VERSION ""

NS_ :

BS_:

BU_: Vector__XXX

BA_DEF_ "BusType" STRING ;
BA_DEF_ BO_ "VFrameFormat" ENUM "StandardCAN","ExtendedCAN","reserved","J1939PG";
BA_DEF_DEF_ "BusType" "CAN";
BA_DEF_DEF_ "VFrameFormat" 0;

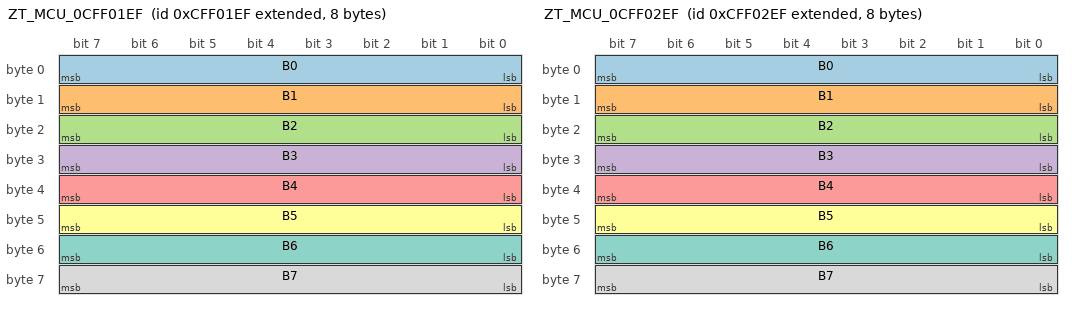
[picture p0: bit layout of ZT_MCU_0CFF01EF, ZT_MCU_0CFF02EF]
BO_ 2365522415 ZT_MCU_0CFF01EF: 8 Vector__XXX
 SG_ B0 : 0|8@1+ (1,0) [0|255] "" Vector__XXX
 SG_ B1 : 8|8@1+ (1,0) [0|255] "" Vector__XXX
 SG_ B2 : 16|8@1+ (1,0) [0|255] "" Vector__XXX
 SG_ B3 : 24|8@1+ (1,0) [0|255] "" Vector__XXX
 SG_ B4 : 32|8@1+ (1,0) [0|255] "" Vector__XXX
 SG_ B5 : 40|8@1+ (1,0) [0|255] "" Vector__XXX
 SG_ B6 : 48|8@1+ (1,0) [0|255] "" Vector__XXX
 SG_ B7 : 56|8@1+ (1,0) [0|255] "" Vector__XXX

BA_ "VFrameFormat" BO_ 2365522415 1;
CM_ BO_ 2365522415 "0x5C0002 中通新能源 > 中通物流 > 系统诊断 > 电机控制模块(MCU) | 部件: 电机控制模块(MCU)";

BO_ 2365522671 ZT_MCU_0CFF02EF: 8 Vector__XXX
 SG_ B0 : 0|8@1+ (1,0) [0|255] "" Vector__XXX
 SG_ B1 : 8|8@1+ (1,0) [0|255] "" Vector__XXX
 SG_ B2 : 16|8@1+ (1,0) [0|255] "" Vector__XXX
 SG_ B3 : 24|8@1+ (1,0) [0|255] "" Vector__XXX
 SG_ B4 : 32|8@1+ (1,0) [0|255] "" Vector__XXX
 SG_ B5 : 40|8@1+ (1,0) [0|255] "" Vector__XXX
 SG_ B6 : 48|8@1+ (1,0) [0|255] "" Vector__XXX
 SG_ B7 : 56|8@1+ (1,0) [0|255] "" Vector__XXX

BA_ "VFrameFormat" BO_ 2365522671 1;
CM_ BO_ 2365522671 "0x5C0002 中通新能源 > 中通物流 > 系统诊断 > 电机控制模块(MCU) | 部件: 电机控制模块(MCU)";

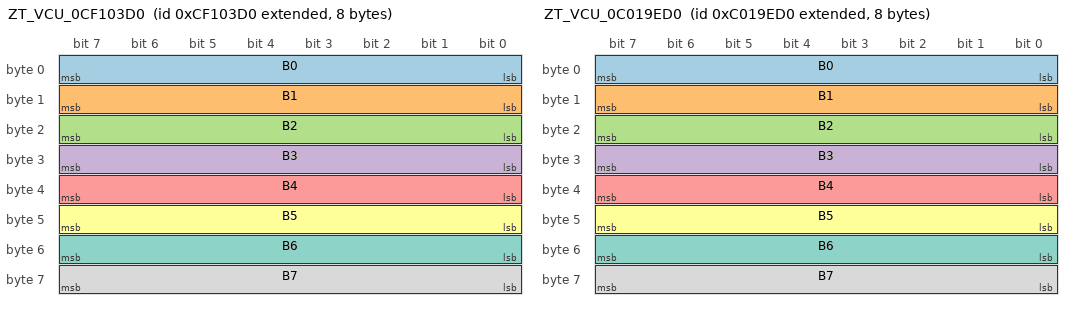
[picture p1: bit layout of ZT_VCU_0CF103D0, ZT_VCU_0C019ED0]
BO_ 2364605392 ZT_VCU_0CF103D0: 8 Vector__XXX
 SG_ B0 : 0|8@1+ (1,0) [0|255] "" Vector__XXX
 SG_ B1 : 8|8@1+ (1,0) [0|255] "" Vector__XXX
 SG_ B2 : 16|8@1+ (1,0) [0|255] "" Vector__XXX
 SG_ B3 : 24|8@1+ (1,0) [0|255] "" Vector__XXX
 SG_ B4 : 32|8@1+ (1,0) [0|255] "" Vector__XXX
 SG_ B5 : 40|8@1+ (1,0) [0|255] "" Vector__XXX
 SG_ B6 : 48|8@1+ (1,0) [0|255] "" Vector__XXX
 SG_ B7 : 56|8@1+ (1,0) [0|255] "" Vector__XXX

BA_ "VFrameFormat" BO_ 2364605392 1;
CM_ BO_ 2364605392 "0x5C0003 中通新能源 > 中通物流 > 系统诊断 > 整车控制模块(VCU) | 部件: 整车控制模块(VCU)";

BO_ 2348916432 ZT_VCU_0C019ED0: 8 Vector__XXX
 SG_ B0 : 0|8@1+ (1,0) [0|255] "" Vector__XXX
 SG_ B1 : 8|8@1+ (1,0) [0|255] "" Vector__XXX
 SG_ B2 : 16|8@1+ (1,0) [0|255] "" Vector__XXX
 SG_ B3 : 24|8@1+ (1,0) [0|255] "" Vector__XXX
 SG_ B4 : 32|8@1+ (1,0) [0|255] "" Vector__XXX
 SG_ B5 : 40|8@1+ (1,0) [0|255] "" Vector__XXX
 SG_ B6 : 48|8@1+ (1,0) [0|255] "" Vector__XXX
 SG_ B7 : 56|8@1+ (1,0) [0|255] "" Vector__XXX

BA_ "VFrameFormat" BO_ 2348916432 1;
CM_ BO_ 2348916432 "0x5C0003 中通新能源 > 中通物流 > 系统诊断 > 整车控制模块(VCU) | 部件: 整车控制模块(VCU)";

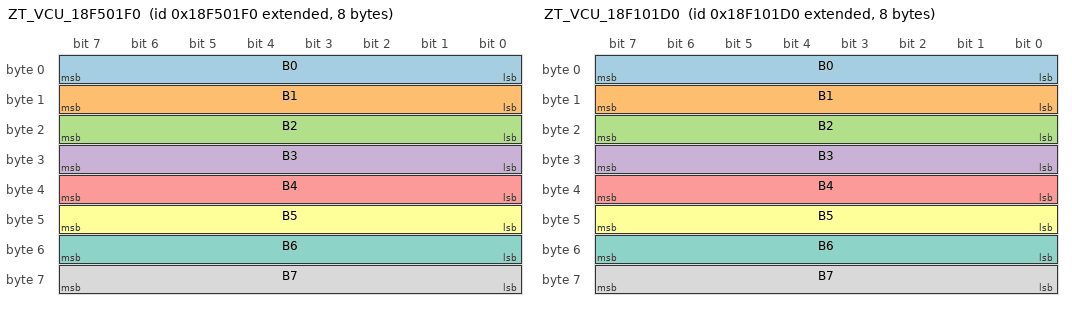
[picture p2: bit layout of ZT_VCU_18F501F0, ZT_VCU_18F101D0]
BO_ 2566193648 ZT_VCU_18F501F0: 8 Vector__XXX
 SG_ B0 : 0|8@1+ (1,0) [0|255] "" Vector__XXX
 SG_ B1 : 8|8@1+ (1,0) [0|255] "" Vector__XXX
 SG_ B2 : 16|8@1+ (1,0) [0|255] "" Vector__XXX
 SG_ B3 : 24|8@1+ (1,0) [0|255] "" Vector__XXX
 SG_ B4 : 32|8@1+ (1,0) [0|255] "" Vector__XXX
 SG_ B5 : 40|8@1+ (1,0) [0|255] "" Vector__XXX
 SG_ B6 : 48|8@1+ (1,0) [0|255] "" Vector__XXX
 SG_ B7 : 56|8@1+ (1,0) [0|255] "" Vector__XXX

BA_ "VFrameFormat" BO_ 2566193648 1;
CM_ BO_ 2566193648 "0x5C0003 中通新能源 > 中通物流 > 系统诊断 > 整车控制模块(VCU) | 部件: 整车控制模块(VCU)";

BO_ 2565931472 ZT_VCU_18F101D0: 8 Vector__XXX
 SG_ B0 : 0|8@1+ (1,0) [0|255] "" Vector__XXX
 SG_ B1 : 8|8@1+ (1,0) [0|255] "" Vector__XXX
 SG_ B2 : 16|8@1+ (1,0) [0|255] "" Vector__XXX
 SG_ B3 : 24|8@1+ (1,0) [0|255] "" Vector__XXX
 SG_ B4 : 32|8@1+ (1,0) [0|255] "" Vector__XXX
 SG_ B5 : 40|8@1+ (1,0) [0|255] "" Vector__XXX
 SG_ B6 : 48|8@1+ (1,0) [0|255] "" Vector__XXX
 SG_ B7 : 56|8@1+ (1,0) [0|255] "" Vector__XXX

BA_ "VFrameFormat" BO_ 2565931472 1;
CM_ BO_ 2565931472 "0x5C0003 中通新能源 > 中通物流 > 系统诊断 > 整车控制模块(VCU) | 部件: 整车控制模块(VCU)";

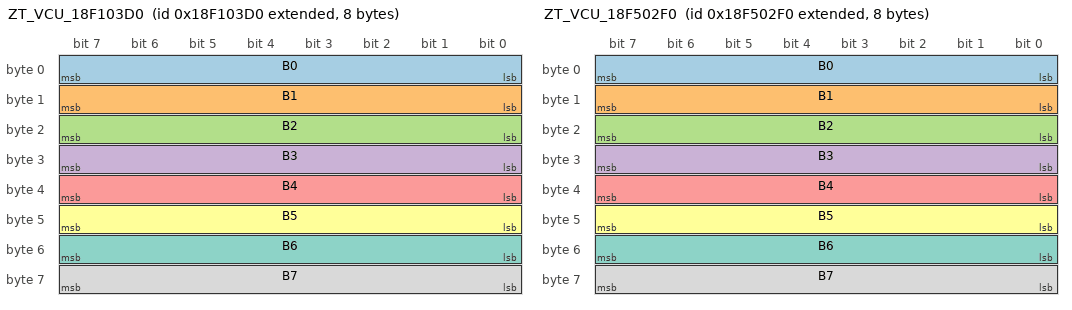
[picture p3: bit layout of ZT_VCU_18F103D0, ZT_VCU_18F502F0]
BO_ 2565931984 ZT_VCU_18F103D0: 8 Vector__XXX
 SG_ B0 : 0|8@1+ (1,0) [0|255] "" Vector__XXX
 SG_ B1 : 8|8@1+ (1,0) [0|255] "" Vector__XXX
 SG_ B2 : 16|8@1+ (1,0) [0|255] "" Vector__XXX
 SG_ B3 : 24|8@1+ (1,0) [0|255] "" Vector__XXX
 SG_ B4 : 32|8@1+ (1,0) [0|255] "" Vector__XXX
 SG_ B5 : 40|8@1+ (1,0) [0|255] "" Vector__XXX
 SG_ B6 : 48|8@1+ (1,0) [0|255] "" Vector__XXX
 SG_ B7 : 56|8@1+ (1,0) [0|255] "" Vector__XXX

BA_ "VFrameFormat" BO_ 2565931984 1;
CM_ BO_ 2565931984 "0x5C0003 中通新能源 > 中通物流 > 系统诊断 > 整车控制模块(VCU) | 部件: 整车控制模块(VCU)";

BO_ 2566193904 ZT_VCU_18F502F0: 8 Vector__XXX
 SG_ B0 : 0|8@1+ (1,0) [0|255] "" Vector__XXX
 SG_ B1 : 8|8@1+ (1,0) [0|255] "" Vector__XXX
 SG_ B2 : 16|8@1+ (1,0) [0|255] "" Vector__XXX
 SG_ B3 : 24|8@1+ (1,0) [0|255] "" Vector__XXX
 SG_ B4 : 32|8@1+ (1,0) [0|255] "" Vector__XXX
 SG_ B5 : 40|8@1+ (1,0) [0|255] "" Vector__XXX
 SG_ B6 : 48|8@1+ (1,0) [0|255] "" Vector__XXX
 SG_ B7 : 56|8@1+ (1,0) [0|255] "" Vector__XXX

BA_ "VFrameFormat" BO_ 2566193904 1;
CM_ BO_ 2566193904 "0x5C0003 中通新能源 > 中通物流 > 系统诊断 > 整车控制模块(VCU) | 部件: 整车控制模块(VCU)";

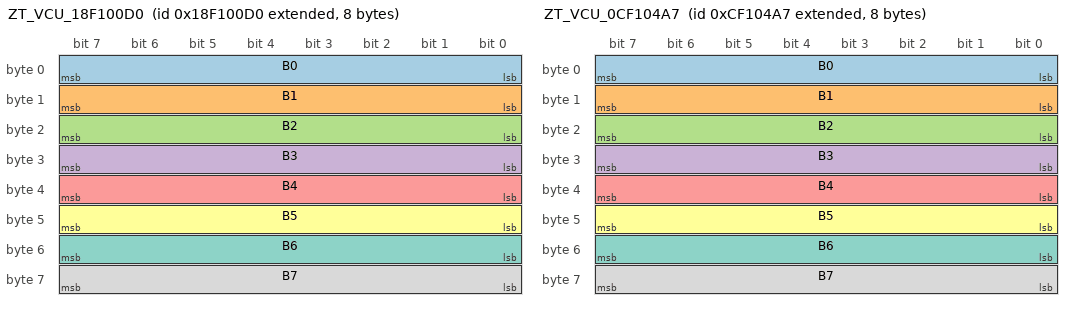
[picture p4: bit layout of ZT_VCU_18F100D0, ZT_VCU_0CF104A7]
BO_ 2565931216 ZT_VCU_18F100D0: 8 Vector__XXX
 SG_ B0 : 0|8@1+ (1,0) [0|255] "" Vector__XXX
 SG_ B1 : 8|8@1+ (1,0) [0|255] "" Vector__XXX
 SG_ B2 : 16|8@1+ (1,0) [0|255] "" Vector__XXX
 SG_ B3 : 24|8@1+ (1,0) [0|255] "" Vector__XXX
 SG_ B4 : 32|8@1+ (1,0) [0|255] "" Vector__XXX
 SG_ B5 : 40|8@1+ (1,0) [0|255] "" Vector__XXX
 SG_ B6 : 48|8@1+ (1,0) [0|255] "" Vector__XXX
 SG_ B7 : 56|8@1+ (1,0) [0|255] "" Vector__XXX

BA_ "VFrameFormat" BO_ 2565931216 1;
CM_ BO_ 2565931216 "0x5C0003 中通新能源 > 中通物流 > 系统诊断 > 整车控制模块(VCU) | 部件: 整车控制模块(VCU)";

BO_ 2364605607 ZT_VCU_0CF104A7: 8 Vector__XXX
 SG_ B0 : 0|8@1+ (1,0) [0|255] "" Vector__XXX
 SG_ B1 : 8|8@1+ (1,0) [0|255] "" Vector__XXX
 SG_ B2 : 16|8@1+ (1,0) [0|255] "" Vector__XXX
 SG_ B3 : 24|8@1+ (1,0) [0|255] "" Vector__XXX
 SG_ B4 : 32|8@1+ (1,0) [0|255] "" Vector__XXX
 SG_ B5 : 40|8@1+ (1,0) [0|255] "" Vector__XXX
 SG_ B6 : 48|8@1+ (1,0) [0|255] "" Vector__XXX
 SG_ B7 : 56|8@1+ (1,0) [0|255] "" Vector__XXX

BA_ "VFrameFormat" BO_ 2364605607 1;
CM_ BO_ 2364605607 "0x5C0003 中通新能源 > 中通物流 > 系统诊断 > 整车控制模块(VCU) | 部件: 整车控制模块(VCU)";

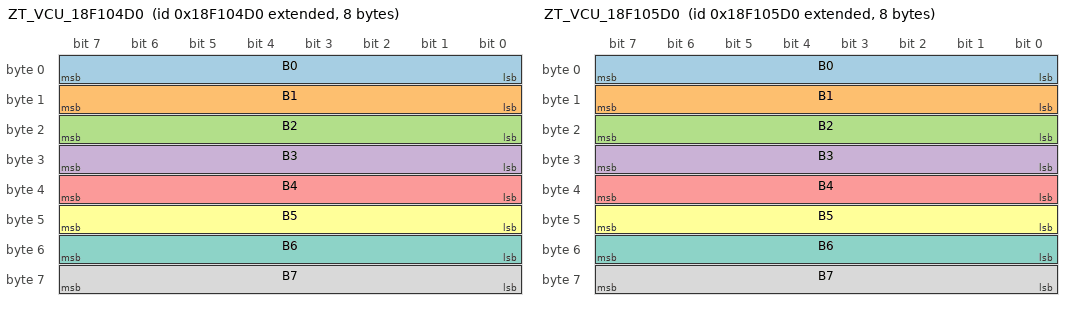
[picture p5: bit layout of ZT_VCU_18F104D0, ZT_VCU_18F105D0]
BO_ 2565932240 ZT_VCU_18F104D0: 8 Vector__XXX
 SG_ B0 : 0|8@1+ (1,0) [0|255] "" Vector__XXX
 SG_ B1 : 8|8@1+ (1,0) [0|255] "" Vector__XXX
 SG_ B2 : 16|8@1+ (1,0) [0|255] "" Vector__XXX
 SG_ B3 : 24|8@1+ (1,0) [0|255] "" Vector__XXX
 SG_ B4 : 32|8@1+ (1,0) [0|255] "" Vector__XXX
 SG_ B5 : 40|8@1+ (1,0) [0|255] "" Vector__XXX
 SG_ B6 : 48|8@1+ (1,0) [0|255] "" Vector__XXX
 SG_ B7 : 56|8@1+ (1,0) [0|255] "" Vector__XXX

BA_ "VFrameFormat" BO_ 2565932240 1;
CM_ BO_ 2565932240 "0x5C0003 中通新能源 > 中通物流 > 系统诊断 > 整车控制模块(VCU) | 部件: 整车控制模块(VCU)";

BO_ 2565932496 ZT_VCU_18F105D0: 8 Vector__XXX
 SG_ B0 : 0|8@1+ (1,0) [0|255] "" Vector__XXX
 SG_ B1 : 8|8@1+ (1,0) [0|255] "" Vector__XXX
 SG_ B2 : 16|8@1+ (1,0) [0|255] "" Vector__XXX
 SG_ B3 : 24|8@1+ (1,0) [0|255] "" Vector__XXX
 SG_ B4 : 32|8@1+ (1,0) [0|255] "" Vector__XXX
 SG_ B5 : 40|8@1+ (1,0) [0|255] "" Vector__XXX
 SG_ B6 : 48|8@1+ (1,0) [0|255] "" Vector__XXX
 SG_ B7 : 56|8@1+ (1,0) [0|255] "" Vector__XXX

BA_ "VFrameFormat" BO_ 2565932496 1;
CM_ BO_ 2565932496 "0x5C0003 中通新能源 > 中通物流 > 系统诊断 > 整车控制模块(VCU) | 部件: 整车控制模块(VCU)";

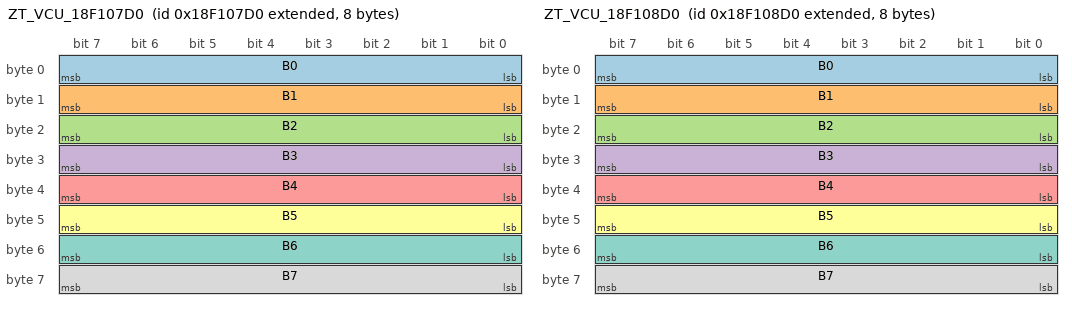
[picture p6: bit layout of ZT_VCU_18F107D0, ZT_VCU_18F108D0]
BO_ 2565933008 ZT_VCU_18F107D0: 8 Vector__XXX
 SG_ B0 : 0|8@1+ (1,0) [0|255] "" Vector__XXX
 SG_ B1 : 8|8@1+ (1,0) [0|255] "" Vector__XXX
 SG_ B2 : 16|8@1+ (1,0) [0|255] "" Vector__XXX
 SG_ B3 : 24|8@1+ (1,0) [0|255] "" Vector__XXX
 SG_ B4 : 32|8@1+ (1,0) [0|255] "" Vector__XXX
 SG_ B5 : 40|8@1+ (1,0) [0|255] "" Vector__XXX
 SG_ B6 : 48|8@1+ (1,0) [0|255] "" Vector__XXX
 SG_ B7 : 56|8@1+ (1,0) [0|255] "" Vector__XXX

BA_ "VFrameFormat" BO_ 2565933008 1;
CM_ BO_ 2565933008 "0x5C0003 中通新能源 > 中通物流 > 系统诊断 > 整车控制模块(VCU) | 部件: 整车控制模块(VCU)";

BO_ 2565933264 ZT_VCU_18F108D0: 8 Vector__XXX
 SG_ B0 : 0|8@1+ (1,0) [0|255] "" Vector__XXX
 SG_ B1 : 8|8@1+ (1,0) [0|255] "" Vector__XXX
 SG_ B2 : 16|8@1+ (1,0) [0|255] "" Vector__XXX
 SG_ B3 : 24|8@1+ (1,0) [0|255] "" Vector__XXX
 SG_ B4 : 32|8@1+ (1,0) [0|255] "" Vector__XXX
 SG_ B5 : 40|8@1+ (1,0) [0|255] "" Vector__XXX
 SG_ B6 : 48|8@1+ (1,0) [0|255] "" Vector__XXX
 SG_ B7 : 56|8@1+ (1,0) [0|255] "" Vector__XXX

BA_ "VFrameFormat" BO_ 2565933264 1;
CM_ BO_ 2565933264 "0x5C0003 中通新能源 > 中通物流 > 系统诊断 > 整车控制模块(VCU) | 部件: 整车控制模块(VCU)";

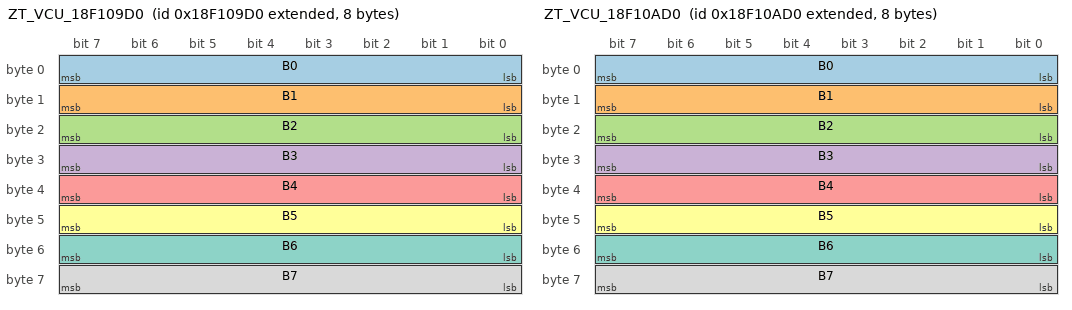
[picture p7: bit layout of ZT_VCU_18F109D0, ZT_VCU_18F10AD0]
BO_ 2565933520 ZT_VCU_18F109D0: 8 Vector__XXX
 SG_ B0 : 0|8@1+ (1,0) [0|255] "" Vector__XXX
 SG_ B1 : 8|8@1+ (1,0) [0|255] "" Vector__XXX
 SG_ B2 : 16|8@1+ (1,0) [0|255] "" Vector__XXX
 SG_ B3 : 24|8@1+ (1,0) [0|255] "" Vector__XXX
 SG_ B4 : 32|8@1+ (1,0) [0|255] "" Vector__XXX
 SG_ B5 : 40|8@1+ (1,0) [0|255] "" Vector__XXX
 SG_ B6 : 48|8@1+ (1,0) [0|255] "" Vector__XXX
 SG_ B7 : 56|8@1+ (1,0) [0|255] "" Vector__XXX

BA_ "VFrameFormat" BO_ 2565933520 1;
CM_ BO_ 2565933520 "0x5C0003 中通新能源 > 中通物流 > 系统诊断 > 整车控制模块(VCU) | 部件: 整车控制模块(VCU)";

BO_ 2565933776 ZT_VCU_18F10AD0: 8 Vector__XXX
 SG_ B0 : 0|8@1+ (1,0) [0|255] "" Vector__XXX
 SG_ B1 : 8|8@1+ (1,0) [0|255] "" Vector__XXX
 SG_ B2 : 16|8@1+ (1,0) [0|255] "" Vector__XXX
 SG_ B3 : 24|8@1+ (1,0) [0|255] "" Vector__XXX
 SG_ B4 : 32|8@1+ (1,0) [0|255] "" Vector__XXX
 SG_ B5 : 40|8@1+ (1,0) [0|255] "" Vector__XXX
 SG_ B6 : 48|8@1+ (1,0) [0|255] "" Vector__XXX
 SG_ B7 : 56|8@1+ (1,0) [0|255] "" Vector__XXX

BA_ "VFrameFormat" BO_ 2565933776 1;
CM_ BO_ 2565933776 "0x5C0003 中通新能源 > 中通物流 > 系统诊断 > 整车控制模块(VCU) | 部件: 整车控制模块(VCU)";

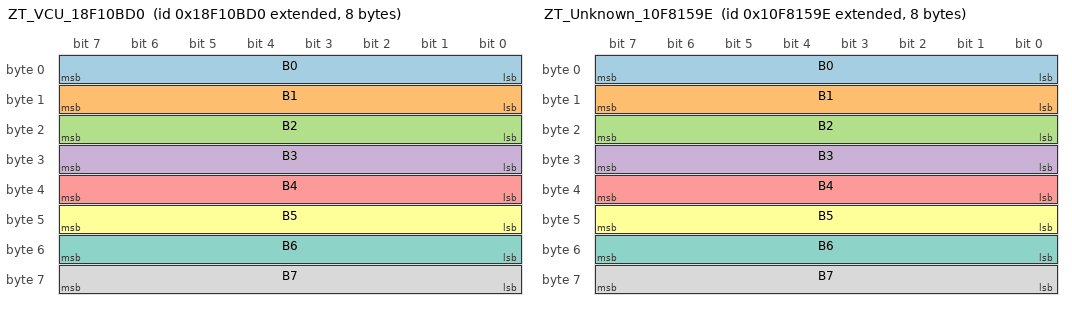
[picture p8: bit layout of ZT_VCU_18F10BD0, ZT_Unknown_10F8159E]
BO_ 2565934032 ZT_VCU_18F10BD0: 8 Vector__XXX
 SG_ B0 : 0|8@1+ (1,0) [0|255] "" Vector__XXX
 SG_ B1 : 8|8@1+ (1,0) [0|255] "" Vector__XXX
 SG_ B2 : 16|8@1+ (1,0) [0|255] "" Vector__XXX
 SG_ B3 : 24|8@1+ (1,0) [0|255] "" Vector__XXX
 SG_ B4 : 32|8@1+ (1,0) [0|255] "" Vector__XXX
 SG_ B5 : 40|8@1+ (1,0) [0|255] "" Vector__XXX
 SG_ B6 : 48|8@1+ (1,0) [0|255] "" Vector__XXX
 SG_ B7 : 56|8@1+ (1,0) [0|255] "" Vector__XXX

BA_ "VFrameFormat" BO_ 2565934032 1;
CM_ BO_ 2565934032 "0x5C0003 中通新能源 > 中通物流 > 系统诊断 > 整车控制模块(VCU) | 部件: 整车控制模块(VCU)";

BO_ 2432177566 ZT_Unknown_10F8159E: 8 Vector__XXX
 SG_ B0 : 0|8@1+ (1,0) [0|255] "" Vector__XXX
 SG_ B1 : 8|8@1+ (1,0) [0|255] "" Vector__XXX
 SG_ B2 : 16|8@1+ (1,0) [0|255] "" Vector__XXX
 SG_ B3 : 24|8@1+ (1,0) [0|255] "" Vector__XXX
 SG_ B4 : 32|8@1+ (1,0) [0|255] "" Vector__XXX
 SG_ B5 : 40|8@1+ (1,0) [0|255] "" Vector__XXX
 SG_ B6 : 48|8@1+ (1,0) [0|255] "" Vector__XXX
 SG_ B7 : 56|8@1+ (1,0) [0|255] "" Vector__XXX

BA_ "VFrameFormat" BO_ 2432177566 1;
CM_ BO_ 2432177566 "0x5C0004 NO_CN_ROOT_ID | 部件: NO_CN_ROOT_ID";

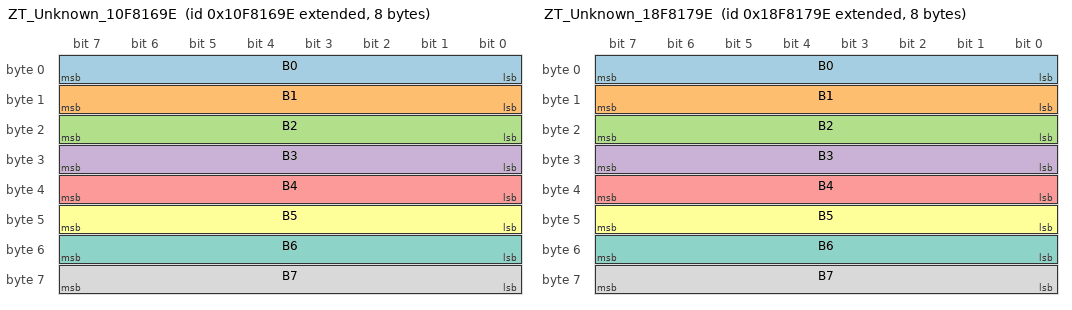
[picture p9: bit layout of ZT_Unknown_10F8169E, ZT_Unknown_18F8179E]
BO_ 2432177822 ZT_Unknown_10F8169E: 8 Vector__XXX
 SG_ B0 : 0|8@1+ (1,0) [0|255] "" Vector__XXX
 SG_ B1 : 8|8@1+ (1,0) [0|255] "" Vector__XXX
 SG_ B2 : 16|8@1+ (1,0) [0|255] "" Vector__XXX
 SG_ B3 : 24|8@1+ (1,0) [0|255] "" Vector__XXX
 SG_ B4 : 32|8@1+ (1,0) [0|255] "" Vector__XXX
 SG_ B5 : 40|8@1+ (1,0) [0|255] "" Vector__XXX
 SG_ B6 : 48|8@1+ (1,0) [0|255] "" Vector__XXX
 SG_ B7 : 56|8@1+ (1,0) [0|255] "" Vector__XXX

BA_ "VFrameFormat" BO_ 2432177822 1;
CM_ BO_ 2432177822 "0x5C0004 NO_CN_ROOT_ID | 部件: NO_CN_ROOT_ID";

BO_ 2566395806 ZT_Unknown_18F8179E: 8 Vector__XXX
 SG_ B0 : 0|8@1+ (1,0) [0|255] "" Vector__XXX
 SG_ B1 : 8|8@1+ (1,0) [0|255] "" Vector__XXX
 SG_ B2 : 16|8@1+ (1,0) [0|255] "" Vector__XXX
 SG_ B3 : 24|8@1+ (1,0) [0|255] "" Vector__XXX
 SG_ B4 : 32|8@1+ (1,0) [0|255] "" Vector__XXX
 SG_ B5 : 40|8@1+ (1,0) [0|255] "" Vector__XXX
 SG_ B6 : 48|8@1+ (1,0) [0|255] "" Vector__XXX
 SG_ B7 : 56|8@1+ (1,0) [0|255] "" Vector__XXX

BA_ "VFrameFormat" BO_ 2566395806 1;
CM_ BO_ 2566395806 "0x5C0004 NO_CN_ROOT_ID | 部件: NO_CN_ROOT_ID";

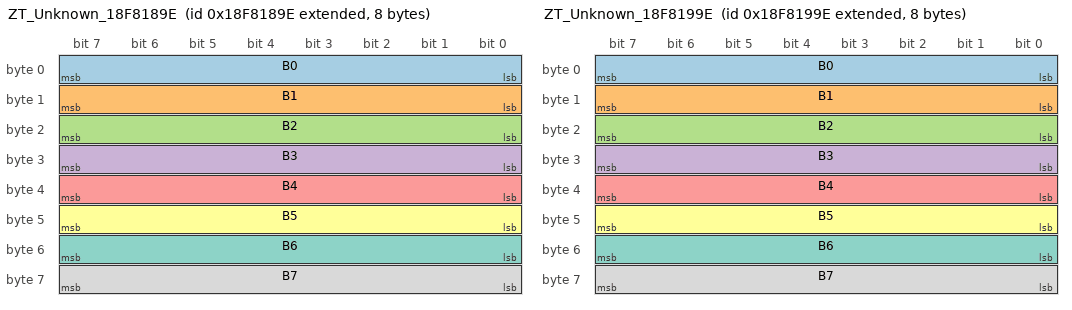
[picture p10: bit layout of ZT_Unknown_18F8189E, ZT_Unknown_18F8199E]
BO_ 2566396062 ZT_Unknown_18F8189E: 8 Vector__XXX
 SG_ B0 : 0|8@1+ (1,0) [0|255] "" Vector__XXX
 SG_ B1 : 8|8@1+ (1,0) [0|255] "" Vector__XXX
 SG_ B2 : 16|8@1+ (1,0) [0|255] "" Vector__XXX
 SG_ B3 : 24|8@1+ (1,0) [0|255] "" Vector__XXX
 SG_ B4 : 32|8@1+ (1,0) [0|255] "" Vector__XXX
 SG_ B5 : 40|8@1+ (1,0) [0|255] "" Vector__XXX
 SG_ B6 : 48|8@1+ (1,0) [0|255] "" Vector__XXX
 SG_ B7 : 56|8@1+ (1,0) [0|255] "" Vector__XXX

BA_ "VFrameFormat" BO_ 2566396062 1;
CM_ BO_ 2566396062 "0x5C0004 NO_CN_ROOT_ID | 部件: NO_CN_ROOT_ID";

BO_ 2566396318 ZT_Unknown_18F8199E: 8 Vector__XXX
 SG_ B0 : 0|8@1+ (1,0) [0|255] "" Vector__XXX
 SG_ B1 : 8|8@1+ (1,0) [0|255] "" Vector__XXX
 SG_ B2 : 16|8@1+ (1,0) [0|255] "" Vector__XXX
 SG_ B3 : 24|8@1+ (1,0) [0|255] "" Vector__XXX
 SG_ B4 : 32|8@1+ (1,0) [0|255] "" Vector__XXX
 SG_ B5 : 40|8@1+ (1,0) [0|255] "" Vector__XXX
 SG_ B6 : 48|8@1+ (1,0) [0|255] "" Vector__XXX
 SG_ B7 : 56|8@1+ (1,0) [0|255] "" Vector__XXX

BA_ "VFrameFormat" BO_ 2566396318 1;
CM_ BO_ 2566396318 "0x5C0004 NO_CN_ROOT_ID | 部件: NO_CN_ROOT_ID";

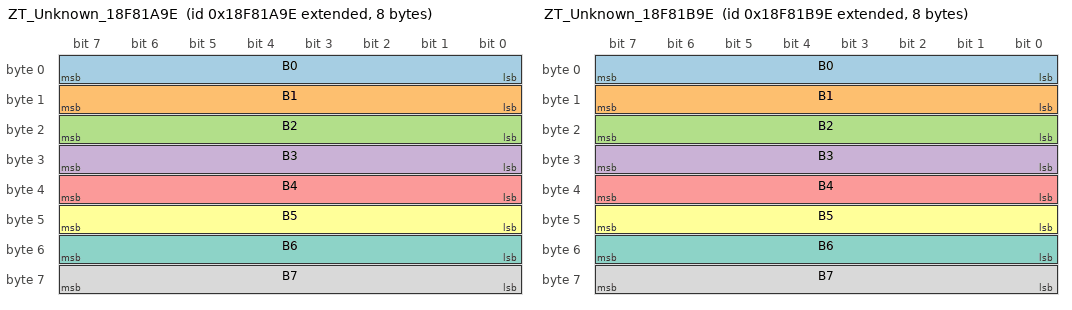
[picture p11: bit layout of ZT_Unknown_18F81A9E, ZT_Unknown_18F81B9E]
BO_ 2566396574 ZT_Unknown_18F81A9E: 8 Vector__XXX
 SG_ B0 : 0|8@1+ (1,0) [0|255] "" Vector__XXX
 SG_ B1 : 8|8@1+ (1,0) [0|255] "" Vector__XXX
 SG_ B2 : 16|8@1+ (1,0) [0|255] "" Vector__XXX
 SG_ B3 : 24|8@1+ (1,0) [0|255] "" Vector__XXX
 SG_ B4 : 32|8@1+ (1,0) [0|255] "" Vector__XXX
 SG_ B5 : 40|8@1+ (1,0) [0|255] "" Vector__XXX
 SG_ B6 : 48|8@1+ (1,0) [0|255] "" Vector__XXX
 SG_ B7 : 56|8@1+ (1,0) [0|255] "" Vector__XXX

BA_ "VFrameFormat" BO_ 2566396574 1;
CM_ BO_ 2566396574 "0x5C0004 NO_CN_ROOT_ID | 部件: NO_CN_ROOT_ID";

BO_ 2566396830 ZT_Unknown_18F81B9E: 8 Vector__XXX
 SG_ B0 : 0|8@1+ (1,0) [0|255] "" Vector__XXX
 SG_ B1 : 8|8@1+ (1,0) [0|255] "" Vector__XXX
 SG_ B2 : 16|8@1+ (1,0) [0|255] "" Vector__XXX
 SG_ B3 : 24|8@1+ (1,0) [0|255] "" Vector__XXX
 SG_ B4 : 32|8@1+ (1,0) [0|255] "" Vector__XXX
 SG_ B5 : 40|8@1+ (1,0) [0|255] "" Vector__XXX
 SG_ B6 : 48|8@1+ (1,0) [0|255] "" Vector__XXX
 SG_ B7 : 56|8@1+ (1,0) [0|255] "" Vector__XXX

BA_ "VFrameFormat" BO_ 2566396830 1;
CM_ BO_ 2566396830 "0x5C0004 NO_CN_ROOT_ID | 部件: NO_CN_ROOT_ID";

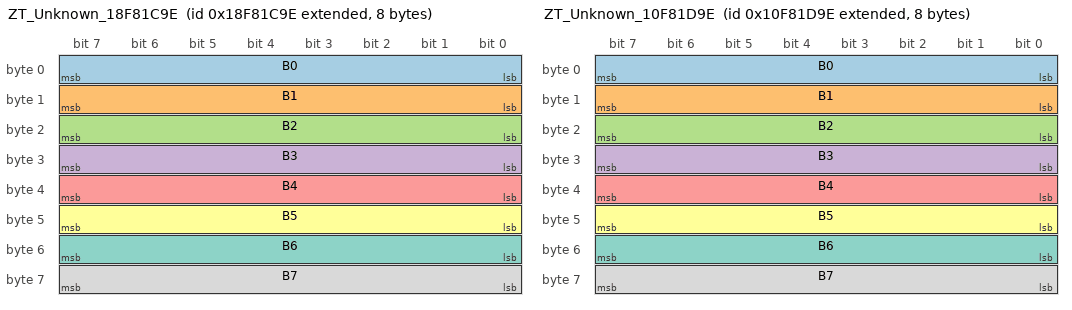
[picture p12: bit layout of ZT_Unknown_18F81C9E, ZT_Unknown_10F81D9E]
BO_ 2566397086 ZT_Unknown_18F81C9E: 8 Vector__XXX
 SG_ B0 : 0|8@1+ (1,0) [0|255] "" Vector__XXX
 SG_ B1 : 8|8@1+ (1,0) [0|255] "" Vector__XXX
 SG_ B2 : 16|8@1+ (1,0) [0|255] "" Vector__XXX
 SG_ B3 : 24|8@1+ (1,0) [0|255] "" Vector__XXX
 SG_ B4 : 32|8@1+ (1,0) [0|255] "" Vector__XXX
 SG_ B5 : 40|8@1+ (1,0) [0|255] "" Vector__XXX
 SG_ B6 : 48|8@1+ (1,0) [0|255] "" Vector__XXX
 SG_ B7 : 56|8@1+ (1,0) [0|255] "" Vector__XXX

BA_ "VFrameFormat" BO_ 2566397086 1;
CM_ BO_ 2566397086 "0x5C0004 NO_CN_ROOT_ID | 部件: NO_CN_ROOT_ID";

BO_ 2432179614 ZT_Unknown_10F81D9E: 8 Vector__XXX
 SG_ B0 : 0|8@1+ (1,0) [0|255] "" Vector__XXX
 SG_ B1 : 8|8@1+ (1,0) [0|255] "" Vector__XXX
 SG_ B2 : 16|8@1+ (1,0) [0|255] "" Vector__XXX
 SG_ B3 : 24|8@1+ (1,0) [0|255] "" Vector__XXX
 SG_ B4 : 32|8@1+ (1,0) [0|255] "" Vector__XXX
 SG_ B5 : 40|8@1+ (1,0) [0|255] "" Vector__XXX
 SG_ B6 : 48|8@1+ (1,0) [0|255] "" Vector__XXX
 SG_ B7 : 56|8@1+ (1,0) [0|255] "" Vector__XXX

BA_ "VFrameFormat" BO_ 2432179614 1;
CM_ BO_ 2432179614 "0x5C0004 NO_CN_ROOT_ID | 部件: NO_CN_ROOT_ID";

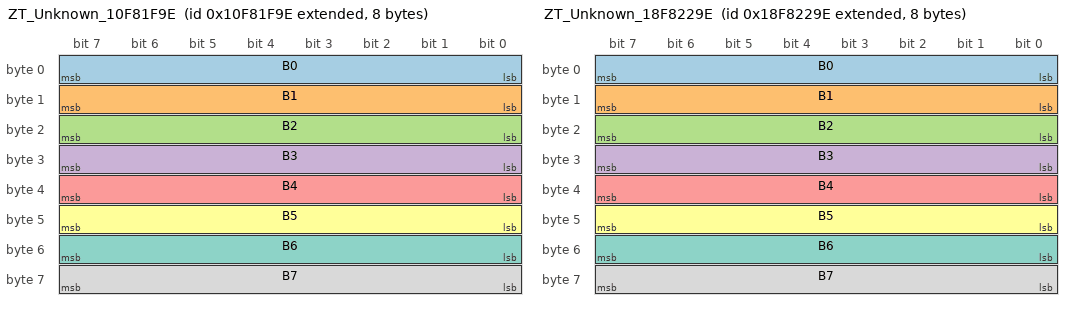
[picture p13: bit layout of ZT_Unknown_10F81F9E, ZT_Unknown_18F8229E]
BO_ 2432180126 ZT_Unknown_10F81F9E: 8 Vector__XXX
 SG_ B0 : 0|8@1+ (1,0) [0|255] "" Vector__XXX
 SG_ B1 : 8|8@1+ (1,0) [0|255] "" Vector__XXX
 SG_ B2 : 16|8@1+ (1,0) [0|255] "" Vector__XXX
 SG_ B3 : 24|8@1+ (1,0) [0|255] "" Vector__XXX
 SG_ B4 : 32|8@1+ (1,0) [0|255] "" Vector__XXX
 SG_ B5 : 40|8@1+ (1,0) [0|255] "" Vector__XXX
 SG_ B6 : 48|8@1+ (1,0) [0|255] "" Vector__XXX
 SG_ B7 : 56|8@1+ (1,0) [0|255] "" Vector__XXX

BA_ "VFrameFormat" BO_ 2432180126 1;
CM_ BO_ 2432180126 "0x5C0004 NO_CN_ROOT_ID | 部件: NO_CN_ROOT_ID";

BO_ 2566398622 ZT_Unknown_18F8229E: 8 Vector__XXX
 SG_ B0 : 0|8@1+ (1,0) [0|255] "" Vector__XXX
 SG_ B1 : 8|8@1+ (1,0) [0|255] "" Vector__XXX
 SG_ B2 : 16|8@1+ (1,0) [0|255] "" Vector__XXX
 SG_ B3 : 24|8@1+ (1,0) [0|255] "" Vector__XXX
 SG_ B4 : 32|8@1+ (1,0) [0|255] "" Vector__XXX
 SG_ B5 : 40|8@1+ (1,0) [0|255] "" Vector__XXX
 SG_ B6 : 48|8@1+ (1,0) [0|255] "" Vector__XXX
 SG_ B7 : 56|8@1+ (1,0) [0|255] "" Vector__XXX

BA_ "VFrameFormat" BO_ 2566398622 1;
CM_ BO_ 2566398622 "0x5C0004 NO_CN_ROOT_ID | 部件: NO_CN_ROOT_ID";

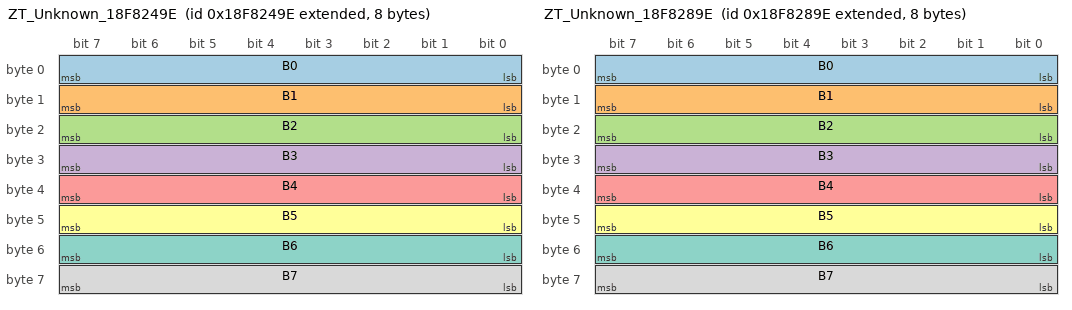
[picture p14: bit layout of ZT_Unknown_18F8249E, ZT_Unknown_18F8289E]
BO_ 2566399134 ZT_Unknown_18F8249E: 8 Vector__XXX
 SG_ B0 : 0|8@1+ (1,0) [0|255] "" Vector__XXX
 SG_ B1 : 8|8@1+ (1,0) [0|255] "" Vector__XXX
 SG_ B2 : 16|8@1+ (1,0) [0|255] "" Vector__XXX
 SG_ B3 : 24|8@1+ (1,0) [0|255] "" Vector__XXX
 SG_ B4 : 32|8@1+ (1,0) [0|255] "" Vector__XXX
 SG_ B5 : 40|8@1+ (1,0) [0|255] "" Vector__XXX
 SG_ B6 : 48|8@1+ (1,0) [0|255] "" Vector__XXX
 SG_ B7 : 56|8@1+ (1,0) [0|255] "" Vector__XXX

BA_ "VFrameFormat" BO_ 2566399134 1;
CM_ BO_ 2566399134 "0x5C0004 NO_CN_ROOT_ID | 部件: NO_CN_ROOT_ID";

BO_ 2566400158 ZT_Unknown_18F8289E: 8 Vector__XXX
 SG_ B0 : 0|8@1+ (1,0) [0|255] "" Vector__XXX
 SG_ B1 : 8|8@1+ (1,0) [0|255] "" Vector__XXX
 SG_ B2 : 16|8@1+ (1,0) [0|255] "" Vector__XXX
 SG_ B3 : 24|8@1+ (1,0) [0|255] "" Vector__XXX
 SG_ B4 : 32|8@1+ (1,0) [0|255] "" Vector__XXX
 SG_ B5 : 40|8@1+ (1,0) [0|255] "" Vector__XXX
 SG_ B6 : 48|8@1+ (1,0) [0|255] "" Vector__XXX
 SG_ B7 : 56|8@1+ (1,0) [0|255] "" Vector__XXX

BA_ "VFrameFormat" BO_ 2566400158 1;
CM_ BO_ 2566400158 "0x5C0004 NO_CN_ROOT_ID | 部件: NO_CN_ROOT_ID";

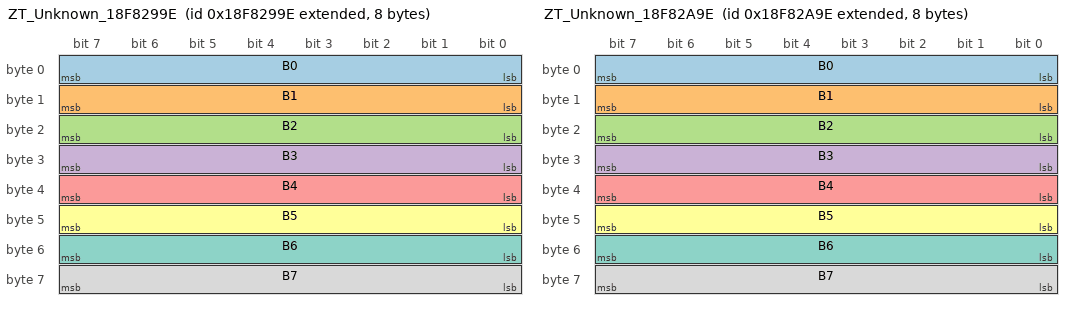
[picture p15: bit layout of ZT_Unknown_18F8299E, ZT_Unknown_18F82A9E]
BO_ 2566400414 ZT_Unknown_18F8299E: 8 Vector__XXX
 SG_ B0 : 0|8@1+ (1,0) [0|255] "" Vector__XXX
 SG_ B1 : 8|8@1+ (1,0) [0|255] "" Vector__XXX
 SG_ B2 : 16|8@1+ (1,0) [0|255] "" Vector__XXX
 SG_ B3 : 24|8@1+ (1,0) [0|255] "" Vector__XXX
 SG_ B4 : 32|8@1+ (1,0) [0|255] "" Vector__XXX
 SG_ B5 : 40|8@1+ (1,0) [0|255] "" Vector__XXX
 SG_ B6 : 48|8@1+ (1,0) [0|255] "" Vector__XXX
 SG_ B7 : 56|8@1+ (1,0) [0|255] "" Vector__XXX

BA_ "VFrameFormat" BO_ 2566400414 1;
CM_ BO_ 2566400414 "0x5C0004 NO_CN_ROOT_ID | 部件: NO_CN_ROOT_ID";

BO_ 2566400670 ZT_Unknown_18F82A9E: 8 Vector__XXX
 SG_ B0 : 0|8@1+ (1,0) [0|255] "" Vector__XXX
 SG_ B1 : 8|8@1+ (1,0) [0|255] "" Vector__XXX
 SG_ B2 : 16|8@1+ (1,0) [0|255] "" Vector__XXX
 SG_ B3 : 24|8@1+ (1,0) [0|255] "" Vector__XXX
 SG_ B4 : 32|8@1+ (1,0) [0|255] "" Vector__XXX
 SG_ B5 : 40|8@1+ (1,0) [0|255] "" Vector__XXX
 SG_ B6 : 48|8@1+ (1,0) [0|255] "" Vector__XXX
 SG_ B7 : 56|8@1+ (1,0) [0|255] "" Vector__XXX

BA_ "VFrameFormat" BO_ 2566400670 1;
CM_ BO_ 2566400670 "0x5C0004 NO_CN_ROOT_ID | 部件: NO_CN_ROOT_ID";

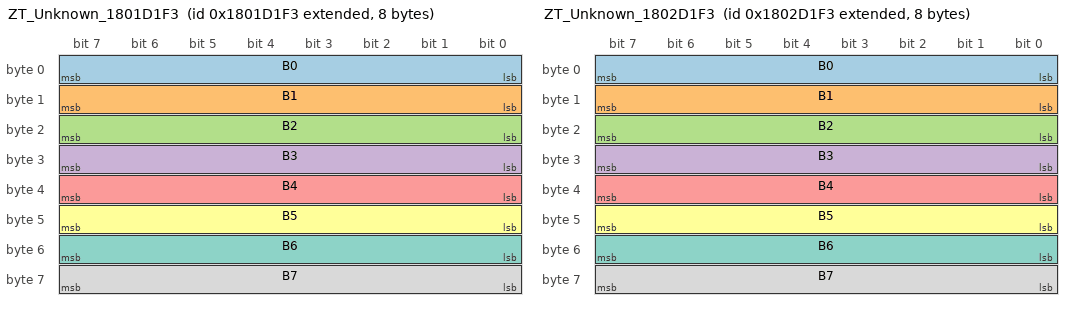
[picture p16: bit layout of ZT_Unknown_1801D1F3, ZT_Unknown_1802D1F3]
BO_ 2550256115 ZT_Unknown_1801D1F3: 8 Vector__XXX
 SG_ B0 : 0|8@1+ (1,0) [0|255] "" Vector__XXX
 SG_ B1 : 8|8@1+ (1,0) [0|255] "" Vector__XXX
 SG_ B2 : 16|8@1+ (1,0) [0|255] "" Vector__XXX
 SG_ B3 : 24|8@1+ (1,0) [0|255] "" Vector__XXX
 SG_ B4 : 32|8@1+ (1,0) [0|255] "" Vector__XXX
 SG_ B5 : 40|8@1+ (1,0) [0|255] "" Vector__XXX
 SG_ B6 : 48|8@1+ (1,0) [0|255] "" Vector__XXX
 SG_ B7 : 56|8@1+ (1,0) [0|255] "" Vector__XXX

BA_ "VFrameFormat" BO_ 2550256115 1;
CM_ BO_ 2550256115 "0x5C0004 NO_CN_ROOT_ID | 部件: NO_CN_ROOT_ID";

BO_ 2550321651 ZT_Unknown_1802D1F3: 8 Vector__XXX
 SG_ B0 : 0|8@1+ (1,0) [0|255] "" Vector__XXX
 SG_ B1 : 8|8@1+ (1,0) [0|255] "" Vector__XXX
 SG_ B2 : 16|8@1+ (1,0) [0|255] "" Vector__XXX
 SG_ B3 : 24|8@1+ (1,0) [0|255] "" Vector__XXX
 SG_ B4 : 32|8@1+ (1,0) [0|255] "" Vector__XXX
 SG_ B5 : 40|8@1+ (1,0) [0|255] "" Vector__XXX
 SG_ B6 : 48|8@1+ (1,0) [0|255] "" Vector__XXX
 SG_ B7 : 56|8@1+ (1,0) [0|255] "" Vector__XXX

BA_ "VFrameFormat" BO_ 2550321651 1;
CM_ BO_ 2550321651 "0x5C0004 NO_CN_ROOT_ID | 部件: NO_CN_ROOT_ID";

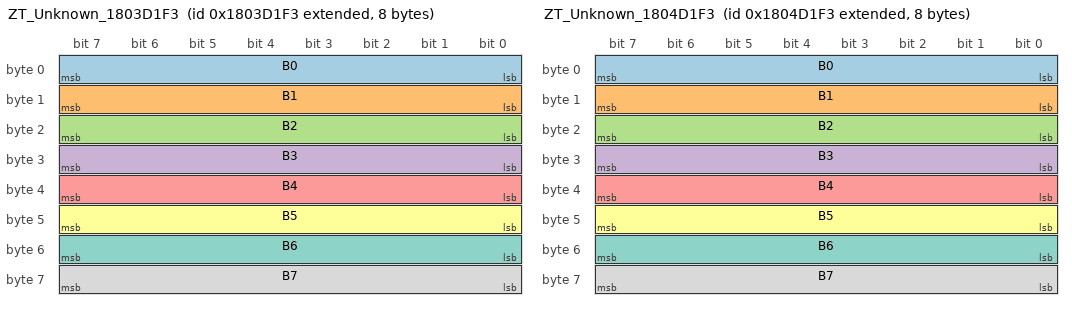
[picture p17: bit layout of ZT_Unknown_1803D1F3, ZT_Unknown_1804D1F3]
BO_ 2550387187 ZT_Unknown_1803D1F3: 8 Vector__XXX
 SG_ B0 : 0|8@1+ (1,0) [0|255] "" Vector__XXX
 SG_ B1 : 8|8@1+ (1,0) [0|255] "" Vector__XXX
 SG_ B2 : 16|8@1+ (1,0) [0|255] "" Vector__XXX
 SG_ B3 : 24|8@1+ (1,0) [0|255] "" Vector__XXX
 SG_ B4 : 32|8@1+ (1,0) [0|255] "" Vector__XXX
 SG_ B5 : 40|8@1+ (1,0) [0|255] "" Vector__XXX
 SG_ B6 : 48|8@1+ (1,0) [0|255] "" Vector__XXX
 SG_ B7 : 56|8@1+ (1,0) [0|255] "" Vector__XXX

BA_ "VFrameFormat" BO_ 2550387187 1;
CM_ BO_ 2550387187 "0x5C0004 NO_CN_ROOT_ID | 部件: NO_CN_ROOT_ID";

BO_ 2550452723 ZT_Unknown_1804D1F3: 8 Vector__XXX
 SG_ B0 : 0|8@1+ (1,0) [0|255] "" Vector__XXX
 SG_ B1 : 8|8@1+ (1,0) [0|255] "" Vector__XXX
 SG_ B2 : 16|8@1+ (1,0) [0|255] "" Vector__XXX
 SG_ B3 : 24|8@1+ (1,0) [0|255] "" Vector__XXX
 SG_ B4 : 32|8@1+ (1,0) [0|255] "" Vector__XXX
 SG_ B5 : 40|8@1+ (1,0) [0|255] "" Vector__XXX
 SG_ B6 : 48|8@1+ (1,0) [0|255] "" Vector__XXX
 SG_ B7 : 56|8@1+ (1,0) [0|255] "" Vector__XXX

BA_ "VFrameFormat" BO_ 2550452723 1;
CM_ BO_ 2550452723 "0x5C0004 NO_CN_ROOT_ID | 部件: NO_CN_ROOT_ID";

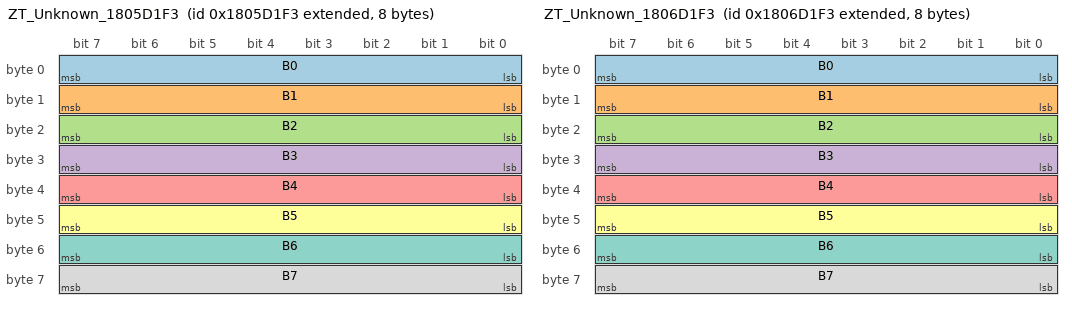
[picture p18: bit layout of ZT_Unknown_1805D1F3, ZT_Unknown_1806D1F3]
BO_ 2550518259 ZT_Unknown_1805D1F3: 8 Vector__XXX
 SG_ B0 : 0|8@1+ (1,0) [0|255] "" Vector__XXX
 SG_ B1 : 8|8@1+ (1,0) [0|255] "" Vector__XXX
 SG_ B2 : 16|8@1+ (1,0) [0|255] "" Vector__XXX
 SG_ B3 : 24|8@1+ (1,0) [0|255] "" Vector__XXX
 SG_ B4 : 32|8@1+ (1,0) [0|255] "" Vector__XXX
 SG_ B5 : 40|8@1+ (1,0) [0|255] "" Vector__XXX
 SG_ B6 : 48|8@1+ (1,0) [0|255] "" Vector__XXX
 SG_ B7 : 56|8@1+ (1,0) [0|255] "" Vector__XXX

BA_ "VFrameFormat" BO_ 2550518259 1;
CM_ BO_ 2550518259 "0x5C0004 NO_CN_ROOT_ID | 部件: NO_CN_ROOT_ID";

BO_ 2550583795 ZT_Unknown_1806D1F3: 8 Vector__XXX
 SG_ B0 : 0|8@1+ (1,0) [0|255] "" Vector__XXX
 SG_ B1 : 8|8@1+ (1,0) [0|255] "" Vector__XXX
 SG_ B2 : 16|8@1+ (1,0) [0|255] "" Vector__XXX
 SG_ B3 : 24|8@1+ (1,0) [0|255] "" Vector__XXX
 SG_ B4 : 32|8@1+ (1,0) [0|255] "" Vector__XXX
 SG_ B5 : 40|8@1+ (1,0) [0|255] "" Vector__XXX
 SG_ B6 : 48|8@1+ (1,0) [0|255] "" Vector__XXX
 SG_ B7 : 56|8@1+ (1,0) [0|255] "" Vector__XXX

BA_ "VFrameFormat" BO_ 2550583795 1;
CM_ BO_ 2550583795 "0x5C0004 NO_CN_ROOT_ID | 部件: NO_CN_ROOT_ID";

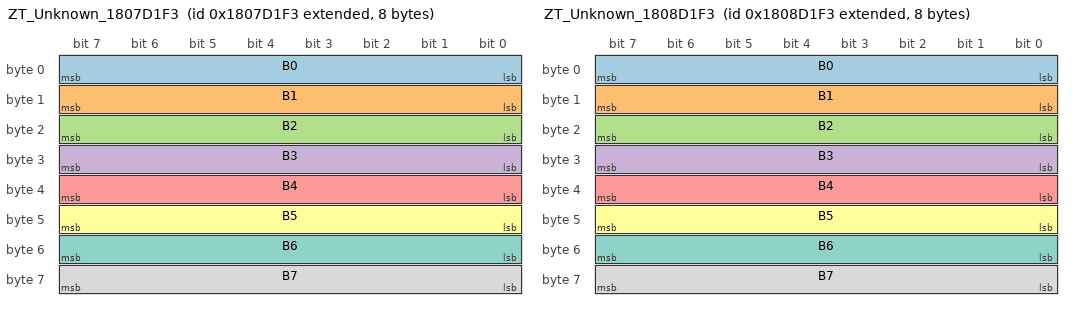
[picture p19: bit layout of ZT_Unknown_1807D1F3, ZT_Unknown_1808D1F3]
BO_ 2550649331 ZT_Unknown_1807D1F3: 8 Vector__XXX
 SG_ B0 : 0|8@1+ (1,0) [0|255] "" Vector__XXX
 SG_ B1 : 8|8@1+ (1,0) [0|255] "" Vector__XXX
 SG_ B2 : 16|8@1+ (1,0) [0|255] "" Vector__XXX
 SG_ B3 : 24|8@1+ (1,0) [0|255] "" Vector__XXX
 SG_ B4 : 32|8@1+ (1,0) [0|255] "" Vector__XXX
 SG_ B5 : 40|8@1+ (1,0) [0|255] "" Vector__XXX
 SG_ B6 : 48|8@1+ (1,0) [0|255] "" Vector__XXX
 SG_ B7 : 56|8@1+ (1,0) [0|255] "" Vector__XXX

BA_ "VFrameFormat" BO_ 2550649331 1;
CM_ BO_ 2550649331 "0x5C0004 NO_CN_ROOT_ID | 部件: NO_CN_ROOT_ID";

BO_ 2550714867 ZT_Unknown_1808D1F3: 8 Vector__XXX
 SG_ B0 : 0|8@1+ (1,0) [0|255] "" Vector__XXX
 SG_ B1 : 8|8@1+ (1,0) [0|255] "" Vector__XXX
 SG_ B2 : 16|8@1+ (1,0) [0|255] "" Vector__XXX
 SG_ B3 : 24|8@1+ (1,0) [0|255] "" Vector__XXX
 SG_ B4 : 32|8@1+ (1,0) [0|255] "" Vector__XXX
 SG_ B5 : 40|8@1+ (1,0) [0|255] "" Vector__XXX
 SG_ B6 : 48|8@1+ (1,0) [0|255] "" Vector__XXX
 SG_ B7 : 56|8@1+ (1,0) [0|255] "" Vector__XXX

BA_ "VFrameFormat" BO_ 2550714867 1;
CM_ BO_ 2550714867 "0x5C0004 NO_CN_ROOT_ID | 部件: NO_CN_ROOT_ID";

BO_ 2550780403 ZT_Unknown_1809D1F3: 8 Vector__XXX
 SG_ B0 : 0|8@1+ (1,0) [0|255] "" Vector__XXX
 SG_ B1 : 8|8@1+ (1,0) [0|255] "" Vector__XXX
 SG_ B2 : 16|8@1+ (1,0) [0|255] "" Vector__XXX
 SG_ B3 : 24|8@1+ (1,0) [0|255] "" Vector__XXX
 SG_ B4 : 32|8@1+ (1,0) [0|255] "" Vector__XXX
 SG_ B5 : 40|8@1+ (1,0) [0|255] "" Vector__XXX
 SG_ B6 : 48|8@1+ (1,0) [0|255] "" Vector__XXX
 SG_ B7 : 56|8@1+ (1,0) [0|255] "" Vector__XXX

BA_ "VFrameFormat" BO_ 2550780403 1;
CM_ BO_ 2550780403 "0x5C0004 NO_CN_ROOT_ID | 部件: NO_CN_ROOT_ID";

BO_ 2550845939 ZT_Unknown_180AD1F3: 8 Vector__XXX
 SG_ B0 : 0|8@1+ (1,0) [0|255] "" Vector__XXX
 SG_ B1 : 8|8@1+ (1,0) [0|255] "" Vector__XXX
 SG_ B2 : 16|8@1+ (1,0) [0|255] "" Vector__XXX
 SG_ B3 : 24|8@1+ (1,0) [0|255] "" Vector__XXX
 SG_ B4 : 32|8@1+ (1,0) [0|255] "" Vector__XXX
 SG_ B5 : 40|8@1+ (1,0) [0|255] "" Vector__XXX
 SG_ B6 : 48|8@1+ (1,0) [0|255] "" Vector__XXX
 SG_ B7 : 56|8@1+ (1,0) [0|255] "" Vector__XXX

BA_ "VFrameFormat" BO_ 2550845939 1;
CM_ BO_ 2550845939 "0x5C0004 NO_CN_ROOT_ID | 部件: NO_CN_ROOT_ID";

BO_ 2550911475 ZT_Unknown_180BD1F3: 8 Vector__XXX
 SG_ B0 : 0|8@1+ (1,0) [0|255] "" Vector__XXX
 SG_ B1 : 8|8@1+ (1,0) [0|255] "" Vector__XXX
 SG_ B2 : 16|8@1+ (1,0) [0|255] "" Vector__XXX
 SG_ B3 : 24|8@1+ (1,0) [0|255] "" Vector__XXX
 SG_ B4 : 32|8@1+ (1,0) [0|255] "" Vector__XXX
 SG_ B5 : 40|8@1+ (1,0) [0|255] "" Vector__XXX
 SG_ B6 : 48|8@1+ (1,0) [0|255] "" Vector__XXX
 SG_ B7 : 56|8@1+ (1,0) [0|255] "" Vector__XXX

BA_ "VFrameFormat" BO_ 2550911475 1;
CM_ BO_ 2550911475 "0x5C0004 NO_CN_ROOT_ID | 部件: NO_CN_ROOT_ID";

BO_ 2550977011 ZT_Unknown_180CD1F3: 8 Vector__XXX
 SG_ B0 : 0|8@1+ (1,0) [0|255] "" Vector__XXX
 SG_ B1 : 8|8@1+ (1,0) [0|255] "" Vector__XXX
 SG_ B2 : 16|8@1+ (1,0) [0|255] "" Vector__XXX
 SG_ B3 : 24|8@1+ (1,0) [0|255] "" Vector__XXX
 SG_ B4 : 32|8@1+ (1,0) [0|255] "" Vector__XXX
 SG_ B5 : 40|8@1+ (1,0) [0|255] "" Vector__XXX
 SG_ B6 : 48|8@1+ (1,0) [0|255] "" Vector__XXX
 SG_ B7 : 56|8@1+ (1,0) [0|255] "" Vector__XXX

BA_ "VFrameFormat" BO_ 2550977011 1;
CM_ BO_ 2550977011 "0x5C0004 NO_CN_ROOT_ID | 部件: NO_CN_ROOT_ID";

BO_ 2551042547 ZT_Unknown_180DD1F3: 8 Vector__XXX
 SG_ B0 : 0|8@1+ (1,0) [0|255] "" Vector__XXX
 SG_ B1 : 8|8@1+ (1,0) [0|255] "" Vector__XXX
 SG_ B2 : 16|8@1+ (1,0) [0|255] "" Vector__XXX
 SG_ B3 : 24|8@1+ (1,0) [0|255] "" Vector__XXX
 SG_ B4 : 32|8@1+ (1,0) [0|255] "" Vector__XXX
 SG_ B5 : 40|8@1+ (1,0) [0|255] "" Vector__XXX
 SG_ B6 : 48|8@1+ (1,0) [0|255] "" Vector__XXX
 SG_ B7 : 56|8@1+ (1,0) [0|255] "" Vector__XXX

BA_ "VFrameFormat" BO_ 2551042547 1;
CM_ BO_ 2551042547 "0x5C0004 NO_CN_ROOT_ID | 部件: NO_CN_ROOT_ID";

BO_ 2551108083 ZT_Unknown_180ED1F3: 8 Vector__XXX
 SG_ B0 : 0|8@1+ (1,0) [0|255] "" Vector__XXX
 SG_ B1 : 8|8@1+ (1,0) [0|255] "" Vector__XXX
 SG_ B2 : 16|8@1+ (1,0) [0|255] "" Vector__XXX
 SG_ B3 : 24|8@1+ (1,0) [0|255] "" Vector__XXX
 SG_ B4 : 32|8@1+ (1,0) [0|255] "" Vector__XXX
 SG_ B5 : 40|8@1+ (1,0) [0|255] "" Vector__XXX
 SG_ B6 : 48|8@1+ (1,0) [0|255] "" Vector__XXX
 SG_ B7 : 56|8@1+ (1,0) [0|255] "" Vector__XXX

BA_ "VFrameFormat" BO_ 2551108083 1;
CM_ BO_ 2551108083 "0x5C0004 NO_CN_ROOT_ID | 部件: NO_CN_ROOT_ID";

BO_ 2551173619 ZT_Unknown_180FD1F3: 8 Vector__XXX
 SG_ B0 : 0|8@1+ (1,0) [0|255] "" Vector__XXX
 SG_ B1 : 8|8@1+ (1,0) [0|255] "" Vector__XXX
 SG_ B2 : 16|8@1+ (1,0) [0|255] "" Vector__XXX
 SG_ B3 : 24|8@1+ (1,0) [0|255] "" Vector__XXX
 SG_ B4 : 32|8@1+ (1,0) [0|255] "" Vector__XXX
 SG_ B5 : 40|8@1+ (1,0) [0|255] "" Vector__XXX
 SG_ B6 : 48|8@1+ (1,0) [0|255] "" Vector__XXX
 SG_ B7 : 56|8@1+ (1,0) [0|255] "" Vector__XXX

BA_ "VFrameFormat" BO_ 2551173619 1;
CM_ BO_ 2551173619 "0x5C0004 NO_CN_ROOT_ID | 部件: NO_CN_ROOT_ID";

BO_ 2551239155 ZT_Unknown_1810D1F3: 8 Vector__XXX
 SG_ B0 : 0|8@1+ (1,0) [0|255] "" Vector__XXX
 SG_ B1 : 8|8@1+ (1,0) [0|255] "" Vector__XXX
 SG_ B2 : 16|8@1+ (1,0) [0|255] "" Vector__XXX
 SG_ B3 : 24|8@1+ (1,0) [0|255] "" Vector__XXX
 SG_ B4 : 32|8@1+ (1,0) [0|255] "" Vector__XXX
 SG_ B5 : 40|8@1+ (1,0) [0|255] "" Vector__XXX
 SG_ B6 : 48|8@1+ (1,0) [0|255] "" Vector__XXX
 SG_ B7 : 56|8@1+ (1,0) [0|255] "" Vector__XXX

BA_ "VFrameFormat" BO_ 2551239155 1;
CM_ BO_ 2551239155 "0x5C0004 NO_CN_ROOT_ID | 部件: NO_CN_ROOT_ID";

BO_ 2551304691 ZT_Unknown_1811D1F3: 8 Vector__XXX
 SG_ B0 : 0|8@1+ (1,0) [0|255] "" Vector__XXX
 SG_ B1 : 8|8@1+ (1,0) [0|255] "" Vector__XXX
 SG_ B2 : 16|8@1+ (1,0) [0|255] "" Vector__XXX
 SG_ B3 : 24|8@1+ (1,0) [0|255] "" Vector__XXX
 SG_ B4 : 32|8@1+ (1,0) [0|255] "" Vector__XXX
 SG_ B5 : 40|8@1+ (1,0) [0|255] "" Vector__XXX
 SG_ B6 : 48|8@1+ (1,0) [0|255] "" Vector__XXX
 SG_ B7 : 56|8@1+ (1,0) [0|255] "" Vector__XXX

BA_ "VFrameFormat" BO_ 2551304691 1;
CM_ BO_ 2551304691 "0x5C0004 NO_CN_ROOT_ID | 部件: NO_CN_ROOT_ID";

BO_ 2551370227 ZT_Unknown_1812D1F3: 8 Vector__XXX
 SG_ B0 : 0|8@1+ (1,0) [0|255] "" Vector__XXX
 SG_ B1 : 8|8@1+ (1,0) [0|255] "" Vector__XXX
 SG_ B2 : 16|8@1+ (1,0) [0|255] "" Vector__XXX
 SG_ B3 : 24|8@1+ (1,0) [0|255] "" Vector__XXX
 SG_ B4 : 32|8@1+ (1,0) [0|255] "" Vector__XXX
 SG_ B5 : 40|8@1+ (1,0) [0|255] "" Vector__XXX
 SG_ B6 : 48|8@1+ (1,0) [0|255] "" Vector__XXX
 SG_ B7 : 56|8@1+ (1,0) [0|255] "" Vector__XXX

BA_ "VFrameFormat" BO_ 2551370227 1;
CM_ BO_ 2551370227 "0x5C0004 NO_CN_ROOT_ID | 部件: NO_CN_ROOT_ID";

BO_ 2551435763 ZT_Unknown_1813D1F3: 8 Vector__XXX
 SG_ B0 : 0|8@1+ (1,0) [0|255] "" Vector__XXX
 SG_ B1 : 8|8@1+ (1,0) [0|255] "" Vector__XXX
 SG_ B2 : 16|8@1+ (1,0) [0|255] "" Vector__XXX
 SG_ B3 : 24|8@1+ (1,0) [0|255] "" Vector__XXX
 SG_ B4 : 32|8@1+ (1,0) [0|255] "" Vector__XXX
 SG_ B5 : 40|8@1+ (1,0) [0|255] "" Vector__XXX
 SG_ B6 : 48|8@1+ (1,0) [0|255] "" Vector__XXX
 SG_ B7 : 56|8@1+ (1,0) [0|255] "" Vector__XXX

BA_ "VFrameFormat" BO_ 2551435763 1;
CM_ BO_ 2551435763 "0x5C0004 NO_CN_ROOT_ID | 部件: NO_CN_ROOT_ID";

BO_ 2551501299 ZT_Unknown_1814D1F3: 8 Vector__XXX
 SG_ B0 : 0|8@1+ (1,0) [0|255] "" Vector__XXX
 SG_ B1 : 8|8@1+ (1,0) [0|255] "" Vector__XXX
 SG_ B2 : 16|8@1+ (1,0) [0|255] "" Vector__XXX
 SG_ B3 : 24|8@1+ (1,0) [0|255] "" Vector__XXX
 SG_ B4 : 32|8@1+ (1,0) [0|255] "" Vector__XXX
 SG_ B5 : 40|8@1+ (1,0) [0|255] "" Vector__XXX
 SG_ B6 : 48|8@1+ (1,0) [0|255] "" Vector__XXX
 SG_ B7 : 56|8@1+ (1,0) [0|255] "" Vector__XXX

BA_ "VFrameFormat" BO_ 2551501299 1;
CM_ BO_ 2551501299 "0x5C0004 NO_CN_ROOT_ID | 部件: NO_CN_ROOT_ID";

BO_ 2551566835 ZT_Unknown_1815D1F3: 8 Vector__XXX
 SG_ B0 : 0|8@1+ (1,0) [0|255] "" Vector__XXX
 SG_ B1 : 8|8@1+ (1,0) [0|255] "" Vector__XXX
 SG_ B2 : 16|8@1+ (1,0) [0|255] "" Vector__XXX
 SG_ B3 : 24|8@1+ (1,0) [0|255] "" Vector__XXX
 SG_ B4 : 32|8@1+ (1,0) [0|255] "" Vector__XXX
 SG_ B5 : 40|8@1+ (1,0) [0|255] "" Vector__XXX
 SG_ B6 : 48|8@1+ (1,0) [0|255] "" Vector__XXX
 SG_ B7 : 56|8@1+ (1,0) [0|255] "" Vector__XXX

BA_ "VFrameFormat" BO_ 2551566835 1;
CM_ BO_ 2551566835 "0x5C0004 NO_CN_ROOT_ID | 部件: NO_CN_ROOT_ID";

BO_ 2551632371 ZT_Unknown_1816D1F3: 8 Vector__XXX
 SG_ B0 : 0|8@1+ (1,0) [0|255] "" Vector__XXX
 SG_ B1 : 8|8@1+ (1,0) [0|255] "" Vector__XXX
 SG_ B2 : 16|8@1+ (1,0) [0|255] "" Vector__XXX
 SG_ B3 : 24|8@1+ (1,0) [0|255] "" Vector__XXX
 SG_ B4 : 32|8@1+ (1,0) [0|255] "" Vector__XXX
 SG_ B5 : 40|8@1+ (1,0) [0|255] "" Vector__XXX
 SG_ B6 : 48|8@1+ (1,0) [0|255] "" Vector__XXX
 SG_ B7 : 56|8@1+ (1,0) [0|255] "" Vector__XXX

BA_ "VFrameFormat" BO_ 2551632371 1;
CM_ BO_ 2551632371 "0x5C0004 NO_CN_ROOT_ID | 部件: NO_CN_ROOT_ID";

BO_ 2551697907 ZT_Unknown_1817D1F3: 8 Vector__XXX
 SG_ B0 : 0|8@1+ (1,0) [0|255] "" Vector__XXX
 SG_ B1 : 8|8@1+ (1,0) [0|255] "" Vector__XXX
 SG_ B2 : 16|8@1+ (1,0) [0|255] "" Vector__XXX
 SG_ B3 : 24|8@1+ (1,0) [0|255] "" Vector__XXX
 SG_ B4 : 32|8@1+ (1,0) [0|255] "" Vector__XXX
 SG_ B5 : 40|8@1+ (1,0) [0|255] "" Vector__XXX
 SG_ B6 : 48|8@1+ (1,0) [0|255] "" Vector__XXX
 SG_ B7 : 56|8@1+ (1,0) [0|255] "" Vector__XXX

BA_ "VFrameFormat" BO_ 2551697907 1;
CM_ BO_ 2551697907 "0x5C0004 NO_CN_ROOT_ID | 部件: NO_CN_ROOT_ID";

BO_ 2551763443 ZT_Unknown_1818D1F3: 8 Vector__XXX
 SG_ B0 : 0|8@1+ (1,0) [0|255] "" Vector__XXX
 SG_ B1 : 8|8@1+ (1,0) [0|255] "" Vector__XXX
 SG_ B2 : 16|8@1+ (1,0) [0|255] "" Vector__XXX
 SG_ B3 : 24|8@1+ (1,0) [0|255] "" Vector__XXX
 SG_ B4 : 32|8@1+ (1,0) [0|255] "" Vector__XXX
 SG_ B5 : 40|8@1+ (1,0) [0|255] "" Vector__XXX
 SG_ B6 : 48|8@1+ (1,0) [0|255] "" Vector__XXX
 SG_ B7 : 56|8@1+ (1,0) [0|255] "" Vector__XXX

BA_ "VFrameFormat" BO_ 2551763443 1;
CM_ BO_ 2551763443 "0x5C0004 NO_CN_ROOT_ID | 部件: NO_CN_ROOT_ID";

BO_ 2551828979 ZT_Unknown_1819D1F3: 8 Vector__XXX
 SG_ B0 : 0|8@1+ (1,0) [0|255] "" Vector__XXX
 SG_ B1 : 8|8@1+ (1,0) [0|255] "" Vector__XXX
 SG_ B2 : 16|8@1+ (1,0) [0|255] "" Vector__XXX
 SG_ B3 : 24|8@1+ (1,0) [0|255] "" Vector__XXX
 SG_ B4 : 32|8@1+ (1,0) [0|255] "" Vector__XXX
 SG_ B5 : 40|8@1+ (1,0) [0|255] "" Vector__XXX
 SG_ B6 : 48|8@1+ (1,0) [0|255] "" Vector__XXX
 SG_ B7 : 56|8@1+ (1,0) [0|255] "" Vector__XXX

BA_ "VFrameFormat" BO_ 2551828979 1;
CM_ BO_ 2551828979 "0x5C0004 NO_CN_ROOT_ID | 部件: NO_CN_ROOT_ID";

BO_ 2551894515 ZT_Unknown_181AD1F3: 8 Vector__XXX
 SG_ B0 : 0|8@1+ (1,0) [0|255] "" Vector__XXX
 SG_ B1 : 8|8@1+ (1,0) [0|255] "" Vector__XXX
 SG_ B2 : 16|8@1+ (1,0) [0|255] "" Vector__XXX
 SG_ B3 : 24|8@1+ (1,0) [0|255] "" Vector__XXX
 SG_ B4 : 32|8@1+ (1,0) [0|255] "" Vector__XXX
 SG_ B5 : 40|8@1+ (1,0) [0|255] "" Vector__XXX
 SG_ B6 : 48|8@1+ (1,0) [0|255] "" Vector__XXX
 SG_ B7 : 56|8@1+ (1,0) [0|255] "" Vector__XXX

BA_ "VFrameFormat" BO_ 2551894515 1;
CM_ BO_ 2551894515 "0x5C0004 NO_CN_ROOT_ID | 部件: NO_CN_ROOT_ID";

BO_ 2551960051 ZT_Unknown_181BD1F3: 8 Vector__XXX
 SG_ B0 : 0|8@1+ (1,0) [0|255] "" Vector__XXX
 SG_ B1 : 8|8@1+ (1,0) [0|255] "" Vector__XXX
 SG_ B2 : 16|8@1+ (1,0) [0|255] "" Vector__XXX
 SG_ B3 : 24|8@1+ (1,0) [0|255] "" Vector__XXX
 SG_ B4 : 32|8@1+ (1,0) [0|255] "" Vector__XXX
 SG_ B5 : 40|8@1+ (1,0) [0|255] "" Vector__XXX
 SG_ B6 : 48|8@1+ (1,0) [0|255] "" Vector__XXX
 SG_ B7 : 56|8@1+ (1,0) [0|255] "" Vector__XXX

BA_ "VFrameFormat" BO_ 2551960051 1;
CM_ BO_ 2551960051 "0x5C0004 NO_CN_ROOT_ID | 部件: NO_CN_ROOT_ID";

BO_ 2552025587 ZT_Unknown_181CD1F3: 8 Vector__XXX
 SG_ B0 : 0|8@1+ (1,0) [0|255] "" Vector__XXX
 SG_ B1 : 8|8@1+ (1,0) [0|255] "" Vector__XXX
 SG_ B2 : 16|8@1+ (1,0) [0|255] "" Vector__XXX
 SG_ B3 : 24|8@1+ (1,0) [0|255] "" Vector__XXX
 SG_ B4 : 32|8@1+ (1,0) [0|255] "" Vector__XXX
 SG_ B5 : 40|8@1+ (1,0) [0|255] "" Vector__XXX
 SG_ B6 : 48|8@1+ (1,0) [0|255] "" Vector__XXX
 SG_ B7 : 56|8@1+ (1,0) [0|255] "" Vector__XXX

BA_ "VFrameFormat" BO_ 2552025587 1;
CM_ BO_ 2552025587 "0x5C0004 NO_CN_ROOT_ID | 部件: NO_CN_ROOT_ID";

BO_ 2552091123 ZT_Unknown_181DD1F3: 8 Vector__XXX
 SG_ B0 : 0|8@1+ (1,0) [0|255] "" Vector__XXX
 SG_ B1 : 8|8@1+ (1,0) [0|255] "" Vector__XXX
 SG_ B2 : 16|8@1+ (1,0) [0|255] "" Vector__XXX
 SG_ B3 : 24|8@1+ (1,0) [0|255] "" Vector__XXX
 SG_ B4 : 32|8@1+ (1,0) [0|255] "" Vector__XXX
 SG_ B5 : 40|8@1+ (1,0) [0|255] "" Vector__XXX
 SG_ B6 : 48|8@1+ (1,0) [0|255] "" Vector__XXX
 SG_ B7 : 56|8@1+ (1,0) [0|255] "" Vector__XXX

BA_ "VFrameFormat" BO_ 2552091123 1;
CM_ BO_ 2552091123 "0x5C0004 NO_CN_ROOT_ID | 部件: NO_CN_ROOT_ID";

BO_ 2552156659 ZT_Unknown_181ED1F3: 8 Vector__XXX
 SG_ B0 : 0|8@1+ (1,0) [0|255] "" Vector__XXX
 SG_ B1 : 8|8@1+ (1,0) [0|255] "" Vector__XXX
 SG_ B2 : 16|8@1+ (1,0) [0|255] "" Vector__XXX
 SG_ B3 : 24|8@1+ (1,0) [0|255] "" Vector__XXX
 SG_ B4 : 32|8@1+ (1,0) [0|255] "" Vector__XXX
 SG_ B5 : 40|8@1+ (1,0) [0|255] "" Vector__XXX
 SG_ B6 : 48|8@1+ (1,0) [0|255] "" Vector__XXX
 SG_ B7 : 56|8@1+ (1,0) [0|255] "" Vector__XXX

BA_ "VFrameFormat" BO_ 2552156659 1;
CM_ BO_ 2552156659 "0x5C0004 NO_CN_ROOT_ID | 部件: NO_CN_ROOT_ID";

BO_ 2552222195 ZT_Unknown_181FD1F3: 8 Vector__XXX
 SG_ B0 : 0|8@1+ (1,0) [0|255] "" Vector__XXX
 SG_ B1 : 8|8@1+ (1,0) [0|255] "" Vector__XXX
 SG_ B2 : 16|8@1+ (1,0) [0|255] "" Vector__XXX
 SG_ B3 : 24|8@1+ (1,0) [0|255] "" Vector__XXX
 SG_ B4 : 32|8@1+ (1,0) [0|255] "" Vector__XXX
 SG_ B5 : 40|8@1+ (1,0) [0|255] "" Vector__XXX
 SG_ B6 : 48|8@1+ (1,0) [0|255] "" Vector__XXX
 SG_ B7 : 56|8@1+ (1,0) [0|255] "" Vector__XXX

BA_ "VFrameFormat" BO_ 2552222195 1;
CM_ BO_ 2552222195 "0x5C0004 NO_CN_ROOT_ID | 部件: NO_CN_ROOT_ID";

BO_ 2552287731 ZT_Unknown_1820D1F3: 8 Vector__XXX
 SG_ B0 : 0|8@1+ (1,0) [0|255] "" Vector__XXX
 SG_ B1 : 8|8@1+ (1,0) [0|255] "" Vector__XXX
 SG_ B2 : 16|8@1+ (1,0) [0|255] "" Vector__XXX
 SG_ B3 : 24|8@1+ (1,0) [0|255] "" Vector__XXX
 SG_ B4 : 32|8@1+ (1,0) [0|255] "" Vector__XXX
 SG_ B5 : 40|8@1+ (1,0) [0|255] "" Vector__XXX
 SG_ B6 : 48|8@1+ (1,0) [0|255] "" Vector__XXX
 SG_ B7 : 56|8@1+ (1,0) [0|255] "" Vector__XXX

BA_ "VFrameFormat" BO_ 2552287731 1;
CM_ BO_ 2552287731 "0x5C0004 NO_CN_ROOT_ID | 部件: NO_CN_ROOT_ID";

BO_ 2552353267 ZT_Unknown_1821D1F3: 8 Vector__XXX
 SG_ B0 : 0|8@1+ (1,0) [0|255] "" Vector__XXX
 SG_ B1 : 8|8@1+ (1,0) [0|255] "" Vector__XXX
 SG_ B2 : 16|8@1+ (1,0) [0|255] "" Vector__XXX
 SG_ B3 : 24|8@1+ (1,0) [0|255] "" Vector__XXX
 SG_ B4 : 32|8@1+ (1,0) [0|255] "" Vector__XXX
 SG_ B5 : 40|8@1+ (1,0) [0|255] "" Vector__XXX
 SG_ B6 : 48|8@1+ (1,0) [0|255] "" Vector__XXX
 SG_ B7 : 56|8@1+ (1,0) [0|255] "" Vector__XXX

BA_ "VFrameFormat" BO_ 2552353267 1;
CM_ BO_ 2552353267 "0x5C0004 NO_CN_ROOT_ID | 部件: NO_CN_ROOT_ID";

BO_ 2552418803 ZT_Unknown_1822D1F3: 8 Vector__XXX
 SG_ B0 : 0|8@1+ (1,0) [0|255] "" Vector__XXX
 SG_ B1 : 8|8@1+ (1,0) [0|255] "" Vector__XXX
 SG_ B2 : 16|8@1+ (1,0) [0|255] "" Vector__XXX
 SG_ B3 : 24|8@1+ (1,0) [0|255] "" Vector__XXX
 SG_ B4 : 32|8@1+ (1,0) [0|255] "" Vector__XXX
 SG_ B5 : 40|8@1+ (1,0) [0|255] "" Vector__XXX
 SG_ B6 : 48|8@1+ (1,0) [0|255] "" Vector__XXX
 SG_ B7 : 56|8@1+ (1,0) [0|255] "" Vector__XXX

BA_ "VFrameFormat" BO_ 2552418803 1;
CM_ BO_ 2552418803 "0x5C0004 NO_CN_ROOT_ID | 部件: NO_CN_ROOT_ID";

BO_ 2552484339 ZT_Unknown_1823D1F3: 8 Vector__XXX
 SG_ B0 : 0|8@1+ (1,0) [0|255] "" Vector__XXX
 SG_ B1 : 8|8@1+ (1,0) [0|255] "" Vector__XXX
 SG_ B2 : 16|8@1+ (1,0) [0|255] "" Vector__XXX
 SG_ B3 : 24|8@1+ (1,0) [0|255] "" Vector__XXX
 SG_ B4 : 32|8@1+ (1,0) [0|255] "" Vector__XXX
 SG_ B5 : 40|8@1+ (1,0) [0|255] "" Vector__XXX
 SG_ B6 : 48|8@1+ (1,0) [0|255] "" Vector__XXX
 SG_ B7 : 56|8@1+ (1,0) [0|255] "" Vector__XXX

BA_ "VFrameFormat" BO_ 2552484339 1;
CM_ BO_ 2552484339 "0x5C0004 NO_CN_ROOT_ID | 部件: NO_CN_ROOT_ID";

BO_ 2552549875 ZT_Unknown_1824D1F3: 8 Vector__XXX
 SG_ B0 : 0|8@1+ (1,0) [0|255] "" Vector__XXX
 SG_ B1 : 8|8@1+ (1,0) [0|255] "" Vector__XXX
 SG_ B2 : 16|8@1+ (1,0) [0|255] "" Vector__XXX
 SG_ B3 : 24|8@1+ (1,0) [0|255] "" Vector__XXX
 SG_ B4 : 32|8@1+ (1,0) [0|255] "" Vector__XXX
 SG_ B5 : 40|8@1+ (1,0) [0|255] "" Vector__XXX
 SG_ B6 : 48|8@1+ (1,0) [0|255] "" Vector__XXX
 SG_ B7 : 56|8@1+ (1,0) [0|255] "" Vector__XXX

BA_ "VFrameFormat" BO_ 2552549875 1;
CM_ BO_ 2552549875 "0x5C0004 NO_CN_ROOT_ID | 部件: NO_CN_ROOT_ID";

BO_ 2552615411 ZT_Unknown_1825D1F3: 8 Vector__XXX
 SG_ B0 : 0|8@1+ (1,0) [0|255] "" Vector__XXX
 SG_ B1 : 8|8@1+ (1,0) [0|255] "" Vector__XXX
 SG_ B2 : 16|8@1+ (1,0) [0|255] "" Vector__XXX
 SG_ B3 : 24|8@1+ (1,0) [0|255] "" Vector__XXX
 SG_ B4 : 32|8@1+ (1,0) [0|255] "" Vector__XXX
 SG_ B5 : 40|8@1+ (1,0) [0|255] "" Vector__XXX
 SG_ B6 : 48|8@1+ (1,0) [0|255] "" Vector__XXX
 SG_ B7 : 56|8@1+ (1,0) [0|255] "" Vector__XXX

BA_ "VFrameFormat" BO_ 2552615411 1;
CM_ BO_ 2552615411 "0x5C0004 NO_CN_ROOT_ID | 部件: NO_CN_ROOT_ID";

BO_ 2552680947 ZT_Unknown_1826D1F3: 8 Vector__XXX
 SG_ B0 : 0|8@1+ (1,0) [0|255] "" Vector__XXX
 SG_ B1 : 8|8@1+ (1,0) [0|255] "" Vector__XXX
 SG_ B2 : 16|8@1+ (1,0) [0|255] "" Vector__XXX
 SG_ B3 : 24|8@1+ (1,0) [0|255] "" Vector__XXX
 SG_ B4 : 32|8@1+ (1,0) [0|255] "" Vector__XXX
 SG_ B5 : 40|8@1+ (1,0) [0|255] "" Vector__XXX
 SG_ B6 : 48|8@1+ (1,0) [0|255] "" Vector__XXX
 SG_ B7 : 56|8@1+ (1,0) [0|255] "" Vector__XXX

BA_ "VFrameFormat" BO_ 2552680947 1;
CM_ BO_ 2552680947 "0x5C0004 NO_CN_ROOT_ID | 部件: NO_CN_ROOT_ID";

BO_ 2552746483 ZT_Unknown_1827D1F3: 8 Vector__XXX
 SG_ B0 : 0|8@1+ (1,0) [0|255] "" Vector__XXX
 SG_ B1 : 8|8@1+ (1,0) [0|255] "" Vector__XXX
 SG_ B2 : 16|8@1+ (1,0) [0|255] "" Vector__XXX
 SG_ B3 : 24|8@1+ (1,0) [0|255] "" Vector__XXX
 SG_ B4 : 32|8@1+ (1,0) [0|255] "" Vector__XXX
 SG_ B5 : 40|8@1+ (1,0) [0|255] "" Vector__XXX
 SG_ B6 : 48|8@1+ (1,0) [0|255] "" Vector__XXX
 SG_ B7 : 56|8@1+ (1,0) [0|255] "" Vector__XXX

BA_ "VFrameFormat" BO_ 2552746483 1;
CM_ BO_ 2552746483 "0x5C0004 NO_CN_ROOT_ID | 部件: NO_CN_ROOT_ID";

BO_ 2552812019 ZT_Unknown_1828D1F3: 8 Vector__XXX
 SG_ B0 : 0|8@1+ (1,0) [0|255] "" Vector__XXX
 SG_ B1 : 8|8@1+ (1,0) [0|255] "" Vector__XXX
 SG_ B2 : 16|8@1+ (1,0) [0|255] "" Vector__XXX
 SG_ B3 : 24|8@1+ (1,0) [0|255] "" Vector__XXX
 SG_ B4 : 32|8@1+ (1,0) [0|255] "" Vector__XXX
 SG_ B5 : 40|8@1+ (1,0) [0|255] "" Vector__XXX
 SG_ B6 : 48|8@1+ (1,0) [0|255] "" Vector__XXX
 SG_ B7 : 56|8@1+ (1,0) [0|255] "" Vector__XXX

BA_ "VFrameFormat" BO_ 2552812019 1;
CM_ BO_ 2552812019 "0x5C0004 NO_CN_ROOT_ID | 部件: NO_CN_ROOT_ID";

BO_ 2552877555 ZT_Unknown_1829D1F3: 8 Vector__XXX
 SG_ B0 : 0|8@1+ (1,0) [0|255] "" Vector__XXX
 SG_ B1 : 8|8@1+ (1,0) [0|255] "" Vector__XXX
 SG_ B2 : 16|8@1+ (1,0) [0|255] "" Vector__XXX
 SG_ B3 : 24|8@1+ (1,0) [0|255] "" Vector__XXX
 SG_ B4 : 32|8@1+ (1,0) [0|255] "" Vector__XXX
 SG_ B5 : 40|8@1+ (1,0) [0|255] "" Vector__XXX
 SG_ B6 : 48|8@1+ (1,0) [0|255] "" Vector__XXX
 SG_ B7 : 56|8@1+ (1,0) [0|255] "" Vector__XXX

BA_ "VFrameFormat" BO_ 2552877555 1;
CM_ BO_ 2552877555 "0x5C0004 NO_CN_ROOT_ID | 部件: NO_CN_ROOT_ID";

BO_ 2552943091 ZT_Unknown_182AD1F3: 8 Vector__XXX
 SG_ B0 : 0|8@1+ (1,0) [0|255] "" Vector__XXX
 SG_ B1 : 8|8@1+ (1,0) [0|255] "" Vector__XXX
 SG_ B2 : 16|8@1+ (1,0) [0|255] "" Vector__XXX
 SG_ B3 : 24|8@1+ (1,0) [0|255] "" Vector__XXX
 SG_ B4 : 32|8@1+ (1,0) [0|255] "" Vector__XXX
 SG_ B5 : 40|8@1+ (1,0) [0|255] "" Vector__XXX
 SG_ B6 : 48|8@1+ (1,0) [0|255] "" Vector__XXX
 SG_ B7 : 56|8@1+ (1,0) [0|255] "" Vector__XXX

BA_ "VFrameFormat" BO_ 2552943091 1;
CM_ BO_ 2552943091 "0x5C0004 NO_CN_ROOT_ID | 部件: NO_CN_ROOT_ID";

BO_ 2554188275 ZT_Unknown_183DD1F3: 8 Vector__XXX
 SG_ B0 : 0|8@1+ (1,0) [0|255] "" Vector__XXX
 SG_ B1 : 8|8@1+ (1,0) [0|255] "" Vector__XXX
 SG_ B2 : 16|8@1+ (1,0) [0|255] "" Vector__XXX
 SG_ B3 : 24|8@1+ (1,0) [0|255] "" Vector__XXX
 SG_ B4 : 32|8@1+ (1,0) [0|255] "" Vector__XXX
 SG_ B5 : 40|8@1+ (1,0) [0|255] "" Vector__XXX
 SG_ B6 : 48|8@1+ (1,0) [0|255] "" Vector__XXX
 SG_ B7 : 56|8@1+ (1,0) [0|255] "" Vector__XXX

BA_ "VFrameFormat" BO_ 2554188275 1;
CM_ BO_ 2554188275 "0x5C0004 NO_CN_ROOT_ID | 部件: NO_CN_ROOT_ID";

BO_ 2554253811 ZT_Unknown_183ED1F3: 8 Vector__XXX
 SG_ B0 : 0|8@1+ (1,0) [0|255] "" Vector__XXX
 SG_ B1 : 8|8@1+ (1,0) [0|255] "" Vector__XXX
 SG_ B2 : 16|8@1+ (1,0) [0|255] "" Vector__XXX
 SG_ B3 : 24|8@1+ (1,0) [0|255] "" Vector__XXX
 SG_ B4 : 32|8@1+ (1,0) [0|255] "" Vector__XXX
 SG_ B5 : 40|8@1+ (1,0) [0|255] "" Vector__XXX
 SG_ B6 : 48|8@1+ (1,0) [0|255] "" Vector__XXX
 SG_ B7 : 56|8@1+ (1,0) [0|255] "" Vector__XXX

BA_ "VFrameFormat" BO_ 2554253811 1;
CM_ BO_ 2554253811 "0x5C0004 NO_CN_ROOT_ID | 部件: NO_CN_ROOT_ID";

BO_ 2566400926 ZT_Unknown_18F82B9E: 8 Vector__XXX
 SG_ B0 : 0|8@1+ (1,0) [0|255] "" Vector__XXX
 SG_ B1 : 8|8@1+ (1,0) [0|255] "" Vector__XXX
 SG_ B2 : 16|8@1+ (1,0) [0|255] "" Vector__XXX
 SG_ B3 : 24|8@1+ (1,0) [0|255] "" Vector__XXX
 SG_ B4 : 32|8@1+ (1,0) [0|255] "" Vector__XXX
 SG_ B5 : 40|8@1+ (1,0) [0|255] "" Vector__XXX
 SG_ B6 : 48|8@1+ (1,0) [0|255] "" Vector__XXX
 SG_ B7 : 56|8@1+ (1,0) [0|255] "" Vector__XXX

BA_ "VFrameFormat" BO_ 2566400926 1;
CM_ BO_ 2566400926 "0x5C0004 NO_CN_ROOT_ID | 部件: NO_CN_ROOT_ID";

BO_ 2566401182 ZT_Unknown_18F82C9E: 8 Vector__XXX
 SG_ B0 : 0|8@1+ (1,0) [0|255] "" Vector__XXX
 SG_ B1 : 8|8@1+ (1,0) [0|255] "" Vector__XXX
 SG_ B2 : 16|8@1+ (1,0) [0|255] "" Vector__XXX
 SG_ B3 : 24|8@1+ (1,0) [0|255] "" Vector__XXX
 SG_ B4 : 32|8@1+ (1,0) [0|255] "" Vector__XXX
 SG_ B5 : 40|8@1+ (1,0) [0|255] "" Vector__XXX
 SG_ B6 : 48|8@1+ (1,0) [0|255] "" Vector__XXX
 SG_ B7 : 56|8@1+ (1,0) [0|255] "" Vector__XXX

BA_ "VFrameFormat" BO_ 2566401182 1;
CM_ BO_ 2566401182 "0x5C0004 NO_CN_ROOT_ID | 部件: NO_CN_ROOT_ID";

BO_ 2566401438 ZT_Unknown_18F82D9E: 8 Vector__XXX
 SG_ B0 : 0|8@1+ (1,0) [0|255] "" Vector__XXX
 SG_ B1 : 8|8@1+ (1,0) [0|255] "" Vector__XXX
 SG_ B2 : 16|8@1+ (1,0) [0|255] "" Vector__XXX
 SG_ B3 : 24|8@1+ (1,0) [0|255] "" Vector__XXX
 SG_ B4 : 32|8@1+ (1,0) [0|255] "" Vector__XXX
 SG_ B5 : 40|8@1+ (1,0) [0|255] "" Vector__XXX
 SG_ B6 : 48|8@1+ (1,0) [0|255] "" Vector__XXX
 SG_ B7 : 56|8@1+ (1,0) [0|255] "" Vector__XXX

BA_ "VFrameFormat" BO_ 2566401438 1;
CM_ BO_ 2566401438 "0x5C0004 NO_CN_ROOT_ID | 部件: NO_CN_ROOT_ID";

BO_ 2566401694 ZT_Unknown_18F82E9E: 8 Vector__XXX
 SG_ B0 : 0|8@1+ (1,0) [0|255] "" Vector__XXX
 SG_ B1 : 8|8@1+ (1,0) [0|255] "" Vector__XXX
 SG_ B2 : 16|8@1+ (1,0) [0|255] "" Vector__XXX
 SG_ B3 : 24|8@1+ (1,0) [0|255] "" Vector__XXX
 SG_ B4 : 32|8@1+ (1,0) [0|255] "" Vector__XXX
 SG_ B5 : 40|8@1+ (1,0) [0|255] "" Vector__XXX
 SG_ B6 : 48|8@1+ (1,0) [0|255] "" Vector__XXX
 SG_ B7 : 56|8@1+ (1,0) [0|255] "" Vector__XXX

BA_ "VFrameFormat" BO_ 2566401694 1;
CM_ BO_ 2566401694 "0x5C0004 NO_CN_ROOT_ID | 部件: NO_CN_ROOT_ID";

BO_ 2566127895 ZT_ICM_18F40117: 8 Vector__XXX
 SG_ B0 : 0|8@1+ (1,0) [0|255] "" Vector__XXX
 SG_ B1 : 8|8@1+ (1,0) [0|255] "" Vector__XXX
 SG_ B2 : 16|8@1+ (1,0) [0|255] "" Vector__XXX
 SG_ B3 : 24|8@1+ (1,0) [0|255] "" Vector__XXX
 SG_ B4 : 32|8@1+ (1,0) [0|255] "" Vector__XXX
 SG_ B5 : 40|8@1+ (1,0) [0|255] "" Vector__XXX
 SG_ B6 : 48|8@1+ (1,0) [0|255] "" Vector__XXX
 SG_ B7 : 56|8@1+ (1,0) [0|255] "" Vector__XXX

BA_ "VFrameFormat" BO_ 2566127895 1;
CM_ BO_ 2566127895 "0x5C0005 中通新能源 > 中通物流 > 系统诊断 > 仪表系统(ICM) | 部件: 仪表系统(ICM)";

BO_ 2566128151 ZT_ICM_18F40217: 8 Vector__XXX
 SG_ B0 : 0|8@1+ (1,0) [0|255] "" Vector__XXX
 SG_ B1 : 8|8@1+ (1,0) [0|255] "" Vector__XXX
 SG_ B2 : 16|8@1+ (1,0) [0|255] "" Vector__XXX
 SG_ B3 : 24|8@1+ (1,0) [0|255] "" Vector__XXX
 SG_ B4 : 32|8@1+ (1,0) [0|255] "" Vector__XXX
 SG_ B5 : 40|8@1+ (1,0) [0|255] "" Vector__XXX
 SG_ B6 : 48|8@1+ (1,0) [0|255] "" Vector__XXX
 SG_ B7 : 56|8@1+ (1,0) [0|255] "" Vector__XXX

BA_ "VFrameFormat" BO_ 2566128151 1;
CM_ BO_ 2566128151 "0x5C0005 中通新能源 > 中通物流 > 系统诊断 > 仪表系统(ICM) | 部件: 仪表系统(ICM)";

BO_ 2486173589 ZT_EPS_142FFF95: 8 Vector__XXX
 SG_ B0 : 0|8@1+ (1,0) [0|255] "" Vector__XXX
 SG_ B1 : 8|8@1+ (1,0) [0|255] "" Vector__XXX
 SG_ B2 : 16|8@1+ (1,0) [0|255] "" Vector__XXX
 SG_ B3 : 24|8@1+ (1,0) [0|255] "" Vector__XXX
 SG_ B4 : 32|8@1+ (1,0) [0|255] "" Vector__XXX
 SG_ B5 : 40|8@1+ (1,0) [0|255] "" Vector__XXX
 SG_ B6 : 48|8@1+ (1,0) [0|255] "" Vector__XXX
 SG_ B7 : 56|8@1+ (1,0) [0|255] "" Vector__XXX

BA_ "VFrameFormat" BO_ 2486173589 1;
CM_ BO_ 2486173589 "0x5C0006 中通新能源 > 中通物流 > 系统诊断 > 电助力转向系统(EPS) | 部件: 电助力转向系统(EPS)";

BO_ 2485776789 ZT_EPS_1429F195: 8 Vector__XXX
 SG_ B0 : 0|8@1+ (1,0) [0|255] "" Vector__XXX
 SG_ B1 : 8|8@1+ (1,0) [0|255] "" Vector__XXX
 SG_ B2 : 16|8@1+ (1,0) [0|255] "" Vector__XXX
 SG_ B3 : 24|8@1+ (1,0) [0|255] "" Vector__XXX
 SG_ B4 : 32|8@1+ (1,0) [0|255] "" Vector__XXX
 SG_ B5 : 40|8@1+ (1,0) [0|255] "" Vector__XXX
 SG_ B6 : 48|8@1+ (1,0) [0|255] "" Vector__XXX
 SG_ B7 : 56|8@1+ (1,0) [0|255] "" Vector__XXX

BA_ "VFrameFormat" BO_ 2485776789 1;
CM_ BO_ 2485776789 "0x5C0006 中通新能源 > 中通物流 > 系统诊断 > 电助力转向系统(EPS) | 部件: 电助力转向系统(EPS)";

BO_ 2485976984 ZT_DCDC_142CFF98: 8 Vector__XXX
 SG_ B0 : 0|8@1+ (1,0) [0|255] "" Vector__XXX
 SG_ B1 : 8|8@1+ (1,0) [0|255] "" Vector__XXX
 SG_ B2 : 16|8@1+ (1,0) [0|255] "" Vector__XXX
 SG_ B3 : 24|8@1+ (1,0) [0|255] "" Vector__XXX
 SG_ B4 : 32|8@1+ (1,0) [0|255] "" Vector__XXX
 SG_ B5 : 40|8@1+ (1,0) [0|255] "" Vector__XXX
 SG_ B6 : 48|8@1+ (1,0) [0|255] "" Vector__XXX
 SG_ B7 : 56|8@1+ (1,0) [0|255] "" Vector__XXX

BA_ "VFrameFormat" BO_ 2485976984 1;
CM_ BO_ 2485976984 "0x5C0007 中通新能源 > 中通物流 > 系统诊断 > 直流变压器(DCDC) | 部件: 直流变压器(DCDC)";

BO_ 2485976981 ZT_DCDC_142CFF95: 8 Vector__XXX
 SG_ B0 : 0|8@1+ (1,0) [0|255] "" Vector__XXX
 SG_ B1 : 8|8@1+ (1,0) [0|255] "" Vector__XXX
 SG_ B2 : 16|8@1+ (1,0) [0|255] "" Vector__XXX
 SG_ B3 : 24|8@1+ (1,0) [0|255] "" Vector__XXX
 SG_ B4 : 32|8@1+ (1,0) [0|255] "" Vector__XXX
 SG_ B5 : 40|8@1+ (1,0) [0|255] "" Vector__XXX
 SG_ B6 : 48|8@1+ (1,0) [0|255] "" Vector__XXX
 SG_ B7 : 56|8@1+ (1,0) [0|255] "" Vector__XXX

BA_ "VFrameFormat" BO_ 2485976981 1;
CM_ BO_ 2485976981 "0x5C0007 中通新能源 > 中通物流 > 系统诊断 > 直流变压器(DCDC) | 部件: 直流变压器(DCDC)";

BO_ 2565931515 ZT_DVR_18F101FB: 8 Vector__XXX
 SG_ B0 : 0|8@1+ (1,0) [0|255] "" Vector__XXX
 SG_ B1 : 8|8@1+ (1,0) [0|255] "" Vector__XXX
 SG_ B2 : 16|8@1+ (1,0) [0|255] "" Vector__XXX
 SG_ B3 : 24|8@1+ (1,0) [0|255] "" Vector__XXX
 SG_ B4 : 32|8@1+ (1,0) [0|255] "" Vector__XXX
 SG_ B5 : 40|8@1+ (1,0) [0|255] "" Vector__XXX
 SG_ B6 : 48|8@1+ (1,0) [0|255] "" Vector__XXX
 SG_ B7 : 56|8@1+ (1,0) [0|255] "" Vector__XXX

BA_ "VFrameFormat" BO_ 2565931515 1;
CM_ BO_ 2565931515 "0x5C0008 中通新能源 > 中通物流 > 系统诊断 > 车载数据记录仪(DVR) | 部件: 车载数据记录仪(DVR)";

BO_ 2565931771 ZT_DVR_18F102FB: 8 Vector__XXX
 SG_ B0 : 0|8@1+ (1,0) [0|255] "" Vector__XXX
 SG_ B1 : 8|8@1+ (1,0) [0|255] "" Vector__XXX
 SG_ B2 : 16|8@1+ (1,0) [0|255] "" Vector__XXX
 SG_ B3 : 24|8@1+ (1,0) [0|255] "" Vector__XXX
 SG_ B4 : 32|8@1+ (1,0) [0|255] "" Vector__XXX
 SG_ B5 : 40|8@1+ (1,0) [0|255] "" Vector__XXX
 SG_ B6 : 48|8@1+ (1,0) [0|255] "" Vector__XXX
 SG_ B7 : 56|8@1+ (1,0) [0|255] "" Vector__XXX

BA_ "VFrameFormat" BO_ 2565931771 1;
CM_ BO_ 2565931771 "0x5C0008 中通新能源 > 中通物流 > 系统诊断 > 车载数据记录仪(DVR) | 部件: 车载数据记录仪(DVR)";

BO_ 2550255831 ZT_IMD_1801D0D7: 8 Vector__XXX
 SG_ B0 : 0|8@1+ (1,0) [0|255] "" Vector__XXX
 SG_ B1 : 8|8@1+ (1,0) [0|255] "" Vector__XXX
 SG_ B2 : 16|8@1+ (1,0) [0|255] "" Vector__XXX
 SG_ B3 : 24|8@1+ (1,0) [0|255] "" Vector__XXX
 SG_ B4 : 32|8@1+ (1,0) [0|255] "" Vector__XXX
 SG_ B5 : 40|8@1+ (1,0) [0|255] "" Vector__XXX
 SG_ B6 : 48|8@1+ (1,0) [0|255] "" Vector__XXX
 SG_ B7 : 56|8@1+ (1,0) [0|255] "" Vector__XXX

BA_ "VFrameFormat" BO_ 2550255831 1;
CM_ BO_ 2550255831 "0x5C0009 中通新能源 > 中通物流 > 系统诊断 > 绝缘检测仪(IMD) | 部件: 绝缘检测仪(IMD)";

BO_ 2349500655 ZT_VCU_0C0A88EF: 8 Vector__XXX
 SG_ B0 : 0|8@1+ (1,0) [0|255] "" Vector__XXX
 SG_ B1 : 8|8@1+ (1,0) [0|255] "" Vector__XXX
 SG_ B2 : 16|8@1+ (1,0) [0|255] "" Vector__XXX
 SG_ B3 : 24|8@1+ (1,0) [0|255] "" Vector__XXX
 SG_ B4 : 32|8@1+ (1,0) [0|255] "" Vector__XXX
 SG_ B5 : 40|8@1+ (1,0) [0|255] "" Vector__XXX
 SG_ B6 : 48|8@1+ (1,0) [0|255] "" Vector__XXX
 SG_ B7 : 56|8@1+ (1,0) [0|255] "" Vector__XXX

BA_ "VFrameFormat" BO_ 2349500655 1;
CM_ BO_ 2349500655 "0xB3000002 中通新能源 > 纯电动客车 > 10-12米纯电公交客车 > VCU 整车控制器 | 0xB300001F 中通新能源 > 纯电动客车 > 6米微巴客车 > VCU 整车控制器 | 0xB300003A 中通新能源 > 纯电动客车 > 8米纯电公交客车 > VCU 整车控制器 | 0xB3000067 中通新能源 > 纯电动客车 > 电动新大巴客车 > VCU 整车控制器 | 0xB3000083 中通新能源 > 燃料电池客车 > VCU 整车控制器 | 0xB30000A6 中通新能源 > 澳巴混合动力 > 7米澳巴混合动力客车 > VCU 整车控制器 | 0xB30000C7 中通新能源 > 澳巴混合动力 > 9米11米澳巴混合动力客车 > VCU 整车控制器 | 部件: VCU 整车控制器";

BO_ 2551185647 ZT_VCU_181000EF: 8 Vector__XXX
 SG_ B0 : 0|8@1+ (1,0) [0|255] "" Vector__XXX
 SG_ B1 : 8|8@1+ (1,0) [0|255] "" Vector__XXX
 SG_ B2 : 16|8@1+ (1,0) [0|255] "" Vector__XXX
 SG_ B3 : 24|8@1+ (1,0) [0|255] "" Vector__XXX
 SG_ B4 : 32|8@1+ (1,0) [0|255] "" Vector__XXX
 SG_ B5 : 40|8@1+ (1,0) [0|255] "" Vector__XXX
 SG_ B6 : 48|8@1+ (1,0) [0|255] "" Vector__XXX
 SG_ B7 : 56|8@1+ (1,0) [0|255] "" Vector__XXX

BA_ "VFrameFormat" BO_ 2551185647 1;
CM_ BO_ 2551185647 "0xB3000002 中通新能源 > 纯电动客车 > 10-12米纯电公交客车 > VCU 整车控制器 | 0xB300001F 中通新能源 > 纯电动客车 > 6米微巴客车 > VCU 整车控制器 | 0xB300003A 中通新能源 > 纯电动客车 > 8米纯电公交客车 > VCU 整车控制器 | 0xB3000067 中通新能源 > 纯电动客车 > 电动新大巴客车 > VCU 整车控制器 | 0xB3000083 中通新能源 > 燃料电池客车 > VCU 整车控制器 | 0xB30000A6 中通新能源 > 澳巴混合动力 > 7米澳巴混合动力客车 > VCU 整车控制器 | 0xB30000C7 中通新能源 > 澳巴混合动力 > 9米11米澳巴混合动力客车 > VCU 整车控制器 | 部件: VCU 整车控制器";

BO_ 2551251183 ZT_VCU_181100EF: 8 Vector__XXX
 SG_ B0 : 0|8@1+ (1,0) [0|255] "" Vector__XXX
 SG_ B1 : 8|8@1+ (1,0) [0|255] "" Vector__XXX
 SG_ B2 : 16|8@1+ (1,0) [0|255] "" Vector__XXX
 SG_ B3 : 24|8@1+ (1,0) [0|255] "" Vector__XXX
 SG_ B4 : 32|8@1+ (1,0) [0|255] "" Vector__XXX
 SG_ B5 : 40|8@1+ (1,0) [0|255] "" Vector__XXX
 SG_ B6 : 48|8@1+ (1,0) [0|255] "" Vector__XXX
 SG_ B7 : 56|8@1+ (1,0) [0|255] "" Vector__XXX

BA_ "VFrameFormat" BO_ 2551251183 1;
CM_ BO_ 2551251183 "0xB3000002 中通新能源 > 纯电动客车 > 10-12米纯电公交客车 > VCU 整车控制器 | 0xB300001F 中通新能源 > 纯电动客车 > 6米微巴客车 > VCU 整车控制器 | 0xB300003A 中通新能源 > 纯电动客车 > 8米纯电公交客车 > VCU 整车控制器 | 0xB3000067 中通新能源 > 纯电动客车 > 电动新大巴客车 > VCU 整车控制器 | 0xB3000083 中通新能源 > 燃料电池客车 > VCU 整车控制器 | 0xB30000A6 中通新能源 > 澳巴混合动力 > 7米澳巴混合动力客车 > VCU 整车控制器 | 0xB30000C7 中通新能源 > 澳巴混合动力 > 9米11米澳巴混合动力客车 > VCU 整车控制器 | 部件: VCU 整车控制器";

BO_ 2551382255 ZT_VCU_181300EF: 8 Vector__XXX
 SG_ B0 : 0|8@1+ (1,0) [0|255] "" Vector__XXX
 SG_ B1 : 8|8@1+ (1,0) [0|255] "" Vector__XXX
 SG_ B2 : 16|8@1+ (1,0) [0|255] "" Vector__XXX
 SG_ B3 : 24|8@1+ (1,0) [0|255] "" Vector__XXX
 SG_ B4 : 32|8@1+ (1,0) [0|255] "" Vector__XXX
 SG_ B5 : 40|8@1+ (1,0) [0|255] "" Vector__XXX
 SG_ B6 : 48|8@1+ (1,0) [0|255] "" Vector__XXX
 SG_ B7 : 56|8@1+ (1,0) [0|255] "" Vector__XXX

BA_ "VFrameFormat" BO_ 2551382255 1;
CM_ BO_ 2551382255 "0xB3000002 中通新能源 > 纯电动客车 > 10-12米纯电公交客车 > VCU 整车控制器 | 0xB300001F 中通新能源 > 纯电动客车 > 6米微巴客车 > VCU 整车控制器 | 0xB300003A 中通新能源 > 纯电动客车 > 8米纯电公交客车 > VCU 整车控制器 | 0xB3000067 中通新能源 > 纯电动客车 > 电动新大巴客车 > VCU 整车控制器 | 0xB3000083 中通新能源 > 燃料电池客车 > VCU 整车控制器 | 0xB30000A6 中通新能源 > 澳巴混合动力 > 7米澳巴混合动力客车 > VCU 整车控制器 | 0xB30000C7 中通新能源 > 澳巴混合动力 > 9米11米澳巴混合动力客车 > VCU 整车控制器 | 部件: VCU 整车控制器";

BO_ 2559645423 ZT_VCU_189116EF: 8 Vector__XXX
 SG_ B0 : 0|8@1+ (1,0) [0|255] "" Vector__XXX
 SG_ B1 : 8|8@1+ (1,0) [0|255] "" Vector__XXX
 SG_ B2 : 16|8@1+ (1,0) [0|255] "" Vector__XXX
 SG_ B3 : 24|8@1+ (1,0) [0|255] "" Vector__XXX
 SG_ B4 : 32|8@1+ (1,0) [0|255] "" Vector__XXX
 SG_ B5 : 40|8@1+ (1,0) [0|255] "" Vector__XXX
 SG_ B6 : 48|8@1+ (1,0) [0|255] "" Vector__XXX
 SG_ B7 : 56|8@1+ (1,0) [0|255] "" Vector__XXX

BA_ "VFrameFormat" BO_ 2559645423 1;
CM_ BO_ 2559645423 "0xB3000002 中通新能源 > 纯电动客车 > 10-12米纯电公交客车 > VCU 整车控制器 | 0xB300001F 中通新能源 > 纯电动客车 > 6米微巴客车 > VCU 整车控制器 | 0xB300003A 中通新能源 > 纯电动客车 > 8米纯电公交客车 > VCU 整车控制器 | 0xB3000067 中通新能源 > 纯电动客车 > 电动新大巴客车 > VCU 整车控制器 | 0xB3000083 中通新能源 > 燃料电池客车 > VCU 整车控制器 | 0xB30000A6 中通新能源 > 澳巴混合动力 > 7米澳巴混合动力客车 > VCU 整车控制器 | 0xB30000C7 中通新能源 > 澳巴混合动力 > 9米11米澳巴混合动力客车 > VCU 整车控制器 | 部件: VCU 整车控制器";

BO_ 2566658031 ZT_VCU_18FC17EF: 8 Vector__XXX
 SG_ B0 : 0|8@1+ (1,0) [0|255] "" Vector__XXX
 SG_ B1 : 8|8@1+ (1,0) [0|255] "" Vector__XXX
 SG_ B2 : 16|8@1+ (1,0) [0|255] "" Vector__XXX
 SG_ B3 : 24|8@1+ (1,0) [0|255] "" Vector__XXX
 SG_ B4 : 32|8@1+ (1,0) [0|255] "" Vector__XXX
 SG_ B5 : 40|8@1+ (1,0) [0|255] "" Vector__XXX
 SG_ B6 : 48|8@1+ (1,0) [0|255] "" Vector__XXX
 SG_ B7 : 56|8@1+ (1,0) [0|255] "" Vector__XXX

BA_ "VFrameFormat" BO_ 2566658031 1;
CM_ BO_ 2566658031 "0xB3000002 中通新能源 > 纯电动客车 > 10-12米纯电公交客车 > VCU 整车控制器 | 0xB300001F 中通新能源 > 纯电动客车 > 6米微巴客车 > VCU 整车控制器 | 0xB300003A 中通新能源 > 纯电动客车 > 8米纯电公交客车 > VCU 整车控制器 | 0xB3000067 中通新能源 > 纯电动客车 > 电动新大巴客车 > VCU 整车控制器 | 0xB3000083 中通新能源 > 燃料电池客车 > VCU 整车控制器 | 0xB30000A6 中通新能源 > 澳巴混合动力 > 7米澳巴混合动力客车 > VCU 整车控制器 | 0xB30000C7 中通新能源 > 澳巴混合动力 > 9米11米澳巴混合动力客车 > VCU 整车控制器 | 部件: VCU 整车控制器";

BO_ 2566723567 ZT_VCU_18FD17EF: 8 Vector__XXX
 SG_ B0 : 0|8@1+ (1,0) [0|255] "" Vector__XXX
 SG_ B1 : 8|8@1+ (1,0) [0|255] "" Vector__XXX
 SG_ B2 : 16|8@1+ (1,0) [0|255] "" Vector__XXX
 SG_ B3 : 24|8@1+ (1,0) [0|255] "" Vector__XXX
 SG_ B4 : 32|8@1+ (1,0) [0|255] "" Vector__XXX
 SG_ B5 : 40|8@1+ (1,0) [0|255] "" Vector__XXX
 SG_ B6 : 48|8@1+ (1,0) [0|255] "" Vector__XXX
 SG_ B7 : 56|8@1+ (1,0) [0|255] "" Vector__XXX

BA_ "VFrameFormat" BO_ 2566723567 1;
CM_ BO_ 2566723567 "0xB3000002 中通新能源 > 纯电动客车 > 10-12米纯电公交客车 > VCU 整车控制器 | 0xB300001F 中通新能源 > 纯电动客车 > 6米微巴客车 > VCU 整车控制器 | 0xB300003A 中通新能源 > 纯电动客车 > 8米纯电公交客车 > VCU 整车控制器 | 0xB3000067 中通新能源 > 纯电动客车 > 电动新大巴客车 > VCU 整车控制器 | 0xB3000083 中通新能源 > 燃料电池客车 > VCU 整车控制器 | 0xB30000A6 中通新能源 > 澳巴混合动力 > 7米澳巴混合动力客车 > VCU 整车控制器 | 0xB30000C7 中通新能源 > 澳巴混合动力 > 9米11米澳巴混合动力客车 > VCU 整车控制器 | 部件: VCU 整车控制器";

BO_ 2566789103 ZT_VCU_18FE17EF: 8 Vector__XXX
 SG_ B0 : 0|8@1+ (1,0) [0|255] "" Vector__XXX
 SG_ B1 : 8|8@1+ (1,0) [0|255] "" Vector__XXX
 SG_ B2 : 16|8@1+ (1,0) [0|255] "" Vector__XXX
 SG_ B3 : 24|8@1+ (1,0) [0|255] "" Vector__XXX
 SG_ B4 : 32|8@1+ (1,0) [0|255] "" Vector__XXX
 SG_ B5 : 40|8@1+ (1,0) [0|255] "" Vector__XXX
 SG_ B6 : 48|8@1+ (1,0) [0|255] "" Vector__XXX
 SG_ B7 : 56|8@1+ (1,0) [0|255] "" Vector__XXX

BA_ "VFrameFormat" BO_ 2566789103 1;
CM_ BO_ 2566789103 "0xB3000002 中通新能源 > 纯电动客车 > 10-12米纯电公交客车 > VCU 整车控制器 | 0xB300001F 中通新能源 > 纯电动客车 > 6米微巴客车 > VCU 整车控制器 | 0xB300003A 中通新能源 > 纯电动客车 > 8米纯电公交客车 > VCU 整车控制器 | 0xB3000067 中通新能源 > 纯电动客车 > 电动新大巴客车 > VCU 整车控制器 | 0xB3000083 中通新能源 > 燃料电池客车 > VCU 整车控制器 | 0xB30000A6 中通新能源 > 澳巴混合动力 > 7米澳巴混合动力客车 > VCU 整车控制器 | 0xB30000C7 中通新能源 > 澳巴混合动力 > 9米11米澳巴混合动力客车 > VCU 整车控制器 | 部件: VCU 整车控制器";

BO_ 2566849519 ZT_VCU_18FF03EF: 8 Vector__XXX
 SG_ B0 : 0|8@1+ (1,0) [0|255] "" Vector__XXX
 SG_ B1 : 8|8@1+ (1,0) [0|255] "" Vector__XXX
 SG_ B2 : 16|8@1+ (1,0) [0|255] "" Vector__XXX
 SG_ B3 : 24|8@1+ (1,0) [0|255] "" Vector__XXX
 SG_ B4 : 32|8@1+ (1,0) [0|255] "" Vector__XXX
 SG_ B5 : 40|8@1+ (1,0) [0|255] "" Vector__XXX
 SG_ B6 : 48|8@1+ (1,0) [0|255] "" Vector__XXX
 SG_ B7 : 56|8@1+ (1,0) [0|255] "" Vector__XXX

BA_ "VFrameFormat" BO_ 2566849519 1;
CM_ BO_ 2566849519 "0xB3000002 中通新能源 > 纯电动客车 > 10-12米纯电公交客车 > VCU 整车控制器 | 0xB300001F 中通新能源 > 纯电动客车 > 6米微巴客车 > VCU 整车控制器 | 0xB300003A 中通新能源 > 纯电动客车 > 8米纯电公交客车 > VCU 整车控制器 | 0xB3000067 中通新能源 > 纯电动客车 > 电动新大巴客车 > VCU 整车控制器 | 0xB3000083 中通新能源 > 燃料电池客车 > VCU 整车控制器 | 0xB30000A6 中通新能源 > 澳巴混合动力 > 7米澳巴混合动力客车 > VCU 整车控制器 | 0xB30000C7 中通新能源 > 澳巴混合动力 > 9米11米澳巴混合动力客车 > VCU 整车控制器 | 部件: VCU 整车控制器";

BO_ 2566854639 ZT_VCU_18FF17EF: 8 Vector__XXX
 SG_ B0 : 0|8@1+ (1,0) [0|255] "" Vector__XXX
 SG_ B1 : 8|8@1+ (1,0) [0|255] "" Vector__XXX
 SG_ B2 : 16|8@1+ (1,0) [0|255] "" Vector__XXX
 SG_ B3 : 24|8@1+ (1,0) [0|255] "" Vector__XXX
 SG_ B4 : 32|8@1+ (1,0) [0|255] "" Vector__XXX
 SG_ B5 : 40|8@1+ (1,0) [0|255] "" Vector__XXX
 SG_ B6 : 48|8@1+ (1,0) [0|255] "" Vector__XXX
 SG_ B7 : 56|8@1+ (1,0) [0|255] "" Vector__XXX

BA_ "VFrameFormat" BO_ 2566854639 1;
CM_ BO_ 2566854639 "0xB3000002 中通新能源 > 纯电动客车 > 10-12米纯电公交客车 > VCU 整车控制器 | 0xB300001F 中通新能源 > 纯电动客车 > 6米微巴客车 > VCU 整车控制器 | 0xB300003A 中通新能源 > 纯电动客车 > 8米纯电公交客车 > VCU 整车控制器 | 0xB3000067 中通新能源 > 纯电动客车 > 电动新大巴客车 > VCU 整车控制器 | 0xB3000083 中通新能源 > 燃料电池客车 > VCU 整车控制器 | 0xB30000A6 中通新能源 > 澳巴混合动力 > 7米澳巴混合动力客车 > VCU 整车控制器 | 0xB30000C7 中通新能源 > 澳巴混合动力 > 9米11米澳巴混合动力客车 > VCU 整车控制器 | 部件: VCU 整车控制器";

BO_ 2566855407 ZT_VCU_18FF1AEF: 8 Vector__XXX
 SG_ B0 : 0|8@1+ (1,0) [0|255] "" Vector__XXX
 SG_ B1 : 8|8@1+ (1,0) [0|255] "" Vector__XXX
 SG_ B2 : 16|8@1+ (1,0) [0|255] "" Vector__XXX
 SG_ B3 : 24|8@1+ (1,0) [0|255] "" Vector__XXX
 SG_ B4 : 32|8@1+ (1,0) [0|255] "" Vector__XXX
 SG_ B5 : 40|8@1+ (1,0) [0|255] "" Vector__XXX
 SG_ B6 : 48|8@1+ (1,0) [0|255] "" Vector__XXX
 SG_ B7 : 56|8@1+ (1,0) [0|255] "" Vector__XXX

BA_ "VFrameFormat" BO_ 2566855407 1;
CM_ BO_ 2566855407 "0xB3000002 中通新能源 > 纯电动客车 > 10-12米纯电公交客车 > VCU 整车控制器 | 0xB300001F 中通新能源 > 纯电动客车 > 6米微巴客车 > VCU 整车控制器 | 0xB300003A 中通新能源 > 纯电动客车 > 8米纯电公交客车 > VCU 整车控制器 | 0xB3000067 中通新能源 > 纯电动客车 > 电动新大巴客车 > VCU 整车控制器 | 0xB3000083 中通新能源 > 燃料电池客车 > VCU 整车控制器 | 0xB30000A6 中通新能源 > 澳巴混合动力 > 7米澳巴混合动力客车 > VCU 整车控制器 | 0xB30000C7 中通新能源 > 澳巴混合动力 > 9米11米澳巴混合动力客车 > VCU 整车控制器 | 部件: VCU 整车控制器";

BO_ 2566867695 ZT_VCU_18FF4AEF: 8 Vector__XXX
 SG_ B0 : 0|8@1+ (1,0) [0|255] "" Vector__XXX
 SG_ B1 : 8|8@1+ (1,0) [0|255] "" Vector__XXX
 SG_ B2 : 16|8@1+ (1,0) [0|255] "" Vector__XXX
 SG_ B3 : 24|8@1+ (1,0) [0|255] "" Vector__XXX
 SG_ B4 : 32|8@1+ (1,0) [0|255] "" Vector__XXX
 SG_ B5 : 40|8@1+ (1,0) [0|255] "" Vector__XXX
 SG_ B6 : 48|8@1+ (1,0) [0|255] "" Vector__XXX
 SG_ B7 : 56|8@1+ (1,0) [0|255] "" Vector__XXX

BA_ "VFrameFormat" BO_ 2566867695 1;
CM_ BO_ 2566867695 "0xB3000002 中通新能源 > 纯电动客车 > 10-12米纯电公交客车 > VCU 整车控制器 | 0xB300001F 中通新能源 > 纯电动客车 > 6米微巴客车 > VCU 整车控制器 | 0xB300003A 中通新能源 > 纯电动客车 > 8米纯电公交客车 > VCU 整车控制器 | 0xB3000067 中通新能源 > 纯电动客车 > 电动新大巴客车 > VCU 整车控制器 | 0xB3000083 中通新能源 > 燃料电池客车 > VCU 整车控制器 | 0xB30000A6 中通新能源 > 澳巴混合动力 > 7米澳巴混合动力客车 > VCU 整车控制器 | 0xB30000C7 中通新能源 > 澳巴混合动力 > 9米11米澳巴混合动力客车 > VCU 整车控制器 | 部件: VCU 整车控制器";

BO_ 2365524207 ZT_VCU_0CFF08EF: 8 Vector__XXX
 SG_ B0 : 0|8@1+ (1,0) [0|255] "" Vector__XXX
 SG_ B1 : 8|8@1+ (1,0) [0|255] "" Vector__XXX
 SG_ B2 : 16|8@1+ (1,0) [0|255] "" Vector__XXX
 SG_ B3 : 24|8@1+ (1,0) [0|255] "" Vector__XXX
 SG_ B4 : 32|8@1+ (1,0) [0|255] "" Vector__XXX
 SG_ B5 : 40|8@1+ (1,0) [0|255] "" Vector__XXX
 SG_ B6 : 48|8@1+ (1,0) [0|255] "" Vector__XXX
 SG_ B7 : 56|8@1+ (1,0) [0|255] "" Vector__XXX

BA_ "VFrameFormat" BO_ 2365524207 1;
CM_ BO_ 2365524207 "0xB3000002 中通新能源 > 纯电动客车 > 10-12米纯电公交客车 > VCU 整车控制器 | 0xB3000083 中通新能源 > 燃料电池客车 > VCU 整车控制器 | 0xB30000A6 中通新能源 > 澳巴混合动力 > 7米澳巴混合动力客车 > VCU 整车控制器 | 0xB30000C7 中通新能源 > 澳巴混合动力 > 9米11米澳巴混合动力客车 > VCU 整车控制器 | 部件: VCU 整车控制器";

BO_ 2365521928 ZT_MCU_0CFF0008: 8 Vector__XXX
 SG_ B0 : 0|8@1+ (1,0) [0|255] "" Vector__XXX
 SG_ B1 : 8|8@1+ (1,0) [0|255] "" Vector__XXX
 SG_ B2 : 16|8@1+ (1,0) [0|255] "" Vector__XXX
 SG_ B3 : 24|8@1+ (1,0) [0|255] "" Vector__XXX
 SG_ B4 : 32|8@1+ (1,0) [0|255] "" Vector__XXX
 SG_ B5 : 40|8@1+ (1,0) [0|255] "" Vector__XXX
 SG_ B6 : 48|8@1+ (1,0) [0|255] "" Vector__XXX
 SG_ B7 : 56|8@1+ (1,0) [0|255] "" Vector__XXX

BA_ "VFrameFormat" BO_ 2365521928 1;
CM_ BO_ 2365521928 "0xB3000003 中通新能源 > 纯电动客车 > 10-12米纯电公交客车 > MCU 主驱电机控制器 | 0xB3000084 中通新能源 > 燃料电池客车 > MCU 主驱电机控制器 | 0xB30000A7 中通新能源 > 澳巴混合动力 > 7米澳巴混合动力客车 > MCU 主驱电机控制器 | 0xB30000C8 中通新能源 > 澳巴混合动力 > 9米11米澳巴混合动力客车 > MCU 主驱电机控制器 | 部件: MCU 主驱电机控制器";

BO_ 2365522184 ZT_MCU_0CFF0108: 8 Vector__XXX
 SG_ B0 : 0|8@1+ (1,0) [0|255] "" Vector__XXX
 SG_ B1 : 8|8@1+ (1,0) [0|255] "" Vector__XXX
 SG_ B2 : 16|8@1+ (1,0) [0|255] "" Vector__XXX
 SG_ B3 : 24|8@1+ (1,0) [0|255] "" Vector__XXX
 SG_ B4 : 32|8@1+ (1,0) [0|255] "" Vector__XXX
 SG_ B5 : 40|8@1+ (1,0) [0|255] "" Vector__XXX
 SG_ B6 : 48|8@1+ (1,0) [0|255] "" Vector__XXX
 SG_ B7 : 56|8@1+ (1,0) [0|255] "" Vector__XXX

BA_ "VFrameFormat" BO_ 2365522184 1;
CM_ BO_ 2365522184 "0xB3000003 中通新能源 > 纯电动客车 > 10-12米纯电公交客车 > MCU 主驱电机控制器 | 0xB3000084 中通新能源 > 燃料电池客车 > MCU 主驱电机控制器 | 0xB30000A7 中通新能源 > 澳巴混合动力 > 7米澳巴混合动力客车 > MCU 主驱电机控制器 | 0xB30000C8 中通新能源 > 澳巴混合动力 > 9米11米澳巴混合动力客车 > MCU 主驱电机控制器 | 部件: MCU 主驱电机控制器";

BO_ 2365522440 ZT_MCU_0CFF0208: 8 Vector__XXX
 SG_ B0 : 0|8@1+ (1,0) [0|255] "" Vector__XXX
 SG_ B1 : 8|8@1+ (1,0) [0|255] "" Vector__XXX
 SG_ B2 : 16|8@1+ (1,0) [0|255] "" Vector__XXX
 SG_ B3 : 24|8@1+ (1,0) [0|255] "" Vector__XXX
 SG_ B4 : 32|8@1+ (1,0) [0|255] "" Vector__XXX
 SG_ B5 : 40|8@1+ (1,0) [0|255] "" Vector__XXX
 SG_ B6 : 48|8@1+ (1,0) [0|255] "" Vector__XXX
 SG_ B7 : 56|8@1+ (1,0) [0|255] "" Vector__XXX

BA_ "VFrameFormat" BO_ 2365522440 1;
CM_ BO_ 2365522440 "0xB3000003 中通新能源 > 纯电动客车 > 10-12米纯电公交客车 > MCU 主驱电机控制器 | 0xB3000084 中通新能源 > 燃料电池客车 > MCU 主驱电机控制器 | 0xB30000A7 中通新能源 > 澳巴混合动力 > 7米澳巴混合动力客车 > MCU 主驱电机控制器 | 0xB30000C8 中通新能源 > 澳巴混合动力 > 9米11米澳巴混合动力客车 > MCU 主驱电机控制器 | 部件: MCU 主驱电机控制器";

BO_ 2365522696 ZT_MCU_0CFF0308: 8 Vector__XXX
 SG_ B0 : 0|8@1+ (1,0) [0|255] "" Vector__XXX
 SG_ B1 : 8|8@1+ (1,0) [0|255] "" Vector__XXX
 SG_ B2 : 16|8@1+ (1,0) [0|255] "" Vector__XXX
 SG_ B3 : 24|8@1+ (1,0) [0|255] "" Vector__XXX
 SG_ B4 : 32|8@1+ (1,0) [0|255] "" Vector__XXX
 SG_ B5 : 40|8@1+ (1,0) [0|255] "" Vector__XXX
 SG_ B6 : 48|8@1+ (1,0) [0|255] "" Vector__XXX
 SG_ B7 : 56|8@1+ (1,0) [0|255] "" Vector__XXX

BA_ "VFrameFormat" BO_ 2365522696 1;
CM_ BO_ 2365522696 "0xB3000003 中通新能源 > 纯电动客车 > 10-12米纯电公交客车 > MCU 主驱电机控制器 | 0xB3000084 中通新能源 > 燃料电池客车 > MCU 主驱电机控制器 | 0xB30000A7 中通新能源 > 澳巴混合动力 > 7米澳巴混合动力客车 > MCU 主驱电机控制器 | 0xB30000C8 中通新能源 > 澳巴混合动力 > 9米11米澳巴混合动力客车 > MCU 主驱电机控制器 | 部件: MCU 主驱电机控制器";

BO_ 2365522952 ZT_MCU_0CFF0408: 8 Vector__XXX
 SG_ B0 : 0|8@1+ (1,0) [0|255] "" Vector__XXX
 SG_ B1 : 8|8@1+ (1,0) [0|255] "" Vector__XXX
 SG_ B2 : 16|8@1+ (1,0) [0|255] "" Vector__XXX
 SG_ B3 : 24|8@1+ (1,0) [0|255] "" Vector__XXX
 SG_ B4 : 32|8@1+ (1,0) [0|255] "" Vector__XXX
 SG_ B5 : 40|8@1+ (1,0) [0|255] "" Vector__XXX
 SG_ B6 : 48|8@1+ (1,0) [0|255] "" Vector__XXX
 SG_ B7 : 56|8@1+ (1,0) [0|255] "" Vector__XXX

BA_ "VFrameFormat" BO_ 2365522952 1;
CM_ BO_ 2365522952 "0xB3000003 中通新能源 > 纯电动客车 > 10-12米纯电公交客车 > MCU 主驱电机控制器 | 0xB3000084 中通新能源 > 燃料电池客车 > MCU 主驱电机控制器 | 0xB30000A7 中通新能源 > 澳巴混合动力 > 7米澳巴混合动力客车 > MCU 主驱电机控制器 | 0xB30000C8 中通新能源 > 澳巴混合动力 > 9米11米澳巴混合动力客车 > MCU 主驱电机控制器 | 部件: MCU 主驱电机控制器";

BO_ 2565931507 ZT_BMS_18F101F3: 8 Vector__XXX
 SG_ B0 : 0|8@1+ (1,0) [0|255] "" Vector__XXX
 SG_ B1 : 8|8@1+ (1,0) [0|255] "" Vector__XXX
 SG_ B2 : 16|8@1+ (1,0) [0|255] "" Vector__XXX
 SG_ B3 : 24|8@1+ (1,0) [0|255] "" Vector__XXX
 SG_ B4 : 32|8@1+ (1,0) [0|255] "" Vector__XXX
 SG_ B5 : 40|8@1+ (1,0) [0|255] "" Vector__XXX
 SG_ B6 : 48|8@1+ (1,0) [0|255] "" Vector__XXX
 SG_ B7 : 56|8@1+ (1,0) [0|255] "" Vector__XXX

BA_ "VFrameFormat" BO_ 2565931507 1;
CM_ BO_ 2565931507 "0xB3000005 中通新能源 > 纯电动客车 > 10-12米纯电公交客车 > 电池管理系统 | 0xB3000022 中通新能源 > 纯电动客车 > 6米微巴客车 > 电池管理系统 | 0xB300003D 中通新能源 > 纯电动客车 > 8米纯电公交客车 > 电池管理系统 | 0xB300006A 中通新能源 > 纯电动客车 > 电动新大巴客车 > 电池管理系统 | 0xB3000086 中通新能源 > 燃料电池客车 > 电池管理系统 | 0xB30000A8 中通新能源 > 澳巴混合动力 > 7米澳巴混合动力客车 > 电池管理系统 | 0xB30000C9 中通新能源 > 澳巴混合动力 > 9米11米澳巴混合动力客车 > 电池管理系统 | 部件: 电池管理系统";

BO_ 2565931763 ZT_BMS_18F102F3: 8 Vector__XXX
 SG_ B0 : 0|8@1+ (1,0) [0|255] "" Vector__XXX
 SG_ B1 : 8|8@1+ (1,0) [0|255] "" Vector__XXX
 SG_ B2 : 16|8@1+ (1,0) [0|255] "" Vector__XXX
 SG_ B3 : 24|8@1+ (1,0) [0|255] "" Vector__XXX
 SG_ B4 : 32|8@1+ (1,0) [0|255] "" Vector__XXX
 SG_ B5 : 40|8@1+ (1,0) [0|255] "" Vector__XXX
 SG_ B6 : 48|8@1+ (1,0) [0|255] "" Vector__XXX
 SG_ B7 : 56|8@1+ (1,0) [0|255] "" Vector__XXX

BA_ "VFrameFormat" BO_ 2565931763 1;
CM_ BO_ 2565931763 "0xB3000005 中通新能源 > 纯电动客车 > 10-12米纯电公交客车 > 电池管理系统 | 0xB3000022 中通新能源 > 纯电动客车 > 6米微巴客车 > 电池管理系统 | 0xB300003D 中通新能源 > 纯电动客车 > 8米纯电公交客车 > 电池管理系统 | 0xB300006A 中通新能源 > 纯电动客车 > 电动新大巴客车 > 电池管理系统 | 0xB3000086 中通新能源 > 燃料电池客车 > 电池管理系统 | 0xB30000A8 中通新能源 > 澳巴混合动力 > 7米澳巴混合动力客车 > 电池管理系统 | 0xB30000C9 中通新能源 > 澳巴混合动力 > 9米11米澳巴混合动力客车 > 电池管理系统 | 部件: 电池管理系统";

BO_ 2565932019 ZT_BMS_18F103F3: 8 Vector__XXX
 SG_ B0 : 0|8@1+ (1,0) [0|255] "" Vector__XXX
 SG_ B1 : 8|8@1+ (1,0) [0|255] "" Vector__XXX
 SG_ B2 : 16|8@1+ (1,0) [0|255] "" Vector__XXX
 SG_ B3 : 24|8@1+ (1,0) [0|255] "" Vector__XXX
 SG_ B4 : 32|8@1+ (1,0) [0|255] "" Vector__XXX
 SG_ B5 : 40|8@1+ (1,0) [0|255] "" Vector__XXX
 SG_ B6 : 48|8@1+ (1,0) [0|255] "" Vector__XXX
 SG_ B7 : 56|8@1+ (1,0) [0|255] "" Vector__XXX

BA_ "VFrameFormat" BO_ 2565932019 1;
CM_ BO_ 2565932019 "0xB3000005 中通新能源 > 纯电动客车 > 10-12米纯电公交客车 > 电池管理系统 | 0xB3000022 中通新能源 > 纯电动客车 > 6米微巴客车 > 电池管理系统 | 0xB300003D 中通新能源 > 纯电动客车 > 8米纯电公交客车 > 电池管理系统 | 0xB300006A 中通新能源 > 纯电动客车 > 电动新大巴客车 > 电池管理系统 | 0xB3000086 中通新能源 > 燃料电池客车 > 电池管理系统 | 0xB30000A8 中通新能源 > 澳巴混合动力 > 7米澳巴混合动力客车 > 电池管理系统 | 0xB30000C9 中通新能源 > 澳巴混合动力 > 9米11米澳巴混合动力客车 > 电池管理系统 | 部件: 电池管理系统";

BO_ 2565932275 ZT_BMS_18F104F3: 8 Vector__XXX
 SG_ B0 : 0|8@1+ (1,0) [0|255] "" Vector__XXX
 SG_ B1 : 8|8@1+ (1,0) [0|255] "" Vector__XXX
 SG_ B2 : 16|8@1+ (1,0) [0|255] "" Vector__XXX
 SG_ B3 : 24|8@1+ (1,0) [0|255] "" Vector__XXX
 SG_ B4 : 32|8@1+ (1,0) [0|255] "" Vector__XXX
 SG_ B5 : 40|8@1+ (1,0) [0|255] "" Vector__XXX
 SG_ B6 : 48|8@1+ (1,0) [0|255] "" Vector__XXX
 SG_ B7 : 56|8@1+ (1,0) [0|255] "" Vector__XXX

BA_ "VFrameFormat" BO_ 2565932275 1;
CM_ BO_ 2565932275 "0xB3000005 中通新能源 > 纯电动客车 > 10-12米纯电公交客车 > 电池管理系统 | 0xB3000022 中通新能源 > 纯电动客车 > 6米微巴客车 > 电池管理系统 | 0xB300003D 中通新能源 > 纯电动客车 > 8米纯电公交客车 > 电池管理系统 | 0xB300006A 中通新能源 > 纯电动客车 > 电动新大巴客车 > 电池管理系统 | 0xB3000086 中通新能源 > 燃料电池客车 > 电池管理系统 | 0xB30000A8 中通新能源 > 澳巴混合动力 > 7米澳巴混合动力客车 > 电池管理系统 | 0xB30000C9 中通新能源 > 澳巴混合动力 > 9米11米澳巴混合动力客车 > 电池管理系统 | 部件: 电池管理系统";

BO_ 2565932531 ZT_BMS_18F105F3: 8 Vector__XXX
 SG_ B0 : 0|8@1+ (1,0) [0|255] "" Vector__XXX
 SG_ B1 : 8|8@1+ (1,0) [0|255] "" Vector__XXX
 SG_ B2 : 16|8@1+ (1,0) [0|255] "" Vector__XXX
 SG_ B3 : 24|8@1+ (1,0) [0|255] "" Vector__XXX
 SG_ B4 : 32|8@1+ (1,0) [0|255] "" Vector__XXX
 SG_ B5 : 40|8@1+ (1,0) [0|255] "" Vector__XXX
 SG_ B6 : 48|8@1+ (1,0) [0|255] "" Vector__XXX
 SG_ B7 : 56|8@1+ (1,0) [0|255] "" Vector__XXX

BA_ "VFrameFormat" BO_ 2565932531 1;
CM_ BO_ 2565932531 "0xB3000005 中通新能源 > 纯电动客车 > 10-12米纯电公交客车 > 电池管理系统 | 0xB3000022 中通新能源 > 纯电动客车 > 6米微巴客车 > 电池管理系统 | 0xB300003D 中通新能源 > 纯电动客车 > 8米纯电公交客车 > 电池管理系统 | 0xB300006A 中通新能源 > 纯电动客车 > 电动新大巴客车 > 电池管理系统 | 0xB3000086 中通新能源 > 燃料电池客车 > 电池管理系统 | 0xB30000A8 中通新能源 > 澳巴混合动力 > 7米澳巴混合动力客车 > 电池管理系统 | 0xB30000C9 中通新能源 > 澳巴混合动力 > 9米11米澳巴混合动力客车 > 电池管理系统 | 部件: 电池管理系统";

BO_ 2565932787 ZT_BMS_18F106F3: 8 Vector__XXX
 SG_ B0 : 0|8@1+ (1,0) [0|255] "" Vector__XXX
 SG_ B1 : 8|8@1+ (1,0) [0|255] "" Vector__XXX
 SG_ B2 : 16|8@1+ (1,0) [0|255] "" Vector__XXX
 SG_ B3 : 24|8@1+ (1,0) [0|255] "" Vector__XXX
 SG_ B4 : 32|8@1+ (1,0) [0|255] "" Vector__XXX
 SG_ B5 : 40|8@1+ (1,0) [0|255] "" Vector__XXX
 SG_ B6 : 48|8@1+ (1,0) [0|255] "" Vector__XXX
 SG_ B7 : 56|8@1+ (1,0) [0|255] "" Vector__XXX

BA_ "VFrameFormat" BO_ 2565932787 1;
CM_ BO_ 2565932787 "0xB3000005 中通新能源 > 纯电动客车 > 10-12米纯电公交客车 > 电池管理系统 | 0xB3000022 中通新能源 > 纯电动客车 > 6米微巴客车 > 电池管理系统 | 0xB300003D 中通新能源 > 纯电动客车 > 8米纯电公交客车 > 电池管理系统 | 0xB300006A 中通新能源 > 纯电动客车 > 电动新大巴客车 > 电池管理系统 | 0xB3000086 中通新能源 > 燃料电池客车 > 电池管理系统 | 0xB30000A8 中通新能源 > 澳巴混合动力 > 7米澳巴混合动力客车 > 电池管理系统 | 0xB30000C9 中通新能源 > 澳巴混合动力 > 9米11米澳巴混合动力客车 > 电池管理系统 | 部件: 电池管理系统";

BO_ 2565933043 ZT_BMS_18F107F3: 8 Vector__XXX
 SG_ B0 : 0|8@1+ (1,0) [0|255] "" Vector__XXX
 SG_ B1 : 8|8@1+ (1,0) [0|255] "" Vector__XXX
 SG_ B2 : 16|8@1+ (1,0) [0|255] "" Vector__XXX
 SG_ B3 : 24|8@1+ (1,0) [0|255] "" Vector__XXX
 SG_ B4 : 32|8@1+ (1,0) [0|255] "" Vector__XXX
 SG_ B5 : 40|8@1+ (1,0) [0|255] "" Vector__XXX
 SG_ B6 : 48|8@1+ (1,0) [0|255] "" Vector__XXX
 SG_ B7 : 56|8@1+ (1,0) [0|255] "" Vector__XXX

BA_ "VFrameFormat" BO_ 2565933043 1;
CM_ BO_ 2565933043 "0xB3000005 中通新能源 > 纯电动客车 > 10-12米纯电公交客车 > 电池管理系统 | 0xB3000022 中通新能源 > 纯电动客车 > 6米微巴客车 > 电池管理系统 | 0xB300003D 中通新能源 > 纯电动客车 > 8米纯电公交客车 > 电池管理系统 | 0xB300006A 中通新能源 > 纯电动客车 > 电动新大巴客车 > 电池管理系统 | 0xB3000086 中通新能源 > 燃料电池客车 > 电池管理系统 | 0xB30000A8 中通新能源 > 澳巴混合动力 > 7米澳巴混合动力客车 > 电池管理系统 | 0xB30000C9 中通新能源 > 澳巴混合动力 > 9米11米澳巴混合动力客车 > 电池管理系统 | 部件: 电池管理系统";

BO_ 2565933299 ZT_BMS_18F108F3: 8 Vector__XXX
 SG_ B0 : 0|8@1+ (1,0) [0|255] "" Vector__XXX
 SG_ B1 : 8|8@1+ (1,0) [0|255] "" Vector__XXX
 SG_ B2 : 16|8@1+ (1,0) [0|255] "" Vector__XXX
 SG_ B3 : 24|8@1+ (1,0) [0|255] "" Vector__XXX
 SG_ B4 : 32|8@1+ (1,0) [0|255] "" Vector__XXX
 SG_ B5 : 40|8@1+ (1,0) [0|255] "" Vector__XXX
 SG_ B6 : 48|8@1+ (1,0) [0|255] "" Vector__XXX
 SG_ B7 : 56|8@1+ (1,0) [0|255] "" Vector__XXX

BA_ "VFrameFormat" BO_ 2565933299 1;
CM_ BO_ 2565933299 "0xB3000005 中通新能源 > 纯电动客车 > 10-12米纯电公交客车 > 电池管理系统 | 0xB3000022 中通新能源 > 纯电动客车 > 6米微巴客车 > 电池管理系统 | 0xB300003D 中通新能源 > 纯电动客车 > 8米纯电公交客车 > 电池管理系统 | 0xB300006A 中通新能源 > 纯电动客车 > 电动新大巴客车 > 电池管理系统 | 0xB3000086 中通新能源 > 燃料电池客车 > 电池管理系统 | 0xB30000A8 中通新能源 > 澳巴混合动力 > 7米澳巴混合动力客车 > 电池管理系统 | 0xB30000C9 中通新能源 > 澳巴混合动力 > 9米11米澳巴混合动力客车 > 电池管理系统 | 部件: 电池管理系统";

BO_ 2565933555 ZT_BMS_18F109F3: 8 Vector__XXX
 SG_ B0 : 0|8@1+ (1,0) [0|255] "" Vector__XXX
 SG_ B1 : 8|8@1+ (1,0) [0|255] "" Vector__XXX
 SG_ B2 : 16|8@1+ (1,0) [0|255] "" Vector__XXX
 SG_ B3 : 24|8@1+ (1,0) [0|255] "" Vector__XXX
 SG_ B4 : 32|8@1+ (1,0) [0|255] "" Vector__XXX
 SG_ B5 : 40|8@1+ (1,0) [0|255] "" Vector__XXX
 SG_ B6 : 48|8@1+ (1,0) [0|255] "" Vector__XXX
 SG_ B7 : 56|8@1+ (1,0) [0|255] "" Vector__XXX

BA_ "VFrameFormat" BO_ 2565933555 1;
CM_ BO_ 2565933555 "0xB3000005 中通新能源 > 纯电动客车 > 10-12米纯电公交客车 > 电池管理系统 | 0xB3000022 中通新能源 > 纯电动客车 > 6米微巴客车 > 电池管理系统 | 0xB300003D 中通新能源 > 纯电动客车 > 8米纯电公交客车 > 电池管理系统 | 0xB300006A 中通新能源 > 纯电动客车 > 电动新大巴客车 > 电池管理系统 | 0xB3000086 中通新能源 > 燃料电池客车 > 电池管理系统 | 0xB30000A8 中通新能源 > 澳巴混合动力 > 7米澳巴混合动力客车 > 电池管理系统 | 0xB30000C9 中通新能源 > 澳巴混合动力 > 9米11米澳巴混合动力客车 > 电池管理系统 | 部件: 电池管理系统";

BO_ 2565933811 ZT_BMS_18F10AF3: 8 Vector__XXX
 SG_ B0 : 0|8@1+ (1,0) [0|255] "" Vector__XXX
 SG_ B1 : 8|8@1+ (1,0) [0|255] "" Vector__XXX
 SG_ B2 : 16|8@1+ (1,0) [0|255] "" Vector__XXX
 SG_ B3 : 24|8@1+ (1,0) [0|255] "" Vector__XXX
 SG_ B4 : 32|8@1+ (1,0) [0|255] "" Vector__XXX
 SG_ B5 : 40|8@1+ (1,0) [0|255] "" Vector__XXX
 SG_ B6 : 48|8@1+ (1,0) [0|255] "" Vector__XXX
 SG_ B7 : 56|8@1+ (1,0) [0|255] "" Vector__XXX

BA_ "VFrameFormat" BO_ 2565933811 1;
CM_ BO_ 2565933811 "0xB3000005 中通新能源 > 纯电动客车 > 10-12米纯电公交客车 > 电池管理系统 | 0xB3000022 中通新能源 > 纯电动客车 > 6米微巴客车 > 电池管理系统 | 0xB300003D 中通新能源 > 纯电动客车 > 8米纯电公交客车 > 电池管理系统 | 0xB300006A 中通新能源 > 纯电动客车 > 电动新大巴客车 > 电池管理系统 | 0xB3000086 中通新能源 > 燃料电池客车 > 电池管理系统 | 0xB30000A8 中通新能源 > 澳巴混合动力 > 7米澳巴混合动力客车 > 电池管理系统 | 0xB30000C9 中通新能源 > 澳巴混合动力 > 9米11米澳巴混合动力客车 > 电池管理系统 | 部件: 电池管理系统";

BO_ 2565934067 ZT_BMS_18F10BF3: 8 Vector__XXX
 SG_ B0 : 0|8@1+ (1,0) [0|255] "" Vector__XXX
 SG_ B1 : 8|8@1+ (1,0) [0|255] "" Vector__XXX
 SG_ B2 : 16|8@1+ (1,0) [0|255] "" Vector__XXX
 SG_ B3 : 24|8@1+ (1,0) [0|255] "" Vector__XXX
 SG_ B4 : 32|8@1+ (1,0) [0|255] "" Vector__XXX
 SG_ B5 : 40|8@1+ (1,0) [0|255] "" Vector__XXX
 SG_ B6 : 48|8@1+ (1,0) [0|255] "" Vector__XXX
 SG_ B7 : 56|8@1+ (1,0) [0|255] "" Vector__XXX

BA_ "VFrameFormat" BO_ 2565934067 1;
CM_ BO_ 2565934067 "0xB3000005 中通新能源 > 纯电动客车 > 10-12米纯电公交客车 > 电池管理系统 | 0xB3000022 中通新能源 > 纯电动客车 > 6米微巴客车 > 电池管理系统 | 0xB300003D 中通新能源 > 纯电动客车 > 8米纯电公交客车 > 电池管理系统 | 0xB300006A 中通新能源 > 纯电动客车 > 电动新大巴客车 > 电池管理系统 | 0xB3000086 中通新能源 > 燃料电池客车 > 电池管理系统 | 0xB30000A8 中通新能源 > 澳巴混合动力 > 7米澳巴混合动力客车 > 电池管理系统 | 0xB30000C9 中通新能源 > 澳巴混合动力 > 9米11米澳巴混合动力客车 > 电池管理系统 | 部件: 电池管理系统";

BO_ 2565934323 ZT_BMS_18F10CF3: 8 Vector__XXX
 SG_ B0 : 0|8@1+ (1,0) [0|255] "" Vector__XXX
 SG_ B1 : 8|8@1+ (1,0) [0|255] "" Vector__XXX
 SG_ B2 : 16|8@1+ (1,0) [0|255] "" Vector__XXX
 SG_ B3 : 24|8@1+ (1,0) [0|255] "" Vector__XXX
 SG_ B4 : 32|8@1+ (1,0) [0|255] "" Vector__XXX
 SG_ B5 : 40|8@1+ (1,0) [0|255] "" Vector__XXX
 SG_ B6 : 48|8@1+ (1,0) [0|255] "" Vector__XXX
 SG_ B7 : 56|8@1+ (1,0) [0|255] "" Vector__XXX

BA_ "VFrameFormat" BO_ 2565934323 1;
CM_ BO_ 2565934323 "0xB3000005 中通新能源 > 纯电动客车 > 10-12米纯电公交客车 > 电池管理系统 | 0xB3000022 中通新能源 > 纯电动客车 > 6米微巴客车 > 电池管理系统 | 0xB300003D 中通新能源 > 纯电动客车 > 8米纯电公交客车 > 电池管理系统 | 0xB300006A 中通新能源 > 纯电动客车 > 电动新大巴客车 > 电池管理系统 | 0xB3000086 中通新能源 > 燃料电池客车 > 电池管理系统 | 0xB30000A8 中通新能源 > 澳巴混合动力 > 7米澳巴混合动力客车 > 电池管理系统 | 0xB30000C9 中通新能源 > 澳巴混合动力 > 9米11米澳巴混合动力客车 > 电池管理系统 | 部件: 电池管理系统";

BO_ 2565934579 ZT_BMS_18F10DF3: 8 Vector__XXX
 SG_ B0 : 0|8@1+ (1,0) [0|255] "" Vector__XXX
 SG_ B1 : 8|8@1+ (1,0) [0|255] "" Vector__XXX
 SG_ B2 : 16|8@1+ (1,0) [0|255] "" Vector__XXX
 SG_ B3 : 24|8@1+ (1,0) [0|255] "" Vector__XXX
 SG_ B4 : 32|8@1+ (1,0) [0|255] "" Vector__XXX
 SG_ B5 : 40|8@1+ (1,0) [0|255] "" Vector__XXX
 SG_ B6 : 48|8@1+ (1,0) [0|255] "" Vector__XXX
 SG_ B7 : 56|8@1+ (1,0) [0|255] "" Vector__XXX

BA_ "VFrameFormat" BO_ 2565934579 1;
CM_ BO_ 2565934579 "0xB3000005 中通新能源 > 纯电动客车 > 10-12米纯电公交客车 > 电池管理系统 | 0xB3000022 中通新能源 > 纯电动客车 > 6米微巴客车 > 电池管理系统 | 0xB300003D 中通新能源 > 纯电动客车 > 8米纯电公交客车 > 电池管理系统 | 0xB300006A 中通新能源 > 纯电动客车 > 电动新大巴客车 > 电池管理系统 | 0xB3000086 中通新能源 > 燃料电池客车 > 电池管理系统 | 0xB30000A8 中通新能源 > 澳巴混合动力 > 7米澳巴混合动力客车 > 电池管理系统 | 0xB30000C9 中通新能源 > 澳巴混合动力 > 9米11米澳巴混合动力客车 > 电池管理系统 | 部件: 电池管理系统";

BO_ 2565934835 ZT_BMS_18F10EF3: 8 Vector__XXX
 SG_ B0 : 0|8@1+ (1,0) [0|255] "" Vector__XXX
 SG_ B1 : 8|8@1+ (1,0) [0|255] "" Vector__XXX
 SG_ B2 : 16|8@1+ (1,0) [0|255] "" Vector__XXX
 SG_ B3 : 24|8@1+ (1,0) [0|255] "" Vector__XXX
 SG_ B4 : 32|8@1+ (1,0) [0|255] "" Vector__XXX
 SG_ B5 : 40|8@1+ (1,0) [0|255] "" Vector__XXX
 SG_ B6 : 48|8@1+ (1,0) [0|255] "" Vector__XXX
 SG_ B7 : 56|8@1+ (1,0) [0|255] "" Vector__XXX

BA_ "VFrameFormat" BO_ 2565934835 1;
CM_ BO_ 2565934835 "0xB3000005 中通新能源 > 纯电动客车 > 10-12米纯电公交客车 > 电池管理系统 | 0xB3000022 中通新能源 > 纯电动客车 > 6米微巴客车 > 电池管理系统 | 0xB300003D 中通新能源 > 纯电动客车 > 8米纯电公交客车 > 电池管理系统 | 0xB300006A 中通新能源 > 纯电动客车 > 电动新大巴客车 > 电池管理系统 | 0xB3000086 中通新能源 > 燃料电池客车 > 电池管理系统 | 0xB30000A8 中通新能源 > 澳巴混合动力 > 7米澳巴混合动力客车 > 电池管理系统 | 0xB30000C9 中通新能源 > 澳巴混合动力 > 9米11米澳巴混合动力客车 > 电池管理系统 | 部件: 电池管理系统";

BO_ 2565935091 ZT_BMS_18F10FF3: 8 Vector__XXX
 SG_ B0 : 0|8@1+ (1,0) [0|255] "" Vector__XXX
 SG_ B1 : 8|8@1+ (1,0) [0|255] "" Vector__XXX
 SG_ B2 : 16|8@1+ (1,0) [0|255] "" Vector__XXX
 SG_ B3 : 24|8@1+ (1,0) [0|255] "" Vector__XXX
 SG_ B4 : 32|8@1+ (1,0) [0|255] "" Vector__XXX
 SG_ B5 : 40|8@1+ (1,0) [0|255] "" Vector__XXX
 SG_ B6 : 48|8@1+ (1,0) [0|255] "" Vector__XXX
 SG_ B7 : 56|8@1+ (1,0) [0|255] "" Vector__XXX

BA_ "VFrameFormat" BO_ 2565935091 1;
CM_ BO_ 2565935091 "0xB3000005 中通新能源 > 纯电动客车 > 10-12米纯电公交客车 > 电池管理系统 | 0xB3000022 中通新能源 > 纯电动客车 > 6米微巴客车 > 电池管理系统 | 0xB300003D 中通新能源 > 纯电动客车 > 8米纯电公交客车 > 电池管理系统 | 0xB300006A 中通新能源 > 纯电动客车 > 电动新大巴客车 > 电池管理系统 | 0xB3000086 中通新能源 > 燃料电池客车 > 电池管理系统 | 0xB30000A8 中通新能源 > 澳巴混合动力 > 7米澳巴混合动力客车 > 电池管理系统 | 0xB30000C9 中通新能源 > 澳巴混合动力 > 9米11米澳巴混合动力客车 > 电池管理系统 | 部件: 电池管理系统";

BO_ 2565935347 ZT_BMS_18F110F3: 8 Vector__XXX
 SG_ B0 : 0|8@1+ (1,0) [0|255] "" Vector__XXX
 SG_ B1 : 8|8@1+ (1,0) [0|255] "" Vector__XXX
 SG_ B2 : 16|8@1+ (1,0) [0|255] "" Vector__XXX
 SG_ B3 : 24|8@1+ (1,0) [0|255] "" Vector__XXX
 SG_ B4 : 32|8@1+ (1,0) [0|255] "" Vector__XXX
 SG_ B5 : 40|8@1+ (1,0) [0|255] "" Vector__XXX
 SG_ B6 : 48|8@1+ (1,0) [0|255] "" Vector__XXX
 SG_ B7 : 56|8@1+ (1,0) [0|255] "" Vector__XXX

BA_ "VFrameFormat" BO_ 2565935347 1;
CM_ BO_ 2565935347 "0xB3000005 中通新能源 > 纯电动客车 > 10-12米纯电公交客车 > 电池管理系统 | 0xB3000022 中通新能源 > 纯电动客车 > 6米微巴客车 > 电池管理系统 | 0xB300003D 中通新能源 > 纯电动客车 > 8米纯电公交客车 > 电池管理系统 | 0xB300006A 中通新能源 > 纯电动客车 > 电动新大巴客车 > 电池管理系统 | 0xB3000086 中通新能源 > 燃料电池客车 > 电池管理系统 | 0xB30000A8 中通新能源 > 澳巴混合动力 > 7米澳巴混合动力客车 > 电池管理系统 | 0xB30000C9 中通新能源 > 澳巴混合动力 > 9米11米澳巴混合动力客车 > 电池管理系统 | 部件: 电池管理系统";

BO_ 2565935603 ZT_BMS_18F111F3: 8 Vector__XXX
 SG_ B0 : 0|8@1+ (1,0) [0|255] "" Vector__XXX
 SG_ B1 : 8|8@1+ (1,0) [0|255] "" Vector__XXX
 SG_ B2 : 16|8@1+ (1,0) [0|255] "" Vector__XXX
 SG_ B3 : 24|8@1+ (1,0) [0|255] "" Vector__XXX
 SG_ B4 : 32|8@1+ (1,0) [0|255] "" Vector__XXX
 SG_ B5 : 40|8@1+ (1,0) [0|255] "" Vector__XXX
 SG_ B6 : 48|8@1+ (1,0) [0|255] "" Vector__XXX
 SG_ B7 : 56|8@1+ (1,0) [0|255] "" Vector__XXX

BA_ "VFrameFormat" BO_ 2565935603 1;
CM_ BO_ 2565935603 "0xB3000005 中通新能源 > 纯电动客车 > 10-12米纯电公交客车 > 电池管理系统 | 0xB3000022 中通新能源 > 纯电动客车 > 6米微巴客车 > 电池管理系统 | 0xB300003D 中通新能源 > 纯电动客车 > 8米纯电公交客车 > 电池管理系统 | 0xB300006A 中通新能源 > 纯电动客车 > 电动新大巴客车 > 电池管理系统 | 0xB3000086 中通新能源 > 燃料电池客车 > 电池管理系统 | 0xB30000A8 中通新能源 > 澳巴混合动力 > 7米澳巴混合动力客车 > 电池管理系统 | 0xB30000C9 中通新能源 > 澳巴混合动力 > 9米11米澳巴混合动力客车 > 电池管理系统 | 部件: 电池管理系统";

BO_ 2565935859 ZT_BMS_18F112F3: 8 Vector__XXX
 SG_ B0 : 0|8@1+ (1,0) [0|255] "" Vector__XXX
 SG_ B1 : 8|8@1+ (1,0) [0|255] "" Vector__XXX
 SG_ B2 : 16|8@1+ (1,0) [0|255] "" Vector__XXX
 SG_ B3 : 24|8@1+ (1,0) [0|255] "" Vector__XXX
 SG_ B4 : 32|8@1+ (1,0) [0|255] "" Vector__XXX
 SG_ B5 : 40|8@1+ (1,0) [0|255] "" Vector__XXX
 SG_ B6 : 48|8@1+ (1,0) [0|255] "" Vector__XXX
 SG_ B7 : 56|8@1+ (1,0) [0|255] "" Vector__XXX

BA_ "VFrameFormat" BO_ 2565935859 1;
CM_ BO_ 2565935859 "0xB3000005 中通新能源 > 纯电动客车 > 10-12米纯电公交客车 > 电池管理系统 | 0xB3000022 中通新能源 > 纯电动客车 > 6米微巴客车 > 电池管理系统 | 0xB300003D 中通新能源 > 纯电动客车 > 8米纯电公交客车 > 电池管理系统 | 0xB300006A 中通新能源 > 纯电动客车 > 电动新大巴客车 > 电池管理系统 | 0xB3000086 中通新能源 > 燃料电池客车 > 电池管理系统 | 0xB30000A8 中通新能源 > 澳巴混合动力 > 7米澳巴混合动力客车 > 电池管理系统 | 0xB30000C9 中通新能源 > 澳巴混合动力 > 9米11米澳巴混合动力客车 > 电池管理系统 | 部件: 电池管理系统";

BO_ 2565936115 ZT_BMS_18F113F3: 8 Vector__XXX
 SG_ B0 : 0|8@1+ (1,0) [0|255] "" Vector__XXX
 SG_ B1 : 8|8@1+ (1,0) [0|255] "" Vector__XXX
 SG_ B2 : 16|8@1+ (1,0) [0|255] "" Vector__XXX
 SG_ B3 : 24|8@1+ (1,0) [0|255] "" Vector__XXX
 SG_ B4 : 32|8@1+ (1,0) [0|255] "" Vector__XXX
 SG_ B5 : 40|8@1+ (1,0) [0|255] "" Vector__XXX
 SG_ B6 : 48|8@1+ (1,0) [0|255] "" Vector__XXX
 SG_ B7 : 56|8@1+ (1,0) [0|255] "" Vector__XXX

BA_ "VFrameFormat" BO_ 2565936115 1;
CM_ BO_ 2565936115 "0xB3000005 中通新能源 > 纯电动客车 > 10-12米纯电公交客车 > 电池管理系统 | 0xB3000022 中通新能源 > 纯电动客车 > 6米微巴客车 > 电池管理系统 | 0xB300003D 中通新能源 > 纯电动客车 > 8米纯电公交客车 > 电池管理系统 | 0xB300006A 中通新能源 > 纯电动客车 > 电动新大巴客车 > 电池管理系统 | 0xB3000086 中通新能源 > 燃料电池客车 > 电池管理系统 | 0xB30000A8 中通新能源 > 澳巴混合动力 > 7米澳巴混合动力客车 > 电池管理系统 | 0xB30000C9 中通新能源 > 澳巴混合动力 > 9米11米澳巴混合动力客车 > 电池管理系统 | 部件: 电池管理系统";

BO_ 2565936371 ZT_BMS_18F114F3: 8 Vector__XXX
 SG_ B0 : 0|8@1+ (1,0) [0|255] "" Vector__XXX
 SG_ B1 : 8|8@1+ (1,0) [0|255] "" Vector__XXX
 SG_ B2 : 16|8@1+ (1,0) [0|255] "" Vector__XXX
 SG_ B3 : 24|8@1+ (1,0) [0|255] "" Vector__XXX
 SG_ B4 : 32|8@1+ (1,0) [0|255] "" Vector__XXX
 SG_ B5 : 40|8@1+ (1,0) [0|255] "" Vector__XXX
 SG_ B6 : 48|8@1+ (1,0) [0|255] "" Vector__XXX
 SG_ B7 : 56|8@1+ (1,0) [0|255] "" Vector__XXX

BA_ "VFrameFormat" BO_ 2565936371 1;
CM_ BO_ 2565936371 "0xB3000005 中通新能源 > 纯电动客车 > 10-12米纯电公交客车 > 电池管理系统 | 0xB3000022 中通新能源 > 纯电动客车 > 6米微巴客车 > 电池管理系统 | 0xB300003D 中通新能源 > 纯电动客车 > 8米纯电公交客车 > 电池管理系统 | 0xB300006A 中通新能源 > 纯电动客车 > 电动新大巴客车 > 电池管理系统 | 0xB3000086 中通新能源 > 燃料电池客车 > 电池管理系统 | 0xB30000A8 中通新能源 > 澳巴混合动力 > 7米澳巴混合动力客车 > 电池管理系统 | 0xB30000C9 中通新能源 > 澳巴混合动力 > 9米11米澳巴混合动力客车 > 电池管理系统 | 部件: 电池管理系统";

BO_ 2565936627 ZT_BMS_18F115F3: 8 Vector__XXX
 SG_ B0 : 0|8@1+ (1,0) [0|255] "" Vector__XXX
 SG_ B1 : 8|8@1+ (1,0) [0|255] "" Vector__XXX
 SG_ B2 : 16|8@1+ (1,0) [0|255] "" Vector__XXX
 SG_ B3 : 24|8@1+ (1,0) [0|255] "" Vector__XXX
 SG_ B4 : 32|8@1+ (1,0) [0|255] "" Vector__XXX
 SG_ B5 : 40|8@1+ (1,0) [0|255] "" Vector__XXX
 SG_ B6 : 48|8@1+ (1,0) [0|255] "" Vector__XXX
 SG_ B7 : 56|8@1+ (1,0) [0|255] "" Vector__XXX

BA_ "VFrameFormat" BO_ 2565936627 1;
CM_ BO_ 2565936627 "0xB3000005 中通新能源 > 纯电动客车 > 10-12米纯电公交客车 > 电池管理系统 | 0xB3000022 中通新能源 > 纯电动客车 > 6米微巴客车 > 电池管理系统 | 0xB300003D 中通新能源 > 纯电动客车 > 8米纯电公交客车 > 电池管理系统 | 0xB300006A 中通新能源 > 纯电动客车 > 电动新大巴客车 > 电池管理系统 | 0xB3000086 中通新能源 > 燃料电池客车 > 电池管理系统 | 0xB30000A8 中通新能源 > 澳巴混合动力 > 7米澳巴混合动力客车 > 电池管理系统 | 0xB30000C9 中通新能源 > 澳巴混合动力 > 9米11米澳巴混合动力客车 > 电池管理系统 | 部件: 电池管理系统";

BO_ 2565936883 ZT_BMS_18F116F3: 8 Vector__XXX
 SG_ B0 : 0|8@1+ (1,0) [0|255] "" Vector__XXX
 SG_ B1 : 8|8@1+ (1,0) [0|255] "" Vector__XXX
 SG_ B2 : 16|8@1+ (1,0) [0|255] "" Vector__XXX
 SG_ B3 : 24|8@1+ (1,0) [0|255] "" Vector__XXX
 SG_ B4 : 32|8@1+ (1,0) [0|255] "" Vector__XXX
 SG_ B5 : 40|8@1+ (1,0) [0|255] "" Vector__XXX
 SG_ B6 : 48|8@1+ (1,0) [0|255] "" Vector__XXX
 SG_ B7 : 56|8@1+ (1,0) [0|255] "" Vector__XXX

BA_ "VFrameFormat" BO_ 2565936883 1;
CM_ BO_ 2565936883 "0xB3000005 中通新能源 > 纯电动客车 > 10-12米纯电公交客车 > 电池管理系统 | 0xB3000022 中通新能源 > 纯电动客车 > 6米微巴客车 > 电池管理系统 | 0xB300003D 中通新能源 > 纯电动客车 > 8米纯电公交客车 > 电池管理系统 | 0xB300006A 中通新能源 > 纯电动客车 > 电动新大巴客车 > 电池管理系统 | 0xB3000086 中通新能源 > 燃料电池客车 > 电池管理系统 | 0xB30000A8 中通新能源 > 澳巴混合动力 > 7米澳巴混合动力客车 > 电池管理系统 | 0xB30000C9 中通新能源 > 澳巴混合动力 > 9米11米澳巴混合动力客车 > 电池管理系统 | 部件: 电池管理系统";

BO_ 2565937139 ZT_BMS_18F117F3: 8 Vector__XXX
 SG_ B0 : 0|8@1+ (1,0) [0|255] "" Vector__XXX
 SG_ B1 : 8|8@1+ (1,0) [0|255] "" Vector__XXX
 SG_ B2 : 16|8@1+ (1,0) [0|255] "" Vector__XXX
 SG_ B3 : 24|8@1+ (1,0) [0|255] "" Vector__XXX
 SG_ B4 : 32|8@1+ (1,0) [0|255] "" Vector__XXX
 SG_ B5 : 40|8@1+ (1,0) [0|255] "" Vector__XXX
 SG_ B6 : 48|8@1+ (1,0) [0|255] "" Vector__XXX
 SG_ B7 : 56|8@1+ (1,0) [0|255] "" Vector__XXX

BA_ "VFrameFormat" BO_ 2565937139 1;
CM_ BO_ 2565937139 "0xB3000005 中通新能源 > 纯电动客车 > 10-12米纯电公交客车 > 电池管理系统 | 0xB3000022 中通新能源 > 纯电动客车 > 6米微巴客车 > 电池管理系统 | 0xB300003D 中通新能源 > 纯电动客车 > 8米纯电公交客车 > 电池管理系统 | 0xB300006A 中通新能源 > 纯电动客车 > 电动新大巴客车 > 电池管理系统 | 0xB3000086 中通新能源 > 燃料电池客车 > 电池管理系统 | 0xB30000A8 中通新能源 > 澳巴混合动力 > 7米澳巴混合动力客车 > 电池管理系统 | 0xB30000C9 中通新能源 > 澳巴混合动力 > 9米11米澳巴混合动力客车 > 电池管理系统 | 部件: 电池管理系统";

BO_ 2565937395 ZT_BMS_18F118F3: 8 Vector__XXX
 SG_ B0 : 0|8@1+ (1,0) [0|255] "" Vector__XXX
 SG_ B1 : 8|8@1+ (1,0) [0|255] "" Vector__XXX
 SG_ B2 : 16|8@1+ (1,0) [0|255] "" Vector__XXX
 SG_ B3 : 24|8@1+ (1,0) [0|255] "" Vector__XXX
 SG_ B4 : 32|8@1+ (1,0) [0|255] "" Vector__XXX
 SG_ B5 : 40|8@1+ (1,0) [0|255] "" Vector__XXX
 SG_ B6 : 48|8@1+ (1,0) [0|255] "" Vector__XXX
 SG_ B7 : 56|8@1+ (1,0) [0|255] "" Vector__XXX

BA_ "VFrameFormat" BO_ 2565937395 1;
CM_ BO_ 2565937395 "0xB3000005 中通新能源 > 纯电动客车 > 10-12米纯电公交客车 > 电池管理系统 | 0xB3000022 中通新能源 > 纯电动客车 > 6米微巴客车 > 电池管理系统 | 0xB300003D 中通新能源 > 纯电动客车 > 8米纯电公交客车 > 电池管理系统 | 0xB300006A 中通新能源 > 纯电动客车 > 电动新大巴客车 > 电池管理系统 | 0xB3000086 中通新能源 > 燃料电池客车 > 电池管理系统 | 0xB30000A8 中通新能源 > 澳巴混合动力 > 7米澳巴混合动力客车 > 电池管理系统 | 0xB30000C9 中通新能源 > 澳巴混合动力 > 9米11米澳巴混合动力客车 > 电池管理系统 | 部件: 电池管理系统";

BO_ 2565937651 ZT_BMS_18F119F3: 8 Vector__XXX
 SG_ B0 : 0|8@1+ (1,0) [0|255] "" Vector__XXX
 SG_ B1 : 8|8@1+ (1,0) [0|255] "" Vector__XXX
 SG_ B2 : 16|8@1+ (1,0) [0|255] "" Vector__XXX
 SG_ B3 : 24|8@1+ (1,0) [0|255] "" Vector__XXX
 SG_ B4 : 32|8@1+ (1,0) [0|255] "" Vector__XXX
 SG_ B5 : 40|8@1+ (1,0) [0|255] "" Vector__XXX
 SG_ B6 : 48|8@1+ (1,0) [0|255] "" Vector__XXX
 SG_ B7 : 56|8@1+ (1,0) [0|255] "" Vector__XXX

BA_ "VFrameFormat" BO_ 2565937651 1;
CM_ BO_ 2565937651 "0xB3000005 中通新能源 > 纯电动客车 > 10-12米纯电公交客车 > 电池管理系统 | 0xB3000022 中通新能源 > 纯电动客车 > 6米微巴客车 > 电池管理系统 | 0xB300003D 中通新能源 > 纯电动客车 > 8米纯电公交客车 > 电池管理系统 | 0xB300006A 中通新能源 > 纯电动客车 > 电动新大巴客车 > 电池管理系统 | 0xB3000086 中通新能源 > 燃料电池客车 > 电池管理系统 | 0xB30000A8 中通新能源 > 澳巴混合动力 > 7米澳巴混合动力客车 > 电池管理系统 | 0xB30000C9 中通新能源 > 澳巴混合动力 > 9米11米澳巴混合动力客车 > 电池管理系统 | 部件: 电池管理系统";

BO_ 2565937907 ZT_BMS_18F11AF3: 8 Vector__XXX
 SG_ B0 : 0|8@1+ (1,0) [0|255] "" Vector__XXX
 SG_ B1 : 8|8@1+ (1,0) [0|255] "" Vector__XXX
 SG_ B2 : 16|8@1+ (1,0) [0|255] "" Vector__XXX
 SG_ B3 : 24|8@1+ (1,0) [0|255] "" Vector__XXX
 SG_ B4 : 32|8@1+ (1,0) [0|255] "" Vector__XXX
 SG_ B5 : 40|8@1+ (1,0) [0|255] "" Vector__XXX
 SG_ B6 : 48|8@1+ (1,0) [0|255] "" Vector__XXX
 SG_ B7 : 56|8@1+ (1,0) [0|255] "" Vector__XXX

BA_ "VFrameFormat" BO_ 2565937907 1;
CM_ BO_ 2565937907 "0xB3000005 中通新能源 > 纯电动客车 > 10-12米纯电公交客车 > 电池管理系统 | 0xB3000022 中通新能源 > 纯电动客车 > 6米微巴客车 > 电池管理系统 | 0xB300003D 中通新能源 > 纯电动客车 > 8米纯电公交客车 > 电池管理系统 | 0xB300006A 中通新能源 > 纯电动客车 > 电动新大巴客车 > 电池管理系统 | 0xB3000086 中通新能源 > 燃料电池客车 > 电池管理系统 | 0xB30000A8 中通新能源 > 澳巴混合动力 > 7米澳巴混合动力客车 > 电池管理系统 | 0xB30000C9 中通新能源 > 澳巴混合动力 > 9米11米澳巴混合动力客车 > 电池管理系统 | 部件: 电池管理系统";

BO_ 2565938163 ZT_BMS_18F11BF3: 8 Vector__XXX
 SG_ B0 : 0|8@1+ (1,0) [0|255] "" Vector__XXX
 SG_ B1 : 8|8@1+ (1,0) [0|255] "" Vector__XXX
 SG_ B2 : 16|8@1+ (1,0) [0|255] "" Vector__XXX
 SG_ B3 : 24|8@1+ (1,0) [0|255] "" Vector__XXX
 SG_ B4 : 32|8@1+ (1,0) [0|255] "" Vector__XXX
 SG_ B5 : 40|8@1+ (1,0) [0|255] "" Vector__XXX
 SG_ B6 : 48|8@1+ (1,0) [0|255] "" Vector__XXX
 SG_ B7 : 56|8@1+ (1,0) [0|255] "" Vector__XXX

BA_ "VFrameFormat" BO_ 2565938163 1;
CM_ BO_ 2565938163 "0xB3000005 中通新能源 > 纯电动客车 > 10-12米纯电公交客车 > 电池管理系统 | 0xB3000022 中通新能源 > 纯电动客车 > 6米微巴客车 > 电池管理系统 | 0xB300003D 中通新能源 > 纯电动客车 > 8米纯电公交客车 > 电池管理系统 | 0xB300006A 中通新能源 > 纯电动客车 > 电动新大巴客车 > 电池管理系统 | 0xB3000086 中通新能源 > 燃料电池客车 > 电池管理系统 | 0xB30000A8 中通新能源 > 澳巴混合动力 > 7米澳巴混合动力客车 > 电池管理系统 | 0xB30000C9 中通新能源 > 澳巴混合动力 > 9米11米澳巴混合动力客车 > 电池管理系统 | 部件: 电池管理系统";

BO_ 2565938419 ZT_BMS_18F11CF3: 8 Vector__XXX
 SG_ B0 : 0|8@1+ (1,0) [0|255] "" Vector__XXX
 SG_ B1 : 8|8@1+ (1,0) [0|255] "" Vector__XXX
 SG_ B2 : 16|8@1+ (1,0) [0|255] "" Vector__XXX
 SG_ B3 : 24|8@1+ (1,0) [0|255] "" Vector__XXX
 SG_ B4 : 32|8@1+ (1,0) [0|255] "" Vector__XXX
 SG_ B5 : 40|8@1+ (1,0) [0|255] "" Vector__XXX
 SG_ B6 : 48|8@1+ (1,0) [0|255] "" Vector__XXX
 SG_ B7 : 56|8@1+ (1,0) [0|255] "" Vector__XXX

BA_ "VFrameFormat" BO_ 2565938419 1;
CM_ BO_ 2565938419 "0xB3000005 中通新能源 > 纯电动客车 > 10-12米纯电公交客车 > 电池管理系统 | 0xB3000022 中通新能源 > 纯电动客车 > 6米微巴客车 > 电池管理系统 | 0xB300003D 中通新能源 > 纯电动客车 > 8米纯电公交客车 > 电池管理系统 | 0xB300006A 中通新能源 > 纯电动客车 > 电动新大巴客车 > 电池管理系统 | 0xB3000086 中通新能源 > 燃料电池客车 > 电池管理系统 | 0xB30000A8 中通新能源 > 澳巴混合动力 > 7米澳巴混合动力客车 > 电池管理系统 | 0xB30000C9 中通新能源 > 澳巴混合动力 > 9米11米澳巴混合动力客车 > 电池管理系统 | 部件: 电池管理系统";

BO_ 2565938675 ZT_BMS_18F11DF3: 8 Vector__XXX
 SG_ B0 : 0|8@1+ (1,0) [0|255] "" Vector__XXX
 SG_ B1 : 8|8@1+ (1,0) [0|255] "" Vector__XXX
 SG_ B2 : 16|8@1+ (1,0) [0|255] "" Vector__XXX
 SG_ B3 : 24|8@1+ (1,0) [0|255] "" Vector__XXX
 SG_ B4 : 32|8@1+ (1,0) [0|255] "" Vector__XXX
 SG_ B5 : 40|8@1+ (1,0) [0|255] "" Vector__XXX
 SG_ B6 : 48|8@1+ (1,0) [0|255] "" Vector__XXX
 SG_ B7 : 56|8@1+ (1,0) [0|255] "" Vector__XXX

BA_ "VFrameFormat" BO_ 2565938675 1;
CM_ BO_ 2565938675 "0xB3000005 中通新能源 > 纯电动客车 > 10-12米纯电公交客车 > 电池管理系统 | 0xB3000022 中通新能源 > 纯电动客车 > 6米微巴客车 > 电池管理系统 | 0xB300003D 中通新能源 > 纯电动客车 > 8米纯电公交客车 > 电池管理系统 | 0xB300006A 中通新能源 > 纯电动客车 > 电动新大巴客车 > 电池管理系统 | 0xB3000086 中通新能源 > 燃料电池客车 > 电池管理系统 | 0xB30000A8 中通新能源 > 澳巴混合动力 > 7米澳巴混合动力客车 > 电池管理系统 | 0xB30000C9 中通新能源 > 澳巴混合动力 > 9米11米澳巴混合动力客车 > 电池管理系统 | 部件: 电池管理系统";

BO_ 2565938931 ZT_BMS_18F11EF3: 8 Vector__XXX
 SG_ B0 : 0|8@1+ (1,0) [0|255] "" Vector__XXX
 SG_ B1 : 8|8@1+ (1,0) [0|255] "" Vector__XXX
 SG_ B2 : 16|8@1+ (1,0) [0|255] "" Vector__XXX
 SG_ B3 : 24|8@1+ (1,0) [0|255] "" Vector__XXX
 SG_ B4 : 32|8@1+ (1,0) [0|255] "" Vector__XXX
 SG_ B5 : 40|8@1+ (1,0) [0|255] "" Vector__XXX
 SG_ B6 : 48|8@1+ (1,0) [0|255] "" Vector__XXX
 SG_ B7 : 56|8@1+ (1,0) [0|255] "" Vector__XXX

BA_ "VFrameFormat" BO_ 2565938931 1;
CM_ BO_ 2565938931 "0xB3000005 中通新能源 > 纯电动客车 > 10-12米纯电公交客车 > 电池管理系统 | 0xB3000022 中通新能源 > 纯电动客车 > 6米微巴客车 > 电池管理系统 | 0xB300003D 中通新能源 > 纯电动客车 > 8米纯电公交客车 > 电池管理系统 | 0xB300006A 中通新能源 > 纯电动客车 > 电动新大巴客车 > 电池管理系统 | 0xB3000086 中通新能源 > 燃料电池客车 > 电池管理系统 | 0xB30000A8 中通新能源 > 澳巴混合动力 > 7米澳巴混合动力客车 > 电池管理系统 | 0xB30000C9 中通新能源 > 澳巴混合动力 > 9米11米澳巴混合动力客车 > 电池管理系统 | 部件: 电池管理系统";

BO_ 2565939187 ZT_BMS_18F11FF3: 8 Vector__XXX
 SG_ B0 : 0|8@1+ (1,0) [0|255] "" Vector__XXX
 SG_ B1 : 8|8@1+ (1,0) [0|255] "" Vector__XXX
 SG_ B2 : 16|8@1+ (1,0) [0|255] "" Vector__XXX
 SG_ B3 : 24|8@1+ (1,0) [0|255] "" Vector__XXX
 SG_ B4 : 32|8@1+ (1,0) [0|255] "" Vector__XXX
 SG_ B5 : 40|8@1+ (1,0) [0|255] "" Vector__XXX
 SG_ B6 : 48|8@1+ (1,0) [0|255] "" Vector__XXX
 SG_ B7 : 56|8@1+ (1,0) [0|255] "" Vector__XXX

BA_ "VFrameFormat" BO_ 2565939187 1;
CM_ BO_ 2565939187 "0xB3000005 中通新能源 > 纯电动客车 > 10-12米纯电公交客车 > 电池管理系统 | 0xB3000022 中通新能源 > 纯电动客车 > 6米微巴客车 > 电池管理系统 | 0xB300003D 中通新能源 > 纯电动客车 > 8米纯电公交客车 > 电池管理系统 | 0xB300006A 中通新能源 > 纯电动客车 > 电动新大巴客车 > 电池管理系统 | 0xB3000086 中通新能源 > 燃料电池客车 > 电池管理系统 | 0xB30000A8 中通新能源 > 澳巴混合动力 > 7米澳巴混合动力客车 > 电池管理系统 | 0xB30000C9 中通新能源 > 澳巴混合动力 > 9米11米澳巴混合动力客车 > 电池管理系统 | 部件: 电池管理系统";

BO_ 2565939443 ZT_BMS_18F120F3: 8 Vector__XXX
 SG_ B0 : 0|8@1+ (1,0) [0|255] "" Vector__XXX
 SG_ B1 : 8|8@1+ (1,0) [0|255] "" Vector__XXX
 SG_ B2 : 16|8@1+ (1,0) [0|255] "" Vector__XXX
 SG_ B3 : 24|8@1+ (1,0) [0|255] "" Vector__XXX
 SG_ B4 : 32|8@1+ (1,0) [0|255] "" Vector__XXX
 SG_ B5 : 40|8@1+ (1,0) [0|255] "" Vector__XXX
 SG_ B6 : 48|8@1+ (1,0) [0|255] "" Vector__XXX
 SG_ B7 : 56|8@1+ (1,0) [0|255] "" Vector__XXX

BA_ "VFrameFormat" BO_ 2565939443 1;
CM_ BO_ 2565939443 "0xB3000005 中通新能源 > 纯电动客车 > 10-12米纯电公交客车 > 电池管理系统 | 0xB3000022 中通新能源 > 纯电动客车 > 6米微巴客车 > 电池管理系统 | 0xB300003D 中通新能源 > 纯电动客车 > 8米纯电公交客车 > 电池管理系统 | 0xB300006A 中通新能源 > 纯电动客车 > 电动新大巴客车 > 电池管理系统 | 0xB3000086 中通新能源 > 燃料电池客车 > 电池管理系统 | 0xB30000A8 中通新能源 > 澳巴混合动力 > 7米澳巴混合动力客车 > 电池管理系统 | 0xB30000C9 中通新能源 > 澳巴混合动力 > 9米11米澳巴混合动力客车 > 电池管理系统 | 部件: 电池管理系统";

BO_ 2565939699 ZT_BMS_18F121F3: 8 Vector__XXX
 SG_ B0 : 0|8@1+ (1,0) [0|255] "" Vector__XXX
 SG_ B1 : 8|8@1+ (1,0) [0|255] "" Vector__XXX
 SG_ B2 : 16|8@1+ (1,0) [0|255] "" Vector__XXX
 SG_ B3 : 24|8@1+ (1,0) [0|255] "" Vector__XXX
 SG_ B4 : 32|8@1+ (1,0) [0|255] "" Vector__XXX
 SG_ B5 : 40|8@1+ (1,0) [0|255] "" Vector__XXX
 SG_ B6 : 48|8@1+ (1,0) [0|255] "" Vector__XXX
 SG_ B7 : 56|8@1+ (1,0) [0|255] "" Vector__XXX

BA_ "VFrameFormat" BO_ 2565939699 1;
CM_ BO_ 2565939699 "0xB3000005 中通新能源 > 纯电动客车 > 10-12米纯电公交客车 > 电池管理系统 | 0xB3000022 中通新能源 > 纯电动客车 > 6米微巴客车 > 电池管理系统 | 0xB300003D 中通新能源 > 纯电动客车 > 8米纯电公交客车 > 电池管理系统 | 0xB300006A 中通新能源 > 纯电动客车 > 电动新大巴客车 > 电池管理系统 | 0xB3000086 中通新能源 > 燃料电池客车 > 电池管理系统 | 0xB30000A8 中通新能源 > 澳巴混合动力 > 7米澳巴混合动力客车 > 电池管理系统 | 0xB30000C9 中通新能源 > 澳巴混合动力 > 9米11米澳巴混合动力客车 > 电池管理系统 | 部件: 电池管理系统";

BO_ 2565939955 ZT_BMS_18F122F3: 8 Vector__XXX
 SG_ B0 : 0|8@1+ (1,0) [0|255] "" Vector__XXX
 SG_ B1 : 8|8@1+ (1,0) [0|255] "" Vector__XXX
 SG_ B2 : 16|8@1+ (1,0) [0|255] "" Vector__XXX
 SG_ B3 : 24|8@1+ (1,0) [0|255] "" Vector__XXX
 SG_ B4 : 32|8@1+ (1,0) [0|255] "" Vector__XXX
 SG_ B5 : 40|8@1+ (1,0) [0|255] "" Vector__XXX
 SG_ B6 : 48|8@1+ (1,0) [0|255] "" Vector__XXX
 SG_ B7 : 56|8@1+ (1,0) [0|255] "" Vector__XXX

BA_ "VFrameFormat" BO_ 2565939955 1;
CM_ BO_ 2565939955 "0xB3000005 中通新能源 > 纯电动客车 > 10-12米纯电公交客车 > 电池管理系统 | 0xB3000022 中通新能源 > 纯电动客车 > 6米微巴客车 > 电池管理系统 | 0xB300003D 中通新能源 > 纯电动客车 > 8米纯电公交客车 > 电池管理系统 | 0xB300006A 中通新能源 > 纯电动客车 > 电动新大巴客车 > 电池管理系统 | 0xB3000086 中通新能源 > 燃料电池客车 > 电池管理系统 | 0xB30000A8 中通新能源 > 澳巴混合动力 > 7米澳巴混合动力客车 > 电池管理系统 | 0xB30000C9 中通新能源 > 澳巴混合动力 > 9米11米澳巴混合动力客车 > 电池管理系统 | 部件: 电池管理系统";

BO_ 2565940211 ZT_BMS_18F123F3: 8 Vector__XXX
 SG_ B0 : 0|8@1+ (1,0) [0|255] "" Vector__XXX
 SG_ B1 : 8|8@1+ (1,0) [0|255] "" Vector__XXX
 SG_ B2 : 16|8@1+ (1,0) [0|255] "" Vector__XXX
 SG_ B3 : 24|8@1+ (1,0) [0|255] "" Vector__XXX
 SG_ B4 : 32|8@1+ (1,0) [0|255] "" Vector__XXX
 SG_ B5 : 40|8@1+ (1,0) [0|255] "" Vector__XXX
 SG_ B6 : 48|8@1+ (1,0) [0|255] "" Vector__XXX
 SG_ B7 : 56|8@1+ (1,0) [0|255] "" Vector__XXX

BA_ "VFrameFormat" BO_ 2565940211 1;
CM_ BO_ 2565940211 "0xB3000005 中通新能源 > 纯电动客车 > 10-12米纯电公交客车 > 电池管理系统 | 0xB3000022 中通新能源 > 纯电动客车 > 6米微巴客车 > 电池管理系统 | 0xB300003D 中通新能源 > 纯电动客车 > 8米纯电公交客车 > 电池管理系统 | 0xB300006A 中通新能源 > 纯电动客车 > 电动新大巴客车 > 电池管理系统 | 0xB3000086 中通新能源 > 燃料电池客车 > 电池管理系统 | 0xB30000A8 中通新能源 > 澳巴混合动力 > 7米澳巴混合动力客车 > 电池管理系统 | 0xB30000C9 中通新能源 > 澳巴混合动力 > 9米11米澳巴混合动力客车 > 电池管理系统 | 部件: 电池管理系统";

BO_ 2565940467 ZT_BMS_18F124F3: 8 Vector__XXX
 SG_ B0 : 0|8@1+ (1,0) [0|255] "" Vector__XXX
 SG_ B1 : 8|8@1+ (1,0) [0|255] "" Vector__XXX
 SG_ B2 : 16|8@1+ (1,0) [0|255] "" Vector__XXX
 SG_ B3 : 24|8@1+ (1,0) [0|255] "" Vector__XXX
 SG_ B4 : 32|8@1+ (1,0) [0|255] "" Vector__XXX
 SG_ B5 : 40|8@1+ (1,0) [0|255] "" Vector__XXX
 SG_ B6 : 48|8@1+ (1,0) [0|255] "" Vector__XXX
 SG_ B7 : 56|8@1+ (1,0) [0|255] "" Vector__XXX

BA_ "VFrameFormat" BO_ 2565940467 1;
CM_ BO_ 2565940467 "0xB3000005 中通新能源 > 纯电动客车 > 10-12米纯电公交客车 > 电池管理系统 | 0xB3000022 中通新能源 > 纯电动客车 > 6米微巴客车 > 电池管理系统 | 0xB300003D 中通新能源 > 纯电动客车 > 8米纯电公交客车 > 电池管理系统 | 0xB300006A 中通新能源 > 纯电动客车 > 电动新大巴客车 > 电池管理系统 | 0xB3000086 中通新能源 > 燃料电池客车 > 电池管理系统 | 0xB30000A8 中通新能源 > 澳巴混合动力 > 7米澳巴混合动力客车 > 电池管理系统 | 0xB30000C9 中通新能源 > 澳巴混合动力 > 9米11米澳巴混合动力客车 > 电池管理系统 | 部件: 电池管理系统";

BO_ 2565940723 ZT_BMS_18F125F3: 8 Vector__XXX
 SG_ B0 : 0|8@1+ (1,0) [0|255] "" Vector__XXX
 SG_ B1 : 8|8@1+ (1,0) [0|255] "" Vector__XXX
 SG_ B2 : 16|8@1+ (1,0) [0|255] "" Vector__XXX
 SG_ B3 : 24|8@1+ (1,0) [0|255] "" Vector__XXX
 SG_ B4 : 32|8@1+ (1,0) [0|255] "" Vector__XXX
 SG_ B5 : 40|8@1+ (1,0) [0|255] "" Vector__XXX
 SG_ B6 : 48|8@1+ (1,0) [0|255] "" Vector__XXX
 SG_ B7 : 56|8@1+ (1,0) [0|255] "" Vector__XXX

BA_ "VFrameFormat" BO_ 2565940723 1;
CM_ BO_ 2565940723 "0xB3000005 中通新能源 > 纯电动客车 > 10-12米纯电公交客车 > 电池管理系统 | 0xB3000022 中通新能源 > 纯电动客车 > 6米微巴客车 > 电池管理系统 | 0xB300003D 中通新能源 > 纯电动客车 > 8米纯电公交客车 > 电池管理系统 | 0xB300006A 中通新能源 > 纯电动客车 > 电动新大巴客车 > 电池管理系统 | 0xB3000086 中通新能源 > 燃料电池客车 > 电池管理系统 | 0xB30000A8 中通新能源 > 澳巴混合动力 > 7米澳巴混合动力客车 > 电池管理系统 | 0xB30000C9 中通新能源 > 澳巴混合动力 > 9米11米澳巴混合动力客车 > 电池管理系统 | 部件: 电池管理系统";

BO_ 2565940979 ZT_BMS_18F126F3: 8 Vector__XXX
 SG_ B0 : 0|8@1+ (1,0) [0|255] "" Vector__XXX
 SG_ B1 : 8|8@1+ (1,0) [0|255] "" Vector__XXX
 SG_ B2 : 16|8@1+ (1,0) [0|255] "" Vector__XXX
 SG_ B3 : 24|8@1+ (1,0) [0|255] "" Vector__XXX
 SG_ B4 : 32|8@1+ (1,0) [0|255] "" Vector__XXX
 SG_ B5 : 40|8@1+ (1,0) [0|255] "" Vector__XXX
 SG_ B6 : 48|8@1+ (1,0) [0|255] "" Vector__XXX
 SG_ B7 : 56|8@1+ (1,0) [0|255] "" Vector__XXX

BA_ "VFrameFormat" BO_ 2565940979 1;
CM_ BO_ 2565940979 "0xB3000005 中通新能源 > 纯电动客车 > 10-12米纯电公交客车 > 电池管理系统 | 0xB3000022 中通新能源 > 纯电动客车 > 6米微巴客车 > 电池管理系统 | 0xB300003D 中通新能源 > 纯电动客车 > 8米纯电公交客车 > 电池管理系统 | 0xB300006A 中通新能源 > 纯电动客车 > 电动新大巴客车 > 电池管理系统 | 0xB3000086 中通新能源 > 燃料电池客车 > 电池管理系统 | 0xB30000A8 中通新能源 > 澳巴混合动力 > 7米澳巴混合动力客车 > 电池管理系统 | 0xB30000C9 中通新能源 > 澳巴混合动力 > 9米11米澳巴混合动力客车 > 电池管理系统 | 部件: 电池管理系统";

BO_ 2565941235 ZT_BMS_18F127F3: 8 Vector__XXX
 SG_ B0 : 0|8@1+ (1,0) [0|255] "" Vector__XXX
 SG_ B1 : 8|8@1+ (1,0) [0|255] "" Vector__XXX
 SG_ B2 : 16|8@1+ (1,0) [0|255] "" Vector__XXX
 SG_ B3 : 24|8@1+ (1,0) [0|255] "" Vector__XXX
 SG_ B4 : 32|8@1+ (1,0) [0|255] "" Vector__XXX
 SG_ B5 : 40|8@1+ (1,0) [0|255] "" Vector__XXX
 SG_ B6 : 48|8@1+ (1,0) [0|255] "" Vector__XXX
 SG_ B7 : 56|8@1+ (1,0) [0|255] "" Vector__XXX

BA_ "VFrameFormat" BO_ 2565941235 1;
CM_ BO_ 2565941235 "0xB3000005 中通新能源 > 纯电动客车 > 10-12米纯电公交客车 > 电池管理系统 | 0xB3000022 中通新能源 > 纯电动客车 > 6米微巴客车 > 电池管理系统 | 0xB300003D 中通新能源 > 纯电动客车 > 8米纯电公交客车 > 电池管理系统 | 0xB300006A 中通新能源 > 纯电动客车 > 电动新大巴客车 > 电池管理系统 | 0xB3000086 中通新能源 > 燃料电池客车 > 电池管理系统 | 0xB30000A8 中通新能源 > 澳巴混合动力 > 7米澳巴混合动力客车 > 电池管理系统 | 0xB30000C9 中通新能源 > 澳巴混合动力 > 9米11米澳巴混合动力客车 > 电池管理系统 | 部件: 电池管理系统";

BO_ 2565941491 ZT_BMS_18F128F3: 8 Vector__XXX
 SG_ B0 : 0|8@1+ (1,0) [0|255] "" Vector__XXX
 SG_ B1 : 8|8@1+ (1,0) [0|255] "" Vector__XXX
 SG_ B2 : 16|8@1+ (1,0) [0|255] "" Vector__XXX
 SG_ B3 : 24|8@1+ (1,0) [0|255] "" Vector__XXX
 SG_ B4 : 32|8@1+ (1,0) [0|255] "" Vector__XXX
 SG_ B5 : 40|8@1+ (1,0) [0|255] "" Vector__XXX
 SG_ B6 : 48|8@1+ (1,0) [0|255] "" Vector__XXX
 SG_ B7 : 56|8@1+ (1,0) [0|255] "" Vector__XXX

BA_ "VFrameFormat" BO_ 2565941491 1;
CM_ BO_ 2565941491 "0xB3000005 中通新能源 > 纯电动客车 > 10-12米纯电公交客车 > 电池管理系统 | 0xB3000022 中通新能源 > 纯电动客车 > 6米微巴客车 > 电池管理系统 | 0xB300003D 中通新能源 > 纯电动客车 > 8米纯电公交客车 > 电池管理系统 | 0xB300006A 中通新能源 > 纯电动客车 > 电动新大巴客车 > 电池管理系统 | 0xB3000086 中通新能源 > 燃料电池客车 > 电池管理系统 | 0xB30000A8 中通新能源 > 澳巴混合动力 > 7米澳巴混合动力客车 > 电池管理系统 | 0xB30000C9 中通新能源 > 澳巴混合动力 > 9米11米澳巴混合动力客车 > 电池管理系统 | 部件: 电池管理系统";

BO_ 2565941747 ZT_BMS_18F129F3: 8 Vector__XXX
 SG_ B0 : 0|8@1+ (1,0) [0|255] "" Vector__XXX
 SG_ B1 : 8|8@1+ (1,0) [0|255] "" Vector__XXX
 SG_ B2 : 16|8@1+ (1,0) [0|255] "" Vector__XXX
 SG_ B3 : 24|8@1+ (1,0) [0|255] "" Vector__XXX
 SG_ B4 : 32|8@1+ (1,0) [0|255] "" Vector__XXX
 SG_ B5 : 40|8@1+ (1,0) [0|255] "" Vector__XXX
 SG_ B6 : 48|8@1+ (1,0) [0|255] "" Vector__XXX
 SG_ B7 : 56|8@1+ (1,0) [0|255] "" Vector__XXX

BA_ "VFrameFormat" BO_ 2565941747 1;
CM_ BO_ 2565941747 "0xB3000005 中通新能源 > 纯电动客车 > 10-12米纯电公交客车 > 电池管理系统 | 0xB3000022 中通新能源 > 纯电动客车 > 6米微巴客车 > 电池管理系统 | 0xB300003D 中通新能源 > 纯电动客车 > 8米纯电公交客车 > 电池管理系统 | 0xB300006A 中通新能源 > 纯电动客车 > 电动新大巴客车 > 电池管理系统 | 0xB3000086 中通新能源 > 燃料电池客车 > 电池管理系统 | 0xB30000A8 中通新能源 > 澳巴混合动力 > 7米澳巴混合动力客车 > 电池管理系统 | 0xB30000C9 中通新能源 > 澳巴混合动力 > 9米11米澳巴混合动力客车 > 电池管理系统 | 部件: 电池管理系统";

BO_ 2565942003 ZT_BMS_18F12AF3: 8 Vector__XXX
 SG_ B0 : 0|8@1+ (1,0) [0|255] "" Vector__XXX
 SG_ B1 : 8|8@1+ (1,0) [0|255] "" Vector__XXX
 SG_ B2 : 16|8@1+ (1,0) [0|255] "" Vector__XXX
 SG_ B3 : 24|8@1+ (1,0) [0|255] "" Vector__XXX
 SG_ B4 : 32|8@1+ (1,0) [0|255] "" Vector__XXX
 SG_ B5 : 40|8@1+ (1,0) [0|255] "" Vector__XXX
 SG_ B6 : 48|8@1+ (1,0) [0|255] "" Vector__XXX
 SG_ B7 : 56|8@1+ (1,0) [0|255] "" Vector__XXX

BA_ "VFrameFormat" BO_ 2565942003 1;
CM_ BO_ 2565942003 "0xB3000005 中通新能源 > 纯电动客车 > 10-12米纯电公交客车 > 电池管理系统 | 0xB3000022 中通新能源 > 纯电动客车 > 6米微巴客车 > 电池管理系统 | 0xB300006A 中通新能源 > 纯电动客车 > 电动新大巴客车 > 电池管理系统 | 0xB3000086 中通新能源 > 燃料电池客车 > 电池管理系统 | 部件: 电池管理系统";

BO_ 2565942259 ZT_BMS_18F12BF3: 8 Vector__XXX
 SG_ B0 : 0|8@1+ (1,0) [0|255] "" Vector__XXX
 SG_ B1 : 8|8@1+ (1,0) [0|255] "" Vector__XXX
 SG_ B2 : 16|8@1+ (1,0) [0|255] "" Vector__XXX
 SG_ B3 : 24|8@1+ (1,0) [0|255] "" Vector__XXX
 SG_ B4 : 32|8@1+ (1,0) [0|255] "" Vector__XXX
 SG_ B5 : 40|8@1+ (1,0) [0|255] "" Vector__XXX
 SG_ B6 : 48|8@1+ (1,0) [0|255] "" Vector__XXX
 SG_ B7 : 56|8@1+ (1,0) [0|255] "" Vector__XXX

BA_ "VFrameFormat" BO_ 2565942259 1;
CM_ BO_ 2565942259 "0xB3000005 中通新能源 > 纯电动客车 > 10-12米纯电公交客车 > 电池管理系统 | 0xB3000022 中通新能源 > 纯电动客车 > 6米微巴客车 > 电池管理系统 | 0xB300006A 中通新能源 > 纯电动客车 > 电动新大巴客车 > 电池管理系统 | 0xB3000086 中通新能源 > 燃料电池客车 > 电池管理系统 | 部件: 电池管理系统";

BO_ 2565942515 ZT_BMS_18F12CF3: 8 Vector__XXX
 SG_ B0 : 0|8@1+ (1,0) [0|255] "" Vector__XXX
 SG_ B1 : 8|8@1+ (1,0) [0|255] "" Vector__XXX
 SG_ B2 : 16|8@1+ (1,0) [0|255] "" Vector__XXX
 SG_ B3 : 24|8@1+ (1,0) [0|255] "" Vector__XXX
 SG_ B4 : 32|8@1+ (1,0) [0|255] "" Vector__XXX
 SG_ B5 : 40|8@1+ (1,0) [0|255] "" Vector__XXX
 SG_ B6 : 48|8@1+ (1,0) [0|255] "" Vector__XXX
 SG_ B7 : 56|8@1+ (1,0) [0|255] "" Vector__XXX

BA_ "VFrameFormat" BO_ 2565942515 1;
CM_ BO_ 2565942515 "0xB3000005 中通新能源 > 纯电动客车 > 10-12米纯电公交客车 > 电池管理系统 | 0xB3000022 中通新能源 > 纯电动客车 > 6米微巴客车 > 电池管理系统 | 0xB300006A 中通新能源 > 纯电动客车 > 电动新大巴客车 > 电池管理系统 | 0xB3000086 中通新能源 > 燃料电池客车 > 电池管理系统 | 部件: 电池管理系统";

BO_ 2565942771 ZT_BMS_18F12DF3: 8 Vector__XXX
 SG_ B0 : 0|8@1+ (1,0) [0|255] "" Vector__XXX
 SG_ B1 : 8|8@1+ (1,0) [0|255] "" Vector__XXX
 SG_ B2 : 16|8@1+ (1,0) [0|255] "" Vector__XXX
 SG_ B3 : 24|8@1+ (1,0) [0|255] "" Vector__XXX
 SG_ B4 : 32|8@1+ (1,0) [0|255] "" Vector__XXX
 SG_ B5 : 40|8@1+ (1,0) [0|255] "" Vector__XXX
 SG_ B6 : 48|8@1+ (1,0) [0|255] "" Vector__XXX
 SG_ B7 : 56|8@1+ (1,0) [0|255] "" Vector__XXX

BA_ "VFrameFormat" BO_ 2565942771 1;
CM_ BO_ 2565942771 "0xB3000005 中通新能源 > 纯电动客车 > 10-12米纯电公交客车 > 电池管理系统 | 0xB3000022 中通新能源 > 纯电动客车 > 6米微巴客车 > 电池管理系统 | 0xB300006A 中通新能源 > 纯电动客车 > 电动新大巴客车 > 电池管理系统 | 0xB3000086 中通新能源 > 燃料电池客车 > 电池管理系统 | 部件: 电池管理系统";

BO_ 2565943027 ZT_BMS_18F12EF3: 8 Vector__XXX
 SG_ B0 : 0|8@1+ (1,0) [0|255] "" Vector__XXX
 SG_ B1 : 8|8@1+ (1,0) [0|255] "" Vector__XXX
 SG_ B2 : 16|8@1+ (1,0) [0|255] "" Vector__XXX
 SG_ B3 : 24|8@1+ (1,0) [0|255] "" Vector__XXX
 SG_ B4 : 32|8@1+ (1,0) [0|255] "" Vector__XXX
 SG_ B5 : 40|8@1+ (1,0) [0|255] "" Vector__XXX
 SG_ B6 : 48|8@1+ (1,0) [0|255] "" Vector__XXX
 SG_ B7 : 56|8@1+ (1,0) [0|255] "" Vector__XXX

BA_ "VFrameFormat" BO_ 2565943027 1;
CM_ BO_ 2565943027 "0xB3000005 中通新能源 > 纯电动客车 > 10-12米纯电公交客车 > 电池管理系统 | 0xB3000022 中通新能源 > 纯电动客车 > 6米微巴客车 > 电池管理系统 | 0xB300006A 中通新能源 > 纯电动客车 > 电动新大巴客车 > 电池管理系统 | 0xB3000086 中通新能源 > 燃料电池客车 > 电池管理系统 | 部件: 电池管理系统";

BO_ 2565943283 ZT_BMS_18F12FF3: 8 Vector__XXX
 SG_ B0 : 0|8@1+ (1,0) [0|255] "" Vector__XXX
 SG_ B1 : 8|8@1+ (1,0) [0|255] "" Vector__XXX
 SG_ B2 : 16|8@1+ (1,0) [0|255] "" Vector__XXX
 SG_ B3 : 24|8@1+ (1,0) [0|255] "" Vector__XXX
 SG_ B4 : 32|8@1+ (1,0) [0|255] "" Vector__XXX
 SG_ B5 : 40|8@1+ (1,0) [0|255] "" Vector__XXX
 SG_ B6 : 48|8@1+ (1,0) [0|255] "" Vector__XXX
 SG_ B7 : 56|8@1+ (1,0) [0|255] "" Vector__XXX

BA_ "VFrameFormat" BO_ 2565943283 1;
CM_ BO_ 2565943283 "0xB3000005 中通新能源 > 纯电动客车 > 10-12米纯电公交客车 > 电池管理系统 | 0xB3000022 中通新能源 > 纯电动客车 > 6米微巴客车 > 电池管理系统 | 0xB300006A 中通新能源 > 纯电动客车 > 电动新大巴客车 > 电池管理系统 | 0xB3000086 中通新能源 > 燃料电池客车 > 电池管理系统 | 部件: 电池管理系统";

BO_ 2565943539 ZT_BMS_18F130F3: 8 Vector__XXX
 SG_ B0 : 0|8@1+ (1,0) [0|255] "" Vector__XXX
 SG_ B1 : 8|8@1+ (1,0) [0|255] "" Vector__XXX
 SG_ B2 : 16|8@1+ (1,0) [0|255] "" Vector__XXX
 SG_ B3 : 24|8@1+ (1,0) [0|255] "" Vector__XXX
 SG_ B4 : 32|8@1+ (1,0) [0|255] "" Vector__XXX
 SG_ B5 : 40|8@1+ (1,0) [0|255] "" Vector__XXX
 SG_ B6 : 48|8@1+ (1,0) [0|255] "" Vector__XXX
 SG_ B7 : 56|8@1+ (1,0) [0|255] "" Vector__XXX

BA_ "VFrameFormat" BO_ 2565943539 1;
CM_ BO_ 2565943539 "0xB3000005 中通新能源 > 纯电动客车 > 10-12米纯电公交客车 > 电池管理系统 | 0xB3000022 中通新能源 > 纯电动客车 > 6米微巴客车 > 电池管理系统 | 0xB300006A 中通新能源 > 纯电动客车 > 电动新大巴客车 > 电池管理系统 | 部件: 电池管理系统";

BO_ 2565943795 ZT_BMS_18F131F3: 8 Vector__XXX
 SG_ B0 : 0|8@1+ (1,0) [0|255] "" Vector__XXX
 SG_ B1 : 8|8@1+ (1,0) [0|255] "" Vector__XXX
 SG_ B2 : 16|8@1+ (1,0) [0|255] "" Vector__XXX
 SG_ B3 : 24|8@1+ (1,0) [0|255] "" Vector__XXX
 SG_ B4 : 32|8@1+ (1,0) [0|255] "" Vector__XXX
 SG_ B5 : 40|8@1+ (1,0) [0|255] "" Vector__XXX
 SG_ B6 : 48|8@1+ (1,0) [0|255] "" Vector__XXX
 SG_ B7 : 56|8@1+ (1,0) [0|255] "" Vector__XXX

BA_ "VFrameFormat" BO_ 2565943795 1;
CM_ BO_ 2565943795 "0xB3000005 中通新能源 > 纯电动客车 > 10-12米纯电公交客车 > 电池管理系统 | 0xB300006A 中通新能源 > 纯电动客车 > 电动新大巴客车 > 电池管理系统 | 部件: 电池管理系统";

BO_ 2565944051 ZT_BMS_18F132F3: 8 Vector__XXX
 SG_ B0 : 0|8@1+ (1,0) [0|255] "" Vector__XXX
 SG_ B1 : 8|8@1+ (1,0) [0|255] "" Vector__XXX
 SG_ B2 : 16|8@1+ (1,0) [0|255] "" Vector__XXX
 SG_ B3 : 24|8@1+ (1,0) [0|255] "" Vector__XXX
 SG_ B4 : 32|8@1+ (1,0) [0|255] "" Vector__XXX
 SG_ B5 : 40|8@1+ (1,0) [0|255] "" Vector__XXX
 SG_ B6 : 48|8@1+ (1,0) [0|255] "" Vector__XXX
 SG_ B7 : 56|8@1+ (1,0) [0|255] "" Vector__XXX

BA_ "VFrameFormat" BO_ 2565944051 1;
CM_ BO_ 2565944051 "0xB3000005 中通新能源 > 纯电动客车 > 10-12米纯电公交客车 > 电池管理系统 | 0xB300006A 中通新能源 > 纯电动客车 > 电动新大巴客车 > 电池管理系统 | 部件: 电池管理系统";

BO_ 2565944307 ZT_BMS_18F133F3: 8 Vector__XXX
 SG_ B0 : 0|8@1+ (1,0) [0|255] "" Vector__XXX
 SG_ B1 : 8|8@1+ (1,0) [0|255] "" Vector__XXX
 SG_ B2 : 16|8@1+ (1,0) [0|255] "" Vector__XXX
 SG_ B3 : 24|8@1+ (1,0) [0|255] "" Vector__XXX
 SG_ B4 : 32|8@1+ (1,0) [0|255] "" Vector__XXX
 SG_ B5 : 40|8@1+ (1,0) [0|255] "" Vector__XXX
 SG_ B6 : 48|8@1+ (1,0) [0|255] "" Vector__XXX
 SG_ B7 : 56|8@1+ (1,0) [0|255] "" Vector__XXX

BA_ "VFrameFormat" BO_ 2565944307 1;
CM_ BO_ 2565944307 "0xB3000005 中通新能源 > 纯电动客车 > 10-12米纯电公交客车 > 电池管理系统 | 0xB300006A 中通新能源 > 纯电动客车 > 电动新大巴客车 > 电池管理系统 | 部件: 电池管理系统";

BO_ 2565944563 ZT_BMS_18F134F3: 8 Vector__XXX
 SG_ B0 : 0|8@1+ (1,0) [0|255] "" Vector__XXX
 SG_ B1 : 8|8@1+ (1,0) [0|255] "" Vector__XXX
 SG_ B2 : 16|8@1+ (1,0) [0|255] "" Vector__XXX
 SG_ B3 : 24|8@1+ (1,0) [0|255] "" Vector__XXX
 SG_ B4 : 32|8@1+ (1,0) [0|255] "" Vector__XXX
 SG_ B5 : 40|8@1+ (1,0) [0|255] "" Vector__XXX
 SG_ B6 : 48|8@1+ (1,0) [0|255] "" Vector__XXX
 SG_ B7 : 56|8@1+ (1,0) [0|255] "" Vector__XXX

BA_ "VFrameFormat" BO_ 2565944563 1;
CM_ BO_ 2565944563 "0xB3000005 中通新能源 > 纯电动客车 > 10-12米纯电公交客车 > 电池管理系统 | 0xB300006A 中通新能源 > 纯电动客车 > 电动新大巴客车 > 电池管理系统 | 部件: 电池管理系统";

BO_ 2565944819 ZT_BMS_18F135F3: 8 Vector__XXX
 SG_ B0 : 0|8@1+ (1,0) [0|255] "" Vector__XXX
 SG_ B1 : 8|8@1+ (1,0) [0|255] "" Vector__XXX
 SG_ B2 : 16|8@1+ (1,0) [0|255] "" Vector__XXX
 SG_ B3 : 24|8@1+ (1,0) [0|255] "" Vector__XXX
 SG_ B4 : 32|8@1+ (1,0) [0|255] "" Vector__XXX
 SG_ B5 : 40|8@1+ (1,0) [0|255] "" Vector__XXX
 SG_ B6 : 48|8@1+ (1,0) [0|255] "" Vector__XXX
 SG_ B7 : 56|8@1+ (1,0) [0|255] "" Vector__XXX

BA_ "VFrameFormat" BO_ 2565944819 1;
CM_ BO_ 2565944819 "0xB3000005 中通新能源 > 纯电动客车 > 10-12米纯电公交客车 > 电池管理系统 | 0xB300006A 中通新能源 > 纯电动客车 > 电动新大巴客车 > 电池管理系统 | 部件: 电池管理系统";

BO_ 2565945075 ZT_BMS_18F136F3: 8 Vector__XXX
 SG_ B0 : 0|8@1+ (1,0) [0|255] "" Vector__XXX
 SG_ B1 : 8|8@1+ (1,0) [0|255] "" Vector__XXX
 SG_ B2 : 16|8@1+ (1,0) [0|255] "" Vector__XXX
 SG_ B3 : 24|8@1+ (1,0) [0|255] "" Vector__XXX
 SG_ B4 : 32|8@1+ (1,0) [0|255] "" Vector__XXX
 SG_ B5 : 40|8@1+ (1,0) [0|255] "" Vector__XXX
 SG_ B6 : 48|8@1+ (1,0) [0|255] "" Vector__XXX
 SG_ B7 : 56|8@1+ (1,0) [0|255] "" Vector__XXX

BA_ "VFrameFormat" BO_ 2565945075 1;
CM_ BO_ 2565945075 "0xB3000005 中通新能源 > 纯电动客车 > 10-12米纯电公交客车 > 电池管理系统 | 0xB300006A 中通新能源 > 纯电动客车 > 电动新大巴客车 > 电池管理系统 | 部件: 电池管理系统";

BO_ 2565945331 ZT_BMS_18F137F3: 8 Vector__XXX
 SG_ B0 : 0|8@1+ (1,0) [0|255] "" Vector__XXX
 SG_ B1 : 8|8@1+ (1,0) [0|255] "" Vector__XXX
 SG_ B2 : 16|8@1+ (1,0) [0|255] "" Vector__XXX
 SG_ B3 : 24|8@1+ (1,0) [0|255] "" Vector__XXX
 SG_ B4 : 32|8@1+ (1,0) [0|255] "" Vector__XXX
 SG_ B5 : 40|8@1+ (1,0) [0|255] "" Vector__XXX
 SG_ B6 : 48|8@1+ (1,0) [0|255] "" Vector__XXX
 SG_ B7 : 56|8@1+ (1,0) [0|255] "" Vector__XXX

BA_ "VFrameFormat" BO_ 2565945331 1;
CM_ BO_ 2565945331 "0xB3000005 中通新能源 > 纯电动客车 > 10-12米纯电公交客车 > 电池管理系统 | 0xB300006A 中通新能源 > 纯电动客车 > 电动新大巴客车 > 电池管理系统 | 部件: 电池管理系统";

BO_ 2565945587 ZT_BMS_18F138F3: 8 Vector__XXX
 SG_ B0 : 0|8@1+ (1,0) [0|255] "" Vector__XXX
 SG_ B1 : 8|8@1+ (1,0) [0|255] "" Vector__XXX
 SG_ B2 : 16|8@1+ (1,0) [0|255] "" Vector__XXX
 SG_ B3 : 24|8@1+ (1,0) [0|255] "" Vector__XXX
 SG_ B4 : 32|8@1+ (1,0) [0|255] "" Vector__XXX
 SG_ B5 : 40|8@1+ (1,0) [0|255] "" Vector__XXX
 SG_ B6 : 48|8@1+ (1,0) [0|255] "" Vector__XXX
 SG_ B7 : 56|8@1+ (1,0) [0|255] "" Vector__XXX

BA_ "VFrameFormat" BO_ 2565945587 1;
CM_ BO_ 2565945587 "0xB3000005 中通新能源 > 纯电动客车 > 10-12米纯电公交客车 > 电池管理系统 | 0xB300006A 中通新能源 > 纯电动客车 > 电动新大巴客车 > 电池管理系统 | 部件: 电池管理系统";

BO_ 2565945843 ZT_BMS_18F139F3: 8 Vector__XXX
 SG_ B0 : 0|8@1+ (1,0) [0|255] "" Vector__XXX
 SG_ B1 : 8|8@1+ (1,0) [0|255] "" Vector__XXX
 SG_ B2 : 16|8@1+ (1,0) [0|255] "" Vector__XXX
 SG_ B3 : 24|8@1+ (1,0) [0|255] "" Vector__XXX
 SG_ B4 : 32|8@1+ (1,0) [0|255] "" Vector__XXX
 SG_ B5 : 40|8@1+ (1,0) [0|255] "" Vector__XXX
 SG_ B6 : 48|8@1+ (1,0) [0|255] "" Vector__XXX
 SG_ B7 : 56|8@1+ (1,0) [0|255] "" Vector__XXX

BA_ "VFrameFormat" BO_ 2565945843 1;
CM_ BO_ 2565945843 "0xB3000005 中通新能源 > 纯电动客车 > 10-12米纯电公交客车 > 电池管理系统 | 0xB300006A 中通新能源 > 纯电动客车 > 电动新大巴客车 > 电池管理系统 | 部件: 电池管理系统";

BO_ 2565946099 ZT_BMS_18F13AF3: 8 Vector__XXX
 SG_ B0 : 0|8@1+ (1,0) [0|255] "" Vector__XXX
 SG_ B1 : 8|8@1+ (1,0) [0|255] "" Vector__XXX
 SG_ B2 : 16|8@1+ (1,0) [0|255] "" Vector__XXX
 SG_ B3 : 24|8@1+ (1,0) [0|255] "" Vector__XXX
 SG_ B4 : 32|8@1+ (1,0) [0|255] "" Vector__XXX
 SG_ B5 : 40|8@1+ (1,0) [0|255] "" Vector__XXX
 SG_ B6 : 48|8@1+ (1,0) [0|255] "" Vector__XXX
 SG_ B7 : 56|8@1+ (1,0) [0|255] "" Vector__XXX

BA_ "VFrameFormat" BO_ 2565946099 1;
CM_ BO_ 2565946099 "0xB3000005 中通新能源 > 纯电动客车 > 10-12米纯电公交客车 > 电池管理系统 | 0xB300006A 中通新能源 > 纯电动客车 > 电动新大巴客车 > 电池管理系统 | 部件: 电池管理系统";

BO_ 2565946355 ZT_BMS_18F13BF3: 8 Vector__XXX
 SG_ B0 : 0|8@1+ (1,0) [0|255] "" Vector__XXX
 SG_ B1 : 8|8@1+ (1,0) [0|255] "" Vector__XXX
 SG_ B2 : 16|8@1+ (1,0) [0|255] "" Vector__XXX
 SG_ B3 : 24|8@1+ (1,0) [0|255] "" Vector__XXX
 SG_ B4 : 32|8@1+ (1,0) [0|255] "" Vector__XXX
 SG_ B5 : 40|8@1+ (1,0) [0|255] "" Vector__XXX
 SG_ B6 : 48|8@1+ (1,0) [0|255] "" Vector__XXX
 SG_ B7 : 56|8@1+ (1,0) [0|255] "" Vector__XXX

BA_ "VFrameFormat" BO_ 2565946355 1;
CM_ BO_ 2565946355 "0xB3000005 中通新能源 > 纯电动客车 > 10-12米纯电公交客车 > 电池管理系统 | 0xB300006A 中通新能源 > 纯电动客车 > 电动新大巴客车 > 电池管理系统 | 部件: 电池管理系统";

BO_ 2565946611 ZT_BMS_18F13CF3: 8 Vector__XXX
 SG_ B0 : 0|8@1+ (1,0) [0|255] "" Vector__XXX
 SG_ B1 : 8|8@1+ (1,0) [0|255] "" Vector__XXX
 SG_ B2 : 16|8@1+ (1,0) [0|255] "" Vector__XXX
 SG_ B3 : 24|8@1+ (1,0) [0|255] "" Vector__XXX
 SG_ B4 : 32|8@1+ (1,0) [0|255] "" Vector__XXX
 SG_ B5 : 40|8@1+ (1,0) [0|255] "" Vector__XXX
 SG_ B6 : 48|8@1+ (1,0) [0|255] "" Vector__XXX
 SG_ B7 : 56|8@1+ (1,0) [0|255] "" Vector__XXX

BA_ "VFrameFormat" BO_ 2565946611 1;
CM_ BO_ 2565946611 "0xB3000005 中通新能源 > 纯电动客车 > 10-12米纯电公交客车 > 电池管理系统 | 0xB300006A 中通新能源 > 纯电动客车 > 电动新大巴客车 > 电池管理系统 | 部件: 电池管理系统";

BO_ 2565946867 ZT_BMS_18F13DF3: 8 Vector__XXX
 SG_ B0 : 0|8@1+ (1,0) [0|255] "" Vector__XXX
 SG_ B1 : 8|8@1+ (1,0) [0|255] "" Vector__XXX
 SG_ B2 : 16|8@1+ (1,0) [0|255] "" Vector__XXX
 SG_ B3 : 24|8@1+ (1,0) [0|255] "" Vector__XXX
 SG_ B4 : 32|8@1+ (1,0) [0|255] "" Vector__XXX
 SG_ B5 : 40|8@1+ (1,0) [0|255] "" Vector__XXX
 SG_ B6 : 48|8@1+ (1,0) [0|255] "" Vector__XXX
 SG_ B7 : 56|8@1+ (1,0) [0|255] "" Vector__XXX

BA_ "VFrameFormat" BO_ 2565946867 1;
CM_ BO_ 2565946867 "0xB3000005 中通新能源 > 纯电动客车 > 10-12米纯电公交客车 > 电池管理系统 | 0xB300006A 中通新能源 > 纯电动客车 > 电动新大巴客车 > 电池管理系统 | 部件: 电池管理系统";

BO_ 2565947123 ZT_BMS_18F13EF3: 8 Vector__XXX
 SG_ B0 : 0|8@1+ (1,0) [0|255] "" Vector__XXX
 SG_ B1 : 8|8@1+ (1,0) [0|255] "" Vector__XXX
 SG_ B2 : 16|8@1+ (1,0) [0|255] "" Vector__XXX
 SG_ B3 : 24|8@1+ (1,0) [0|255] "" Vector__XXX
 SG_ B4 : 32|8@1+ (1,0) [0|255] "" Vector__XXX
 SG_ B5 : 40|8@1+ (1,0) [0|255] "" Vector__XXX
 SG_ B6 : 48|8@1+ (1,0) [0|255] "" Vector__XXX
 SG_ B7 : 56|8@1+ (1,0) [0|255] "" Vector__XXX

BA_ "VFrameFormat" BO_ 2565947123 1;
CM_ BO_ 2565947123 "0xB3000005 中通新能源 > 纯电动客车 > 10-12米纯电公交客车 > 电池管理系统 | 0xB300006A 中通新能源 > 纯电动客车 > 电动新大巴客车 > 电池管理系统 | 部件: 电池管理系统";

BO_ 2565947379 ZT_BMS_18F13FF3: 8 Vector__XXX
 SG_ B0 : 0|8@1+ (1,0) [0|255] "" Vector__XXX
 SG_ B1 : 8|8@1+ (1,0) [0|255] "" Vector__XXX
 SG_ B2 : 16|8@1+ (1,0) [0|255] "" Vector__XXX
 SG_ B3 : 24|8@1+ (1,0) [0|255] "" Vector__XXX
 SG_ B4 : 32|8@1+ (1,0) [0|255] "" Vector__XXX
 SG_ B5 : 40|8@1+ (1,0) [0|255] "" Vector__XXX
 SG_ B6 : 48|8@1+ (1,0) [0|255] "" Vector__XXX
 SG_ B7 : 56|8@1+ (1,0) [0|255] "" Vector__XXX

BA_ "VFrameFormat" BO_ 2565947379 1;
CM_ BO_ 2565947379 "0xB3000005 中通新能源 > 纯电动客车 > 10-12米纯电公交客车 > 电池管理系统 | 0xB300006A 中通新能源 > 纯电动客车 > 电动新大巴客车 > 电池管理系统 | 部件: 电池管理系统";

BO_ 2565947635 ZT_BMS_18F140F3: 8 Vector__XXX
 SG_ B0 : 0|8@1+ (1,0) [0|255] "" Vector__XXX
 SG_ B1 : 8|8@1+ (1,0) [0|255] "" Vector__XXX
 SG_ B2 : 16|8@1+ (1,0) [0|255] "" Vector__XXX
 SG_ B3 : 24|8@1+ (1,0) [0|255] "" Vector__XXX
 SG_ B4 : 32|8@1+ (1,0) [0|255] "" Vector__XXX
 SG_ B5 : 40|8@1+ (1,0) [0|255] "" Vector__XXX
 SG_ B6 : 48|8@1+ (1,0) [0|255] "" Vector__XXX
 SG_ B7 : 56|8@1+ (1,0) [0|255] "" Vector__XXX

BA_ "VFrameFormat" BO_ 2565947635 1;
CM_ BO_ 2565947635 "0xB3000005 中通新能源 > 纯电动客车 > 10-12米纯电公交客车 > 电池管理系统 | 0xB300006A 中通新能源 > 纯电动客车 > 电动新大巴客车 > 电池管理系统 | 部件: 电池管理系统";

BO_ 2565947891 ZT_BMS_18F141F3: 8 Vector__XXX
 SG_ B0 : 0|8@1+ (1,0) [0|255] "" Vector__XXX
 SG_ B1 : 8|8@1+ (1,0) [0|255] "" Vector__XXX
 SG_ B2 : 16|8@1+ (1,0) [0|255] "" Vector__XXX
 SG_ B3 : 24|8@1+ (1,0) [0|255] "" Vector__XXX
 SG_ B4 : 32|8@1+ (1,0) [0|255] "" Vector__XXX
 SG_ B5 : 40|8@1+ (1,0) [0|255] "" Vector__XXX
 SG_ B6 : 48|8@1+ (1,0) [0|255] "" Vector__XXX
 SG_ B7 : 56|8@1+ (1,0) [0|255] "" Vector__XXX

BA_ "VFrameFormat" BO_ 2565947891 1;
CM_ BO_ 2565947891 "0xB3000005 中通新能源 > 纯电动客车 > 10-12米纯电公交客车 > 电池管理系统 | 0xB300006A 中通新能源 > 纯电动客车 > 电动新大巴客车 > 电池管理系统 | 部件: 电池管理系统";

BO_ 2565948147 ZT_BMS_18F142F3: 8 Vector__XXX
 SG_ B0 : 0|8@1+ (1,0) [0|255] "" Vector__XXX
 SG_ B1 : 8|8@1+ (1,0) [0|255] "" Vector__XXX
 SG_ B2 : 16|8@1+ (1,0) [0|255] "" Vector__XXX
 SG_ B3 : 24|8@1+ (1,0) [0|255] "" Vector__XXX
 SG_ B4 : 32|8@1+ (1,0) [0|255] "" Vector__XXX
 SG_ B5 : 40|8@1+ (1,0) [0|255] "" Vector__XXX
 SG_ B6 : 48|8@1+ (1,0) [0|255] "" Vector__XXX
 SG_ B7 : 56|8@1+ (1,0) [0|255] "" Vector__XXX

BA_ "VFrameFormat" BO_ 2565948147 1;
CM_ BO_ 2565948147 "0xB3000005 中通新能源 > 纯电动客车 > 10-12米纯电公交客车 > 电池管理系统 | 0xB300006A 中通新能源 > 纯电动客车 > 电动新大巴客车 > 电池管理系统 | 部件: 电池管理系统";

BO_ 2565948403 ZT_BMS_18F143F3: 8 Vector__XXX
 SG_ B0 : 0|8@1+ (1,0) [0|255] "" Vector__XXX
 SG_ B1 : 8|8@1+ (1,0) [0|255] "" Vector__XXX
 SG_ B2 : 16|8@1+ (1,0) [0|255] "" Vector__XXX
 SG_ B3 : 24|8@1+ (1,0) [0|255] "" Vector__XXX
 SG_ B4 : 32|8@1+ (1,0) [0|255] "" Vector__XXX
 SG_ B5 : 40|8@1+ (1,0) [0|255] "" Vector__XXX
 SG_ B6 : 48|8@1+ (1,0) [0|255] "" Vector__XXX
 SG_ B7 : 56|8@1+ (1,0) [0|255] "" Vector__XXX

BA_ "VFrameFormat" BO_ 2565948403 1;
CM_ BO_ 2565948403 "0xB3000005 中通新能源 > 纯电动客车 > 10-12米纯电公交客车 > 电池管理系统 | 0xB300006A 中通新能源 > 纯电动客车 > 电动新大巴客车 > 电池管理系统 | 部件: 电池管理系统";

BO_ 2565948659 ZT_BMS_18F144F3: 8 Vector__XXX
 SG_ B0 : 0|8@1+ (1,0) [0|255] "" Vector__XXX
 SG_ B1 : 8|8@1+ (1,0) [0|255] "" Vector__XXX
 SG_ B2 : 16|8@1+ (1,0) [0|255] "" Vector__XXX
 SG_ B3 : 24|8@1+ (1,0) [0|255] "" Vector__XXX
 SG_ B4 : 32|8@1+ (1,0) [0|255] "" Vector__XXX
 SG_ B5 : 40|8@1+ (1,0) [0|255] "" Vector__XXX
 SG_ B6 : 48|8@1+ (1,0) [0|255] "" Vector__XXX
 SG_ B7 : 56|8@1+ (1,0) [0|255] "" Vector__XXX

BA_ "VFrameFormat" BO_ 2565948659 1;
CM_ BO_ 2565948659 "0xB3000005 中通新能源 > 纯电动客车 > 10-12米纯电公交客车 > 电池管理系统 | 0xB300006A 中通新能源 > 纯电动客车 > 电动新大巴客车 > 电池管理系统 | 部件: 电池管理系统";

BO_ 2565948915 ZT_BMS_18F145F3: 8 Vector__XXX
 SG_ B0 : 0|8@1+ (1,0) [0|255] "" Vector__XXX
 SG_ B1 : 8|8@1+ (1,0) [0|255] "" Vector__XXX
 SG_ B2 : 16|8@1+ (1,0) [0|255] "" Vector__XXX
 SG_ B3 : 24|8@1+ (1,0) [0|255] "" Vector__XXX
 SG_ B4 : 32|8@1+ (1,0) [0|255] "" Vector__XXX
 SG_ B5 : 40|8@1+ (1,0) [0|255] "" Vector__XXX
 SG_ B6 : 48|8@1+ (1,0) [0|255] "" Vector__XXX
 SG_ B7 : 56|8@1+ (1,0) [0|255] "" Vector__XXX

BA_ "VFrameFormat" BO_ 2565948915 1;
CM_ BO_ 2565948915 "0xB3000005 中通新能源 > 纯电动客车 > 10-12米纯电公交客车 > 电池管理系统 | 0xB300006A 中通新能源 > 纯电动客车 > 电动新大巴客车 > 电池管理系统 | 部件: 电池管理系统";

BO_ 2565949171 ZT_BMS_18F146F3: 8 Vector__XXX
 SG_ B0 : 0|8@1+ (1,0) [0|255] "" Vector__XXX
 SG_ B1 : 8|8@1+ (1,0) [0|255] "" Vector__XXX
 SG_ B2 : 16|8@1+ (1,0) [0|255] "" Vector__XXX
 SG_ B3 : 24|8@1+ (1,0) [0|255] "" Vector__XXX
 SG_ B4 : 32|8@1+ (1,0) [0|255] "" Vector__XXX
 SG_ B5 : 40|8@1+ (1,0) [0|255] "" Vector__XXX
 SG_ B6 : 48|8@1+ (1,0) [0|255] "" Vector__XXX
 SG_ B7 : 56|8@1+ (1,0) [0|255] "" Vector__XXX

BA_ "VFrameFormat" BO_ 2565949171 1;
CM_ BO_ 2565949171 "0xB3000005 中通新能源 > 纯电动客车 > 10-12米纯电公交客车 > 电池管理系统 | 0xB300006A 中通新能源 > 纯电动客车 > 电动新大巴客车 > 电池管理系统 | 部件: 电池管理系统";

BO_ 2565949427 ZT_BMS_18F147F3: 8 Vector__XXX
 SG_ B0 : 0|8@1+ (1,0) [0|255] "" Vector__XXX
 SG_ B1 : 8|8@1+ (1,0) [0|255] "" Vector__XXX
 SG_ B2 : 16|8@1+ (1,0) [0|255] "" Vector__XXX
 SG_ B3 : 24|8@1+ (1,0) [0|255] "" Vector__XXX
 SG_ B4 : 32|8@1+ (1,0) [0|255] "" Vector__XXX
 SG_ B5 : 40|8@1+ (1,0) [0|255] "" Vector__XXX
 SG_ B6 : 48|8@1+ (1,0) [0|255] "" Vector__XXX
 SG_ B7 : 56|8@1+ (1,0) [0|255] "" Vector__XXX

BA_ "VFrameFormat" BO_ 2565949427 1;
CM_ BO_ 2565949427 "0xB3000005 中通新能源 > 纯电动客车 > 10-12米纯电公交客车 > 电池管理系统 | 0xB300006A 中通新能源 > 纯电动客车 > 电动新大巴客车 > 电池管理系统 | 部件: 电池管理系统";

BO_ 2565949683 ZT_BMS_18F148F3: 8 Vector__XXX
 SG_ B0 : 0|8@1+ (1,0) [0|255] "" Vector__XXX
 SG_ B1 : 8|8@1+ (1,0) [0|255] "" Vector__XXX
 SG_ B2 : 16|8@1+ (1,0) [0|255] "" Vector__XXX
 SG_ B3 : 24|8@1+ (1,0) [0|255] "" Vector__XXX
 SG_ B4 : 32|8@1+ (1,0) [0|255] "" Vector__XXX
 SG_ B5 : 40|8@1+ (1,0) [0|255] "" Vector__XXX
 SG_ B6 : 48|8@1+ (1,0) [0|255] "" Vector__XXX
 SG_ B7 : 56|8@1+ (1,0) [0|255] "" Vector__XXX

BA_ "VFrameFormat" BO_ 2565949683 1;
CM_ BO_ 2565949683 "0xB3000005 中通新能源 > 纯电动客车 > 10-12米纯电公交客车 > 电池管理系统 | 0xB300006A 中通新能源 > 纯电动客车 > 电动新大巴客车 > 电池管理系统 | 部件: 电池管理系统";

BO_ 2565949939 ZT_BMS_18F149F3: 8 Vector__XXX
 SG_ B0 : 0|8@1+ (1,0) [0|255] "" Vector__XXX
 SG_ B1 : 8|8@1+ (1,0) [0|255] "" Vector__XXX
 SG_ B2 : 16|8@1+ (1,0) [0|255] "" Vector__XXX
 SG_ B3 : 24|8@1+ (1,0) [0|255] "" Vector__XXX
 SG_ B4 : 32|8@1+ (1,0) [0|255] "" Vector__XXX
 SG_ B5 : 40|8@1+ (1,0) [0|255] "" Vector__XXX
 SG_ B6 : 48|8@1+ (1,0) [0|255] "" Vector__XXX
 SG_ B7 : 56|8@1+ (1,0) [0|255] "" Vector__XXX

BA_ "VFrameFormat" BO_ 2565949939 1;
CM_ BO_ 2565949939 "0xB3000005 中通新能源 > 纯电动客车 > 10-12米纯电公交客车 > 电池管理系统 | 0xB300006A 中通新能源 > 纯电动客车 > 电动新大巴客车 > 电池管理系统 | 部件: 电池管理系统";

BO_ 2565950195 ZT_BMS_18F14AF3: 8 Vector__XXX
 SG_ B0 : 0|8@1+ (1,0) [0|255] "" Vector__XXX
 SG_ B1 : 8|8@1+ (1,0) [0|255] "" Vector__XXX
 SG_ B2 : 16|8@1+ (1,0) [0|255] "" Vector__XXX
 SG_ B3 : 24|8@1+ (1,0) [0|255] "" Vector__XXX
 SG_ B4 : 32|8@1+ (1,0) [0|255] "" Vector__XXX
 SG_ B5 : 40|8@1+ (1,0) [0|255] "" Vector__XXX
 SG_ B6 : 48|8@1+ (1,0) [0|255] "" Vector__XXX
 SG_ B7 : 56|8@1+ (1,0) [0|255] "" Vector__XXX

BA_ "VFrameFormat" BO_ 2565950195 1;
CM_ BO_ 2565950195 "0xB3000005 中通新能源 > 纯电动客车 > 10-12米纯电公交客车 > 电池管理系统 | 0xB300006A 中通新能源 > 纯电动客车 > 电动新大巴客车 > 电池管理系统 | 部件: 电池管理系统";

BO_ 2565950451 ZT_BMS_18F14BF3: 8 Vector__XXX
 SG_ B0 : 0|8@1+ (1,0) [0|255] "" Vector__XXX
 SG_ B1 : 8|8@1+ (1,0) [0|255] "" Vector__XXX
 SG_ B2 : 16|8@1+ (1,0) [0|255] "" Vector__XXX
 SG_ B3 : 24|8@1+ (1,0) [0|255] "" Vector__XXX
 SG_ B4 : 32|8@1+ (1,0) [0|255] "" Vector__XXX
 SG_ B5 : 40|8@1+ (1,0) [0|255] "" Vector__XXX
 SG_ B6 : 48|8@1+ (1,0) [0|255] "" Vector__XXX
 SG_ B7 : 56|8@1+ (1,0) [0|255] "" Vector__XXX

BA_ "VFrameFormat" BO_ 2565950451 1;
CM_ BO_ 2565950451 "0xB3000005 中通新能源 > 纯电动客车 > 10-12米纯电公交客车 > 电池管理系统 | 0xB300006A 中通新能源 > 纯电动客车 > 电动新大巴客车 > 电池管理系统 | 部件: 电池管理系统";

BO_ 2565950707 ZT_BMS_18F14CF3: 8 Vector__XXX
 SG_ B0 : 0|8@1+ (1,0) [0|255] "" Vector__XXX
 SG_ B1 : 8|8@1+ (1,0) [0|255] "" Vector__XXX
 SG_ B2 : 16|8@1+ (1,0) [0|255] "" Vector__XXX
 SG_ B3 : 24|8@1+ (1,0) [0|255] "" Vector__XXX
 SG_ B4 : 32|8@1+ (1,0) [0|255] "" Vector__XXX
 SG_ B5 : 40|8@1+ (1,0) [0|255] "" Vector__XXX
 SG_ B6 : 48|8@1+ (1,0) [0|255] "" Vector__XXX
 SG_ B7 : 56|8@1+ (1,0) [0|255] "" Vector__XXX

BA_ "VFrameFormat" BO_ 2565950707 1;
CM_ BO_ 2565950707 "0xB3000005 中通新能源 > 纯电动客车 > 10-12米纯电公交客车 > 电池管理系统 | 0xB300006A 中通新能源 > 纯电动客车 > 电动新大巴客车 > 电池管理系统 | 部件: 电池管理系统";

BO_ 2565950963 ZT_BMS_18F14DF3: 8 Vector__XXX
 SG_ B0 : 0|8@1+ (1,0) [0|255] "" Vector__XXX
 SG_ B1 : 8|8@1+ (1,0) [0|255] "" Vector__XXX
 SG_ B2 : 16|8@1+ (1,0) [0|255] "" Vector__XXX
 SG_ B3 : 24|8@1+ (1,0) [0|255] "" Vector__XXX
 SG_ B4 : 32|8@1+ (1,0) [0|255] "" Vector__XXX
 SG_ B5 : 40|8@1+ (1,0) [0|255] "" Vector__XXX
 SG_ B6 : 48|8@1+ (1,0) [0|255] "" Vector__XXX
 SG_ B7 : 56|8@1+ (1,0) [0|255] "" Vector__XXX

BA_ "VFrameFormat" BO_ 2565950963 1;
CM_ BO_ 2565950963 "0xB3000005 中通新能源 > 纯电动客车 > 10-12米纯电公交客车 > 电池管理系统 | 0xB300006A 中通新能源 > 纯电动客车 > 电动新大巴客车 > 电池管理系统 | 部件: 电池管理系统";

BO_ 2565951219 ZT_BMS_18F14EF3: 8 Vector__XXX
 SG_ B0 : 0|8@1+ (1,0) [0|255] "" Vector__XXX
 SG_ B1 : 8|8@1+ (1,0) [0|255] "" Vector__XXX
 SG_ B2 : 16|8@1+ (1,0) [0|255] "" Vector__XXX
 SG_ B3 : 24|8@1+ (1,0) [0|255] "" Vector__XXX
 SG_ B4 : 32|8@1+ (1,0) [0|255] "" Vector__XXX
 SG_ B5 : 40|8@1+ (1,0) [0|255] "" Vector__XXX
 SG_ B6 : 48|8@1+ (1,0) [0|255] "" Vector__XXX
 SG_ B7 : 56|8@1+ (1,0) [0|255] "" Vector__XXX

BA_ "VFrameFormat" BO_ 2565951219 1;
CM_ BO_ 2565951219 "0xB3000005 中通新能源 > 纯电动客车 > 10-12米纯电公交客车 > 电池管理系统 | 0xB300006A 中通新能源 > 纯电动客车 > 电动新大巴客车 > 电池管理系统 | 部件: 电池管理系统";

BO_ 2565951475 ZT_BMS_18F14FF3: 8 Vector__XXX
 SG_ B0 : 0|8@1+ (1,0) [0|255] "" Vector__XXX
 SG_ B1 : 8|8@1+ (1,0) [0|255] "" Vector__XXX
 SG_ B2 : 16|8@1+ (1,0) [0|255] "" Vector__XXX
 SG_ B3 : 24|8@1+ (1,0) [0|255] "" Vector__XXX
 SG_ B4 : 32|8@1+ (1,0) [0|255] "" Vector__XXX
 SG_ B5 : 40|8@1+ (1,0) [0|255] "" Vector__XXX
 SG_ B6 : 48|8@1+ (1,0) [0|255] "" Vector__XXX
 SG_ B7 : 56|8@1+ (1,0) [0|255] "" Vector__XXX

BA_ "VFrameFormat" BO_ 2565951475 1;
CM_ BO_ 2565951475 "0xB3000005 中通新能源 > 纯电动客车 > 10-12米纯电公交客车 > 电池管理系统 | 0xB300006A 中通新能源 > 纯电动客车 > 电动新大巴客车 > 电池管理系统 | 部件: 电池管理系统";
